VERSION "HNNBNNNYNNNNNNNNNNNNNNNNNNNNNNNNNNNNNNNNNN/4/%%%/4/'%**4NNN///"

NS_ :

BS_:

BU_: Airbag_D4 EPB_D4 ESP_D4 Gateway_D4C7 Getriebe_AL551_951_D4_C7 Getriebe_DL501_C7 Getriebe_VL381_C7 LWS_D4 Motor_EDC17_D4 Motor_ME17_BY Motor_MED17_SIMOS8_D4 Motor_Slave_D4 QSP_D4 SAK_C7 SCR_C7 SCU_D4

BO_ 267 LS_01: 4 Gateway_D4C7
 SG_ LS_01_CHK : 0|8@1+ (1,0) [0|255] ""  Getriebe_AL551_951_D4_C7,Getriebe_DL501_C7,Getriebe_VL381_C7,Motor_EDC17_D4,Motor_ME17_BY,Motor_MED17_SIMOS8_D4
 SG_ COUNTER : 8|4@1+ (1,0) [0|15] ""  Getriebe_AL551_951_D4_C7,Getriebe_DL501_C7,Getriebe_VL381_C7,Motor_EDC17_D4,Motor_ME17_BY,Motor_MED17_SIMOS8_D4
 SG_ LS_Hauptschalter : 12|1@1+ (1.0,0.0) [0.0|1] ""  Motor_EDC17_D4,Motor_ME17_BY,Motor_MED17_SIMOS8_D4
 SG_ LS_Abbrechen : 13|1@1+ (1.0,0.0) [0.0|1] ""  Motor_EDC17_D4,Motor_ME17_BY,Motor_MED17_SIMOS8_D4
 SG_ LS_Typ_Hauptschalter : 14|1@1+ (1.0,0.0) [0.0|1] ""  Motor_EDC17_D4,Motor_ME17_BY,Motor_MED17_SIMOS8_D4
 SG_ LS_Limiter : 15|1@1+ (1.0,0.0) [0.0|1] ""  Motor_EDC17_D4,Motor_ME17_BY,Motor_MED17_SIMOS8_D4
 SG_ LS_Tip_Setzen : 16|1@1+ (1.0,0.0) [0.0|1] ""  Getriebe_DL501_C7,Motor_EDC17_D4,Motor_ME17_BY,Motor_MED17_SIMOS8_D4
 SG_ LS_Tip_Hoch : 17|1@1+ (1.0,0.0) [0.0|1] ""  Getriebe_DL501_C7,Motor_EDC17_D4,Motor_ME17_BY,Motor_MED17_SIMOS8_D4
 SG_ LS_Tip_Runter : 18|1@1+ (1.0,0.0) [0.0|1] ""  Getriebe_DL501_C7,Motor_EDC17_D4,Motor_ME17_BY,Motor_MED17_SIMOS8_D4
 SG_ LS_Tip_Wiederaufnahme : 19|1@1+ (1.0,0.0) [0.0|1] ""  Getriebe_DL501_C7,Motor_EDC17_D4,Motor_ME17_BY,Motor_MED17_SIMOS8_D4
 SG_ LS_Verstellung_Zeitluecke : 20|2@1+ (1.0,0.0) [0.0|3] ""  Vector__XXX
 SG_ MFL_Tip_Down : 22|1@1+ (1.0,0.0) [0.0|1] ""  Getriebe_AL551_951_D4_C7,Getriebe_DL501_C7,Getriebe_VL381_C7
 SG_ MFL_Tip_Up : 23|1@1+ (1.0,0.0) [0.0|1] ""  Getriebe_AL551_951_D4_C7,Getriebe_DL501_C7,Getriebe_VL381_C7
 SG_ LS_Tiptronic_Fehler : 24|1@1+ (1.0,0.0) [0.0|1] ""  Getriebe_AL551_951_D4_C7,Getriebe_DL501_C7
 SG_ LS_Fehler : 25|1@1+ (1,0) [0|1] ""  Motor_EDC17_D4,Motor_ME17_BY,Motor_MED17_SIMOS8_D4
 SG_ LS_Codierung : 26|3@1+ (1.0,0.0) [0.0|7] ""  Motor_EDC17_D4,Motor_ME17_BY,Motor_MED17_SIMOS8_D4
 SG_ LS_Tip_Stufe_2 : 29|1@1+ (1.0,0.0) [0.0|1] ""  Motor_EDC17_D4,Motor_ME17_BY,Motor_MED17_SIMOS8_D4
 SG_ LS_GRA_ACC_2stufig : 30|1@1+ (1.0,0.0) [0.0|1] ""  Motor_EDC17_D4,Motor_ME17_BY,Motor_MED17_SIMOS8_D4
 SG_ MFL_M_Taste : 31|1@1+ (1.0,0.0) [0.0|1] ""  Getriebe_AL551_951_D4_C7

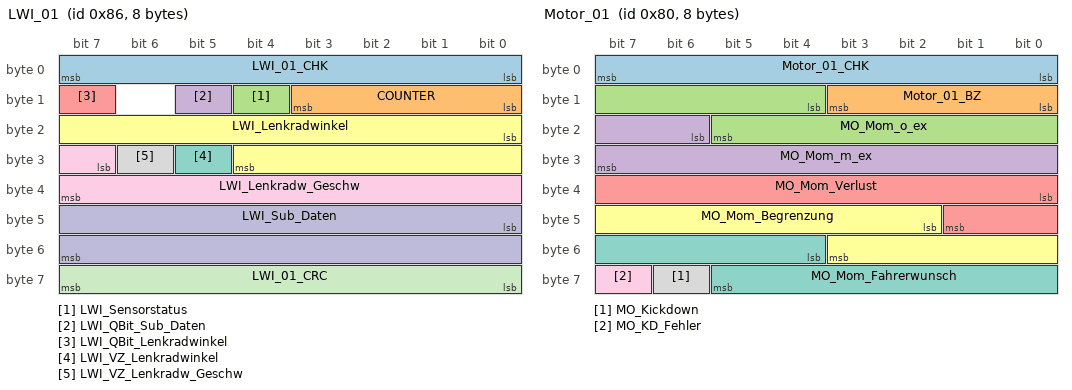
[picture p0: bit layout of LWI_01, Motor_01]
BO_ 134 LWI_01: 8 LWS_D4
 SG_ LWI_01_CHK : 0|8@1+ (1,0) [0|255] ""  ESP_D4,Gateway_D4C7,Getriebe_AL551_951_D4_C7,Getriebe_DL501_C7,Getriebe_VL381_C7,Motor_EDC17_D4,Motor_ME17_BY,Motor_MED17_SIMOS8_D4,QSP_D4,SCU_D4
 SG_ COUNTER : 8|4@1+ (1,0) [0|15] ""  Airbag_D4,ESP_D4,Gateway_D4C7,Getriebe_AL551_951_D4_C7,Getriebe_DL501_C7,Getriebe_VL381_C7,Motor_EDC17_D4,Motor_ME17_BY,Motor_MED17_SIMOS8_D4,QSP_D4,SCU_D4
 SG_ LWI_Sensorstatus : 12|1@1+ (1.0,0.0) [0.0|1] ""  ESP_D4,Gateway_D4C7,Getriebe_AL551_951_D4_C7,Motor_EDC17_D4,Motor_ME17_BY,Motor_MED17_SIMOS8_D4,QSP_D4,SCU_D4
 SG_ LWI_QBit_Sub_Daten : 13|1@1+ (1.0,0.0) [0.0|1] ""  ESP_D4,Gateway_D4C7,QSP_D4,SCU_D4
 SG_ LWI_QBit_Lenkradwinkel : 15|1@1+ (1.0,0.0) [0.0|1] ""  Airbag_D4,ESP_D4,Gateway_D4C7,Getriebe_AL551_951_D4_C7,Motor_EDC17_D4,Motor_ME17_BY,Motor_MED17_SIMOS8_D4,QSP_D4,SCU_D4
 SG_ LWI_Lenkradwinkel : 16|13@1+ (0.1,0) [0.0|800.0] "Unit_DegreOfArc"  Airbag_D4,ESP_D4,Gateway_D4C7,Getriebe_AL551_951_D4_C7,Getriebe_DL501_C7,Getriebe_VL381_C7,Motor_EDC17_D4,Motor_ME17_BY,Motor_MED17_SIMOS8_D4,QSP_D4,SCU_D4
 SG_ LWI_VZ_Lenkradwinkel : 29|1@1+ (1.0,0.0) [0.0|1] ""  Airbag_D4,ESP_D4,Gateway_D4C7,Getriebe_AL551_951_D4_C7,Motor_EDC17_D4,Motor_ME17_BY,Motor_MED17_SIMOS8_D4,QSP_D4,SCU_D4
 SG_ LWI_VZ_Lenkradw_Geschw : 30|1@1+ (1.0,0.0) [0.0|1] ""  Gateway_D4C7,QSP_D4
 SG_ LWI_Lenkradw_Geschw : 31|9@1+ (5,0) [0|2500] "Unit_DegreOfArcPerSecon"  Gateway_D4C7,QSP_D4
 SG_ LWI_Sub_Daten : 40|16@1+ (1,0) [0|65535] ""  ESP_D4,Gateway_D4C7,QSP_D4,SCU_D4
 SG_ LWI_01_CRC : 56|8@1+ (1,0) [0|255] ""  Airbag_D4,ESP_D4,Gateway_D4C7,QSP_D4,SCU_D4

BO_ 128 Motor_01: 8 Motor_EDC17_D4
 SG_ Motor_01_CHK : 0|8@1+ (1,0) [0|255] ""  EPB_D4,Gateway_D4C7,Getriebe_AL551_951_D4_C7,Getriebe_DL501_C7,Getriebe_VL381_C7
 SG_ Motor_01_BZ : 8|4@1+ (1,0) [0|15] ""  EPB_D4,Gateway_D4C7,Getriebe_AL551_951_D4_C7,Getriebe_DL501_C7,Getriebe_VL381_C7
 SG_ MO_Mom_o_ex : 12|10@1+ (1,0) [0|1021] ""  Gateway_D4C7,Getriebe_AL551_951_D4_C7,Getriebe_DL501_C7,Getriebe_VL381_C7
 SG_ MO_Mom_m_ex : 22|10@1+ (1,0) [0|1021] ""  EPB_D4,Gateway_D4C7,Getriebe_AL551_951_D4_C7,Getriebe_DL501_C7,Getriebe_VL381_C7,SAK_C7
 SG_ MO_Mom_Verlust : 32|10@1+ (1,0) [0|1021] ""  EPB_D4,Gateway_D4C7,Getriebe_AL551_951_D4_C7,Getriebe_DL501_C7,Getriebe_VL381_C7,SAK_C7
 SG_ MO_Mom_Begrenzung : 42|10@1+ (1,0) [0|1021] ""  Gateway_D4C7,Getriebe_AL551_951_D4_C7,Getriebe_DL501_C7,Getriebe_VL381_C7
 SG_ MO_Mom_Fahrerwunsch : 52|10@1+ (1,0) [0|1021] ""  Gateway_D4C7,Getriebe_AL551_951_D4_C7,Getriebe_DL501_C7,Getriebe_VL381_C7
 SG_ MO_Kickdown : 62|1@1+ (1.0,0.0) [0.0|1] ""  Gateway_D4C7,Getriebe_AL551_951_D4_C7,Getriebe_DL501_C7,Getriebe_VL381_C7
 SG_ MO_KD_Fehler : 63|1@1+ (1.0,0.0) [0.0|1] ""  Gateway_D4C7

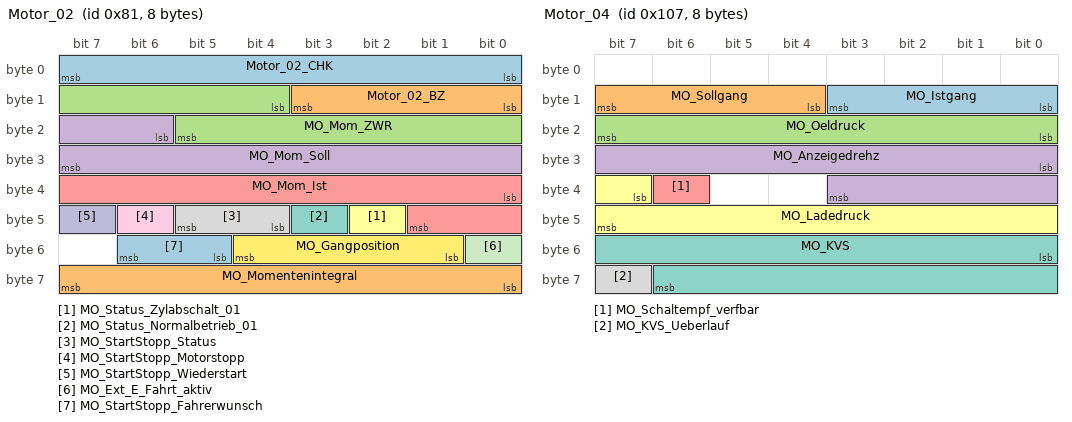
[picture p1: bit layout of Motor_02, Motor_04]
BO_ 129 Motor_02: 8 Motor_EDC17_D4
 SG_ Motor_02_CHK : 0|8@1+ (1,0) [0|255] ""  EPB_D4,Gateway_D4C7,Getriebe_AL551_951_D4_C7,Getriebe_DL501_C7,Getriebe_VL381_C7,SCU_D4
 SG_ Motor_02_BZ : 8|4@1+ (1,0) [0|15] ""  EPB_D4,Gateway_D4C7,Getriebe_AL551_951_D4_C7,Getriebe_DL501_C7,Getriebe_VL381_C7,SCU_D4
 SG_ MO_Mom_ZWR : 12|10@1+ (1,0) [0|1021] ""  Gateway_D4C7
 SG_ MO_Mom_Soll : 22|10@1+ (1,0) [0|1021] ""  Gateway_D4C7,Getriebe_AL551_951_D4_C7,Getriebe_DL501_C7,Getriebe_VL381_C7
 SG_ MO_Mom_Ist : 32|10@1+ (1,0) [0|1021] ""  Gateway_D4C7,Getriebe_AL551_951_D4_C7,Getriebe_DL501_C7,Getriebe_VL381_C7
 SG_ MO_Status_Zylabschalt_01 : 42|1@1+ (1.0,0.0) [0.0|1] ""  Gateway_D4C7,Getriebe_AL551_951_D4_C7
 SG_ MO_Status_Normalbetrieb_01 : 43|1@1+ (1.0,0.0) [0.0|1] ""  Gateway_D4C7,Getriebe_DL501_C7,Getriebe_VL381_C7
 SG_ MO_StartStopp_Status : 44|2@1+ (1.0,0.0) [0.0|3] ""  Gateway_D4C7,Getriebe_AL551_951_D4_C7,Getriebe_DL501_C7,Getriebe_VL381_C7,SCR_C7,SCU_D4
 SG_ MO_StartStopp_Motorstopp : 46|1@1+ (1.0,0.0) [0.0|1] ""  EPB_D4,Gateway_D4C7,Getriebe_AL551_951_D4_C7,Getriebe_DL501_C7,Getriebe_VL381_C7,SCR_C7,SCU_D4
 SG_ MO_StartStopp_Wiederstart : 47|1@1+ (1.0,0.0) [0.0|1] ""  EPB_D4,Gateway_D4C7,Getriebe_AL551_951_D4_C7,Getriebe_DL501_C7,Getriebe_VL381_C7,SCR_C7,SCU_D4
 SG_ MO_Ext_E_Fahrt_aktiv : 48|1@1+ (1.0,0.0) [0.0|1] ""  Gateway_D4C7
 SG_ MO_Gangposition : 49|4@1+ (1.0,0.0) [0.0|15] ""  Gateway_D4C7
 SG_ MO_StartStopp_Fahrerwunsch : 53|2@1+ (1.0,0.0) [0.0|3] ""  Gateway_D4C7
 SG_ MO_Momentenintegral : 56|8@1+ (0.3921,0) [0.0000|99.9855] ""  Gateway_D4C7,Getriebe_AL551_951_D4_C7,Getriebe_DL501_C7,Getriebe_VL381_C7

BO_ 261 Motor_03: 8 Motor_EDC17_D4
 SG_ MOTOR_03_CHK : 0|8@1+ (1,0) [0|255] ""  EPB_D4,Gateway_D4C7,Getriebe_AL551_951_D4_C7,Getriebe_DL501_C7,Getriebe_VL381_C7,SCU_D4
 SG_ COUNTER : 8|4@1+ (1,0) [0|15] ""  EPB_D4,Gateway_D4C7,Getriebe_AL551_951_D4_C7,Getriebe_DL501_C7,Getriebe_VL381_C7,SCU_D4
 SG_ MO_QBit_Fahrpedalwerte_01 : 12|1@1+ (1.0,0.0) [0.0|1] ""  EPB_D4,Gateway_D4C7,Getriebe_AL551_951_D4_C7,Getriebe_DL501_C7,Getriebe_VL381_C7
 SG_ MO_QBit_Motormomente : 13|1@1+ (1.0,0.0) [0.0|1] ""  EPB_D4,Gateway_D4C7,Getriebe_AL551_951_D4_C7,Getriebe_DL501_C7,Getriebe_VL381_C7
 SG_ MO_QBit_Fahrer_bremst : 14|1@1+ (1.0,0.0) [0.0|1] ""  Gateway_D4C7,Getriebe_AL551_951_D4_C7,Getriebe_DL501_C7,Getriebe_VL381_C7
 SG_ MO_QBit_Drehzahl_01 : 15|1@1+ (1.0,0.0) [0.0|1] ""  EPB_D4,Gateway_D4C7,Getriebe_AL551_951_D4_C7,Getriebe_DL501_C7,Getriebe_VL381_C7,SCR_C7
 SG_ MO_Drehzahl_01 : 16|16@1+ (0.25,0) [0.00|16383.00] "Unit_MinutInver"  EPB_D4,Gateway_D4C7,Getriebe_AL551_951_D4_C7,Getriebe_DL501_C7,Getriebe_VL381_C7,SAK_C7,SCR_C7,SCU_D4
 SG_ MO_Moment_im_Leerlauf : 32|1@1+ (1.0,0.0) [0.0|1] ""  Gateway_D4C7
 SG_ MO_Interlock : 33|1@1+ (1.0,0.0) [0.0|1] ""  EPB_D4,Gateway_D4C7
 SG_ MO_BLS : 34|1@1+ (1.0,0.0) [0.0|1] ""  EPB_D4,Gateway_D4C7,Getriebe_AL551_951_D4_C7,Getriebe_DL501_C7,Getriebe_VL381_C7
 SG_ MO_Fahrer_bremst : 35|1@1+ (1.0,0.0) [0.0|1] ""  Gateway_D4C7,Getriebe_AL551_951_D4_C7,Getriebe_DL501_C7,Getriebe_VL381_C7
 SG_ MO_Konsistenz_Bremsped : 36|1@1+ (1.0,0.0) [0.0|1] ""  Gateway_D4C7,Getriebe_AL551_951_D4_C7,Getriebe_DL501_C7,Getriebe_VL381_C7
 SG_ MO_Kuppl_schalter : 37|1@1+ (1.0,0.0) [0.0|1] ""  EPB_D4,Gateway_D4C7
 SG_ MO_Timeout_ESP : 38|1@1+ (1.0,0.0) [0.0|1] ""  Gateway_D4C7
 SG_ MO_Motor_laeuft : 39|1@1+ (1.0,0.0) [0.0|1] ""  Gateway_D4C7
 SG_ MO_Solldrehz_Leerlauf : 40|8@1+ (10,0) [0|2540] "Unit_MinutInver"  Gateway_D4C7,Getriebe_AL551_951_D4_C7,Getriebe_DL501_C7,Getriebe_VL381_C7
 SG_ MO_Fahrpedalrohwert_01 : 48|8@1+ (0.4,0) [0.0|101.6] "Unit_PerCent"  EPB_D4,Gateway_D4C7,Getriebe_AL551_951_D4_C7,Getriebe_DL501_C7,Getriebe_VL381_C7
 SG_ MO_erste_Ungenauschwelle : 56|1@1+ (1.0,0.0) [0.0|1] ""  Gateway_D4C7,Getriebe_AL551_951_D4_C7,Getriebe_DL501_C7,Getriebe_VL381_C7
 SG_ MO_QBit_Stressfaktor : 57|1@1+ (1.0,0.0) [0.0|1] ""  Gateway_D4C7,Getriebe_AL551_951_D4_C7,Getriebe_DL501_C7,Getriebe_VL381_C7
 SG_ MO_Stressfaktor : 58|6@1+ (1.6,0) [0.0|100.8] "Unit_PerCent"  Gateway_D4C7,Getriebe_AL551_951_D4_C7,Getriebe_DL501_C7,Getriebe_VL381_C7

BO_ 263 Motor_04: 8 Motor_EDC17_D4
 SG_ MO_Istgang : 8|4@1+ (1.0,0.0) [0.0|15] ""  Gateway_D4C7
 SG_ MO_Sollgang : 12|4@1+ (1.0,0.0) [0.0|15] ""  Gateway_D4C7
 SG_ MO_Oeldruck : 16|8@1+ (0.04,0) [0.00|10.00] "Unit_Bar"  Gateway_D4C7
 SG_ MO_Anzeigedrehz : 24|12@1+ (3,0) [0|12282] "Unit_MinutInver"  Gateway_D4C7
 SG_ MO_Schaltempf_verfbar : 38|1@1+ (1.0,0.0) [0.0|1] ""  Gateway_D4C7
 SG_ MO_Ladedruck : 39|9@1+ (0.01,0) [0.00|5.10] "Unit_Bar"  Gateway_D4C7
 SG_ MO_KVS : 48|15@1+ (1,0) [0|32767] "Unit_MicroLiter"  Gateway_D4C7
 SG_ MO_KVS_Ueberlauf : 63|1@1+ (1.0,0.0) [0.0|1] ""  Gateway_D4C7

BO_ 782 Motor_05: 8 Motor_EDC17_D4
 SG_ Motor_05_CHK : 0|8@1+ (1,0) [0|255] ""  Gateway_D4C7,Getriebe_AL551_951_D4_C7,Getriebe_DL501_C7,Getriebe_VL381_C7
 SG_ Motor_05_BZ : 8|4@1+ (1,0) [0|15] ""  Gateway_D4C7,Getriebe_AL551_951_D4_C7,Getriebe_DL501_C7,Getriebe_VL381_C7
 SG_ MO_EKlKomLeiRed : 12|2@1+ (1.0,0.0) [0.0|3] ""  Gateway_D4C7
 SG_ MO_Freig_Reku : 14|2@1+ (1.0,0.0) [0.0|3] ""  Gateway_D4C7
 SG_ MO_Klima_Eingr : 16|2@1+ (1.0,0.0) [0.0|3] ""  Gateway_D4C7
 SG_ MO_Status_Normalbetrieb_02 : 18|1@1+ (1.0,0.0) [0.0|1] ""  Gateway_D4C7
 SG_ MO_Schaltbeeinfl_Leistungsbegr : 19|1@1+ (1,0) [0|1] ""  Gateway_D4C7,Getriebe_AL551_951_D4_C7,Getriebe_DL501_C7
 SG_ MO_Schaltbeeinfl_Partikelfilter : 20|1@1+ (1,0) [0|1] ""  Gateway_D4C7,Getriebe_AL551_951_D4_C7,Getriebe_DL501_C7
 SG_ MO_Prio_MIN_Wunschdrehzahl : 21|1@1+ (1.0,0.0) [0.0|1] ""  Gateway_D4C7,Getriebe_AL551_951_D4_C7,Getriebe_DL501_C7,Getriebe_VL381_C7
 SG_ MO_Freig_Anlass : 22|1@1+ (1.0,0.0) [0.0|1] ""  Gateway_D4C7
 SG_ MO_Aussp_Anlass : 23|1@1+ (1.0,0.0) [0.0|1] ""  Gateway_D4C7
 SG_ MO_MAX_Wunschdrehzahl : 24|9@1+ (25,0) [0|12750] "Unit_MinutInver"  Gateway_D4C7,Getriebe_AL551_951_D4_C7,Getriebe_DL501_C7,Getriebe_VL381_C7
 SG_ MO_Prio_MAX_Wunschdrehzahl : 33|1@1+ (1.0,0.0) [0.0|1] ""  Gateway_D4C7,Getriebe_AL551_951_D4_C7,Getriebe_DL501_C7,Getriebe_VL381_C7
 SG_ MO_Luftpfad_aktiv : 34|1@1+ (1.0,0.0) [0.0|1] ""  Gateway_D4C7,Getriebe_AL551_951_D4_C7,Getriebe_DL501_C7
 SG_ MO_v_Begrenz_Aktiv : 35|1@1+ (1.0,0.0) [0.0|1] ""  Gateway_D4C7
 SG_ MO_v_Begrenz_Aktivierbar : 36|1@1+ (1.0,0.0) [0.0|1] ""  Gateway_D4C7
 SG_ MO_Verbot_EKP : 37|1@1+ (1.0,0.0) [0.0|1] ""  Gateway_D4C7
 SG_ MO_Anf_Pruefimpuls : 38|1@1+ (1.0,0.0) [0.0|1] ""  Gateway_D4C7
 SG_ MO_Anf_KL75 : 39|1@1+ (1.0,0.0) [0.0|1] ""  Gateway_D4C7
 SG_ MO_Charisma_FahrPr : 40|3@1+ (1.0,0.0) [0.0|7] ""  Gateway_D4C7
 SG_ MO_Charisma_Status : 43|2@1+ (1.0,0.0) [0.0|3] ""  Gateway_D4C7
 SG_ MO_Charisma_Umschaltung : 45|2@1+ (1.0,0.0) [0.0|3] ""  Gateway_D4C7
 SG_ MO_Handshake_STH : 47|1@1+ (1.0,0.0) [0.0|1] ""  Gateway_D4C7
 SG_ MO_MIN_Wunschdrehzahl : 48|8@1+ (25,0) [0|6350] "Unit_MinutInver"  Gateway_D4C7,Getriebe_AL551_951_D4_C7,Getriebe_DL501_C7,Getriebe_VL381_C7
 SG_ MO_Drehzahlbeeinflussung : 56|8@1+ (0.39,0) [0.00|99.45] "Unit_PerCent"  Gateway_D4C7,Getriebe_AL551_951_D4_C7,Getriebe_DL501_C7,Getriebe_VL381_C7

BO_ 1088 Motor_06: 8 Motor_EDC17_D4
 SG_ MO_Kuehlerluefter_MUX M  : 0|1@1+ (1.0,0.0) [0.0|1] ""  Gateway_D4C7
 SG_ MO_Kuehlerluefter_1 m0  : 1|7@1+ (1,0) [0|100] "Unit_PerCent"  Gateway_D4C7
 SG_ MO_Kuehlerluefter_2 m1  : 1|7@1+ (1,0) [0|100] "Unit_PerCent"  Gateway_D4C7
 SG_ MO_HYB_Status_HV_Ladung : 8|3@1+ (1.0,0.0) [0.0|7] ""  Gateway_D4C7
 SG_ WIV_Anzeige_aktiv : 12|1@1+ (1.0,0.0) [0.0|1] ""  Gateway_D4C7
 SG_ WIV_Oelmin_Warn : 13|1@1+ (1.0,0.0) [0.0|1] ""  Gateway_D4C7
 SG_ WIV_Sensorfehler : 14|1@1+ (1.0,0.0) [0.0|1] ""  Gateway_D4C7
 SG_ WIV_Schieflage : 15|1@1+ (1.0,0.0) [0.0|1] ""  Gateway_D4C7
 SG_ WIV_Oelstand : 16|4@1+ (12.5,0) [0.0|100.0] "Unit_PerCent"  Gateway_D4C7
 SG_ MO_Zustand_HWP : 20|2@1+ (1.0,0.0) [0.0|3] ""  Gateway_D4C7
 SG_ WIV_Oelsystem_aktiv : 24|1@1+ (1.0,0.0) [0.0|1] ""  Gateway_D4C7
 SG_ WIV_nicht_betriebswarm : 25|1@1+ (1.0,0.0) [0.0|1] ""  Gateway_D4C7
 SG_ WIV_Ueberfuell_Warn : 26|1@1+ (1.0,0.0) [0.0|1] ""  Gateway_D4C7
 SG_ WIV_laufender_Motor : 27|1@1+ (1.0,0.0) [0.0|1] ""  Gateway_D4C7
 SG_ MO_HYB_Text_1 : 28|1@1+ (1.0,0.0) [0.0|1] ""  Gateway_D4C7
 SG_ MO_HYB_Text_2 : 29|1@1+ (1.0,0.0) [0.0|1] ""  Gateway_D4C7
 SG_ MO_HYB_Text_3 : 30|1@1+ (1.0,0.0) [0.0|1] ""  Gateway_D4C7
 SG_ MO_Text_Motorstart : 32|4@1+ (1.0,0.0) [0.0|15] ""  Gateway_D4C7
 SG_ MO_HYB_Text_5 : 36|1@1+ (1.0,0.0) [0.0|1] ""  Gateway_D4C7
 SG_ MO_HYB_Text_6 : 37|1@1+ (1.0,0.0) [0.0|1] ""  Gateway_D4C7
 SG_ MO_HYB_Text_7 : 38|1@1+ (1.0,0.0) [0.0|1] ""  Gateway_D4C7
 SG_ WIV_Oeldyn_avl : 39|1@1+ (1.0,0.0) [0.0|1] ""  Gateway_D4C7
 SG_ MO_Text_MSG_Werkstatt : 40|1@1+ (1,0) [0|1] ""  Gateway_D4C7
 SG_ MO_Text_Partikelfil_Reg : 41|1@1+ (1,0) [0|1] ""  Gateway_D4C7
 SG_ MO_Text_Fehler_Kraftstoffsys : 42|1@1+ (1,0) [0|1] ""  Gateway_D4C7
 SG_ WIV_Oelmenge : 43|5@1+ (125,0) [0|3875] "Unit_MilliLiter"  Gateway_D4C7
 SG_ MO_Systemlampe : 48|1@1+ (1.0,0.0) [0.0|1] ""  Gateway_D4C7
 SG_ MO_OBD2_Lampe : 49|1@1+ (1.0,0.0) [0.0|1] ""  Gateway_D4C7
 SG_ MO_Heissleuchte : 50|1@1+ (1.0,0.0) [0.0|1] ""  Gateway_D4C7
 SG_ MO_Partikel_Lampe : 51|1@1+ (1.0,0.0) [0.0|1] ""  Gateway_D4C7
 SG_ MO_Winterfahrprog : 52|1@1+ (1,0) [0|1] ""  Gateway_D4C7
 SG_ WIV_Oelstand_nicht_vorhanden : 53|1@1+ (1.0,0.0) [0.0|1] ""  Gateway_D4C7
 SG_ WIV_nachfuellanzeige_ein : 54|1@1+ (1.0,0.0) [0.0|1] ""  Gateway_D4C7
 SG_ WIV_Ueberfuell_deaktiv : 55|1@1+ (1.0,0.0) [0.0|1] ""  Gateway_D4C7
 SG_ WIV_Unterfuell_Warn : 56|1@1+ (1.0,0.0) [0.0|1] ""  Gateway_D4C7
 SG_ MO_Tankdeckel_Lampe : 57|1@1+ (1.0,0.0) [0.0|1] ""  Gateway_D4C7
 SG_ MO_Text_Tankdeckelwarn : 58|1@1+ (1.0,0.0) [0.0|1] ""  Gateway_D4C7
 SG_ WIV_Enable_Oeldr_Motor : 59|1@1+ (1.0,0.0) [0.0|1] ""  Gateway_D4C7
 SG_ WIV_Oeldr_Warn_Motor : 60|1@1+ (1.0,0.0) [0.0|1] ""  Gateway_D4C7
 SG_ MO_Avus_Motorschutz : 61|2@1+ (1.0,0.0) [0.0|3] ""  Gateway_D4C7
 SG_ MO_HYB_Fahrbereitschaft : 63|1@1+ (1.0,0.0) [0.0|1] ""  Gateway_D4C7

BO_ 1600 Motor_07: 8 Motor_EDC17_D4
 SG_ MO_QBit_Ansaugluft_Temp : 0|1@1+ (1.0,0.0) [0.0|1] ""  Gateway_D4C7,Getriebe_AL551_951_D4_C7,Getriebe_DL501_C7,Getriebe_VL381_C7
 SG_ MO_QBit_Oel_Temp : 1|1@1+ (1.0,0.0) [0.0|1] ""  Gateway_D4C7,Getriebe_AL551_951_D4_C7
 SG_ MO_QBit_Kuehlmittel_Temp : 2|1@1+ (1.0,0.0) [0.0|1] ""  Gateway_D4C7,Getriebe_AL551_951_D4_C7,Getriebe_DL501_C7,Getriebe_VL381_C7
 SG_ MO_Stellgliedtest_Soundaktuator : 3|1@1+ (1.0,0.0) [0.0|1] ""  Gateway_D4C7
 SG_ MO_HYB_Fehler_HV_Netz : 4|1@1+ (1.0,0.0) [0.0|1] ""  Gateway_D4C7
 SG_ MO_aktives_Getriebeheizen : 5|1@1+ (1.0,0.0) [0.0|1] ""  Gateway_D4C7,Getriebe_AL551_951_D4_C7,Getriebe_DL501_C7,Getriebe_VL381_C7
 SG_ MO_Absperrventil_oeffnen : 6|2@1+ (1.0,0.0) [0.0|3] ""  Gateway_D4C7
 SG_ MO_Ansaugluft_Temp : 8|8@1+ (0.75,-48) [-48.00|141.75] "Unit_DegreCelsi"  Gateway_D4C7,Getriebe_AL551_951_D4_C7,Getriebe_DL501_C7,Getriebe_VL381_C7
 SG_ MO_Oel_Temp : 16|8@1+ (1,-60) [-60|192] "Unit_DegreCelsi"  Gateway_D4C7,Getriebe_AL551_951_D4_C7
 SG_ MO_Kuehlmittel_Temp : 24|8@1+ (0.75,-48) [-48.00|141.75] "Unit_DegreCelsi"  Gateway_D4C7,Getriebe_AL551_951_D4_C7,Getriebe_DL501_C7,Getriebe_VL381_C7
 SG_ MO_Hoeheninfo : 32|8@1+ (0.00781,0) [0.00000|1.98374] ""  Gateway_D4C7,Getriebe_AL551_951_D4_C7,Getriebe_DL501_C7,Getriebe_VL381_C7
 SG_ MO_Kennfeldk : 40|1@1+ (1.0,0.0) [0.0|1] ""  Gateway_D4C7
 SG_ MO_Versionsinfo : 41|6@1+ (1.0,0.0) [0.0|63] ""  Gateway_D4C7
 SG_ MO_Getriebe_kuehlen : 47|1@1+ (1.0,0.0) [0.0|1] ""  Gateway_D4C7,Getriebe_AL551_951_D4_C7,Getriebe_DL501_C7,Getriebe_VL381_C7
 SG_ MO_Mom_Traegheit_02 : 48|5@1+ (0.01,0) [0.00|0.31] "Unit_KiloGramMeterSquar"  Gateway_D4C7,Getriebe_AL551_951_D4_C7,Getriebe_DL501_C7,Getriebe_VL381_C7
 SG_ MO_Heizungspumpenansteuerung : 53|4@1+ (10,0) [0|100] "Unit_PerCent"  Gateway_D4C7
 SG_ MO_SpannungsAnf : 57|1@1+ (1.0,0.0) [0.0|1] ""  Gateway_D4C7
 SG_ MO_Nachlaufzeit_Heizungspumpe : 58|6@1+ (15,0) [0|945] "Unit_Secon"  Gateway_D4C7

BO_ 1607 Motor_09: 8 Motor_EDC17_D4
 SG_ MO_ITM_Kuehlmittel_Temp : 0|8@1+ (0.75,-48) [-45.75|143.25] "Unit_DegreCelsi"  Gateway_D4C7
 SG_ MO_E85_Sensor : 8|4@1+ (10,0) [0|100] "Unit_PerCent"  Gateway_D4C7
 SG_ SCR_Anz_Motorstarts : 12|4@1+ (1,0) [0|8] ""  Gateway_D4C7
 SG_ SCR_Reichweite : 16|15@1+ (1,0) [0|32766] ""  Gateway_D4C7
 SG_ SCR_Warnstufe_1 : 32|1@1+ (1.0,0.0) [0.0|1] ""  Gateway_D4C7
 SG_ SCR_Warnstufe_2 : 33|1@1+ (1.0,0.0) [0.0|1] ""  Gateway_D4C7
 SG_ SCR_Text : 34|3@1+ (1.0,0.0) [0.0|7] ""  Gateway_D4C7
 SG_ SCR_Akustik : 37|2@1+ (1.0,0.0) [0.0|3] ""  Gateway_D4C7
 SG_ MO_Kraftstofffilter_Wasser : 40|1@1+ (1.0,0.0) [0.0|1] ""  Gateway_D4C7
 SG_ SCR_Systemfehler : 41|1@1+ (1.0,0.0) [0.0|1] ""  Gateway_D4C7
 SG_ SCR_Inducement_Strategie : 42|2@1+ (1.0,0.0) [0.0|3] ""  Gateway_D4C7
 SG_ MO_CO2_Faktor : 44|12@1+ (1,0) [1|4094] "Unit_GramPerLiter"  Gateway_D4C7
 SG_ MO_MKB_MUX M  : 56|2@1+ (1.0,0.0) [0.0|3] ""  Gateway_D4C7
 SG_ MO_MKB_01 m0  : 59|5@1+ (1.0,0.0) [0.0|31] ""  Gateway_D4C7
 SG_ MO_MKB_02 m1  : 59|5@1+ (1.0,0.0) [0.0|31] ""  Gateway_D4C7
 SG_ MO_MKB_03 m2  : 59|5@1+ (1.0,0.0) [0.0|31] ""  Gateway_D4C7
 SG_ MO_MKB_04 m3  : 59|5@1+ (1.0,0.0) [0.0|31] ""  Gateway_D4C7

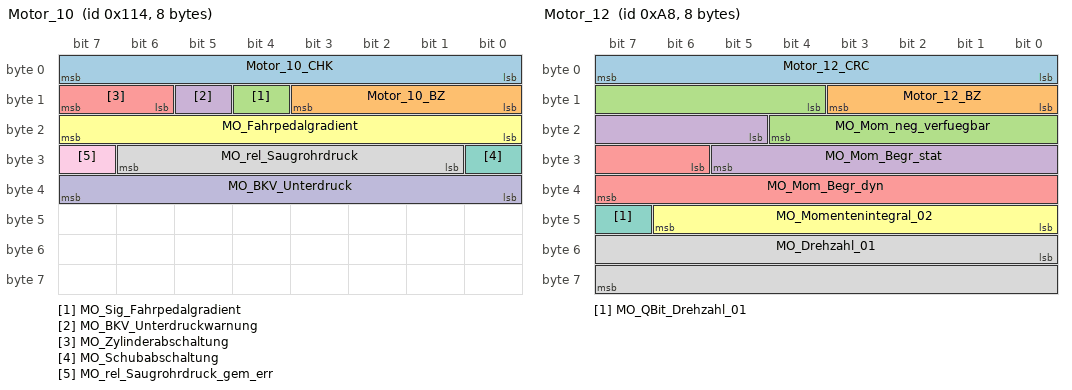
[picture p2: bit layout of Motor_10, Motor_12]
BO_ 276 Motor_10: 8 Motor_EDC17_D4
 SG_ Motor_10_CHK : 0|8@1+ (1,0) [0|255] ""  Gateway_D4C7
 SG_ Motor_10_BZ : 8|4@1+ (1,0) [0|15] ""  Gateway_D4C7
 SG_ MO_Sig_Fahrpedalgradient : 12|1@1+ (1.0,0.0) [0.0|1] ""  Gateway_D4C7
 SG_ MO_BKV_Unterdruckwarnung : 13|1@1+ (1.0,0.0) [0.0|1] ""  Gateway_D4C7
 SG_ MO_Zylinderabschaltung : 14|2@1+ (1.0,0.0) [0.0|3] ""  Gateway_D4C7,Getriebe_AL551_951_D4_C7,Getriebe_DL501_C7
 SG_ MO_Fahrpedalgradient : 16|8@1+ (25,0) [0|6350] "Unit_PerCentPerSecon"  Gateway_D4C7
 SG_ MO_Schubabschaltung : 24|1@1+ (1.0,0.0) [0.0|1] ""  Gateway_D4C7
 SG_ MO_rel_Saugrohrdruck : 25|6@1+ (18,0) [0|1116] "Unit_MilliBar"  Gateway_D4C7
 SG_ MO_rel_Saugrohrdruck_gem_err : 31|1@1+ (1.0,0.0) [0.0|1] ""  Gateway_D4C7
 SG_ MO_BKV_Unterdruck : 32|8@1+ (4,0) [0|1012] "Unit_MilliBar"  Gateway_D4C7

BO_ 168 Motor_12: 8 Motor_MLB_C7_PHEV
 SG_ Motor_12_CRC : 0|8@1+ (1,0) [0|255] ""  Gateway
 SG_ Motor_12_BZ : 8|4@1+ (1,0) [0|15] ""  Gateway
 SG_ MO_Mom_neg_verfuegbar : 12|9@1+ (1,-509) [-509|0] ""  Gateway
 SG_ MO_Mom_Begr_stat : 21|9@1+ (1,0) [0|509] ""  Gateway
 SG_ MO_Mom_Begr_dyn : 30|10@1+ (1,-509) [-509|509] ""  Gateway
 SG_ MO_Momentenintegral_02 : 40|7@1+ (1,0) [0|100] "Unit_PerCent"  Gateway
 SG_ MO_QBit_Drehzahl_01 : 47|1@1+ (1,0) [0|1] ""  Gateway
 SG_ MO_Drehzahl_01 : 48|16@1+ (0.25,0) [0|16383] "Unit_MinutInver"  Gateway

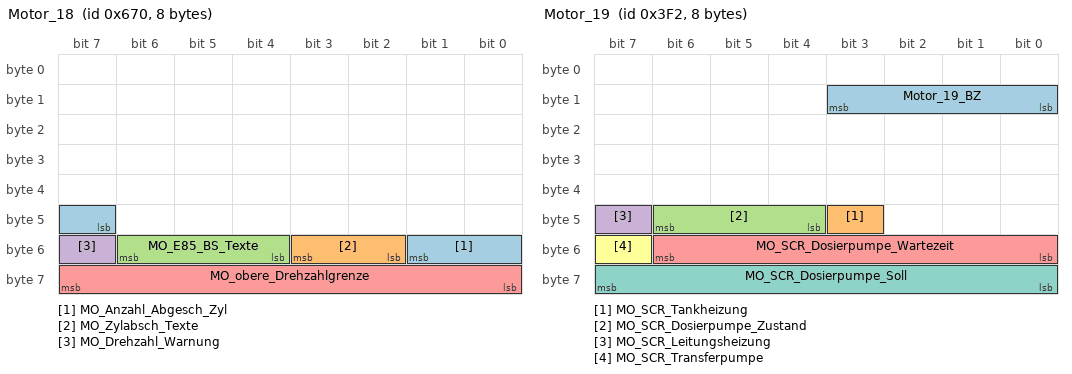
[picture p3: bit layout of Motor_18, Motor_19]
BO_ 1648 Motor_18: 8 Motor_EDC17_D4
 SG_ MO_Anzahl_Abgesch_Zyl : 47|3@1+ (1.0,0.0) [0.0|7] ""  Gateway_D4C7,Getriebe_AL551_951_D4_C7,Getriebe_DL501_C7
 SG_ MO_Zylabsch_Texte : 50|2@1+ (1.0,0.0) [0.0|3] ""  Gateway_D4C7
 SG_ MO_E85_BS_Texte : 52|3@1+ (1.0,0.0) [0.0|7] ""  Gateway_D4C7
 SG_ MO_Drehzahl_Warnung : 55|1@1+ (1.0,0.0) [0.0|1] ""  Gateway_D4C7
 SG_ MO_obere_Drehzahlgrenze : 56|8@1+ (50,0) [50|12750] "Unit_MinutInver"  Gateway_D4C7

BO_ 1010 Motor_19: 8 Motor_EDC17_D4
 SG_ Motor_19_BZ : 8|4@1+ (1,0) [0|15] ""  SCR_C7
 SG_ MO_SCR_Tankheizung : 43|1@1+ (1.0,0.0) [0.0|1] ""  SCR_C7
 SG_ MO_SCR_Dosierpumpe_Zustand : 44|3@1+ (1.0,0.0) [0.0|7] ""  SCR_C7
 SG_ MO_SCR_Leitungsheizung : 47|1@1+ (1.0,0.0) [0.0|1] ""  SCR_C7
 SG_ MO_SCR_Dosierpumpe_Wartezeit : 48|7@1+ (1,0) [0|120] "Unit_Secon"  SCR_C7
 SG_ MO_SCR_Transferpumpe : 55|1@1+ (1.0,0.0) [0.0|1] ""  SCR_C7
 SG_ MO_SCR_Dosierpumpe_Soll : 56|8@1+ (0.4,0) [0.0|100.0] "Unit_PerCent"  SCR_C7

BO_ 815 Motor_23: 8 Motor_MLB_AU64_AU57_Diesel
 SG_ MO_Antriebsstrang_Warnung_HS : 46|2@1+ (1,0) [0|3] ""  Gateway
 SG_ MO_Anzeige_Verbrauch : 48|16@1+ (0.005,0) [0|327.675] "Unit_LiterPerHour"  Gateway

BO_ 1391 Motor_25: 8 Motor_MLB_AU64_AU57_Diesel
 SG_ MO_IstLeistung_EKAT : 41|7@1+ (20,0) [0|2500] "Unit_Watt"  Gateway
 SG_ MO_HYB_Drehzahl_VM : 48|16@1+ (0.25,0) [0|16256] "Unit_MinutInver"  Gateway,Getriebe_AL551_Hybrid_D4_C7

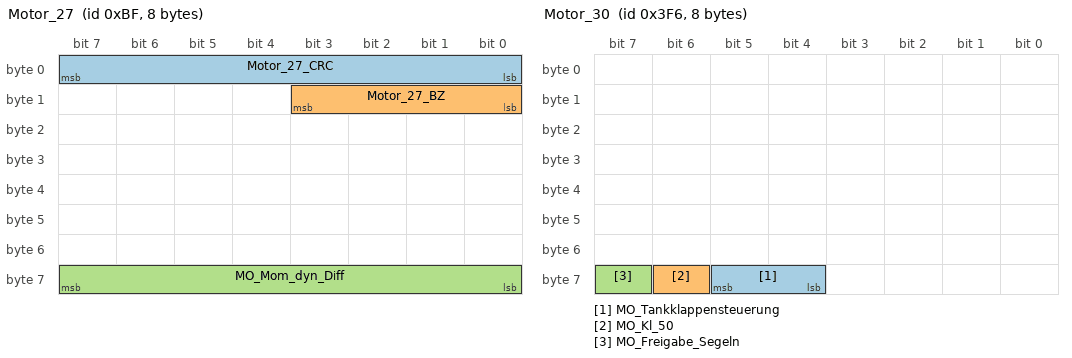
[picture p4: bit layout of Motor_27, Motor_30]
BO_ 191 Motor_27: 8 Motor_MLB_AU64_AU57_Diesel
 SG_ Motor_27_CRC : 0|8@1+ (1,0) [0|255] ""  Getriebe_AL551_951_D4_C7,Getriebe_AL551_Hybrid_D4_C7,Getriebe_DL382_MLB,Getriebe_DL501_MLB,Getriebe_VL381_MLB
 SG_ Motor_27_BZ : 8|4@1+ (1,0) [0|15] ""  Getriebe_AL551_951_D4_C7,Getriebe_AL551_Hybrid_D4_C7,Getriebe_DL382_MLB,Getriebe_DL501_MLB,Getriebe_VL381_MLB
 SG_ MO_Mom_dyn_Diff : 56|8@1+ (1,-25) [-25|229] "Unit_NewtoMeter"  Getriebe_AL551_951_D4_C7,Getriebe_AL551_Hybrid_D4_C7,Getriebe_DL382_MLB,Getriebe_DL501_MLB,Getriebe_VL381_MLB

BO_ 1014 Motor_30: 8 Motor_MLB_AU64_AU57_Diesel
 SG_ MO_Tankklappensteuerung : 60|2@1+ (1,0) [0|3] ""  Gateway
 SG_ MO_Kl_50 : 62|1@1+ (1,0) [0|1] ""  Getriebe_AL551_951_D4_C7
 SG_ MO_Freigabe_Segeln : 63|1@1+ (1,0) [0|1] ""  Getriebe_AL551_951_D4_C7,Getriebe_DL382_MLB,Getriebe_DL501_MLB

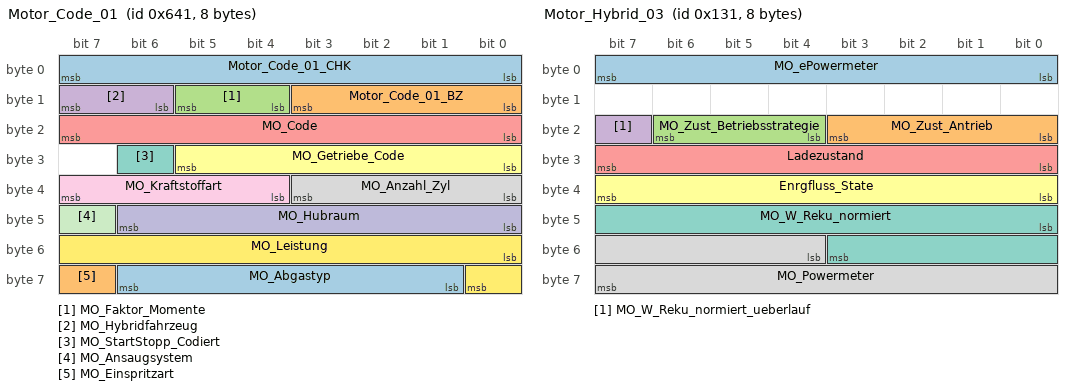
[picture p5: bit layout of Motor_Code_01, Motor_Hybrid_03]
BO_ 1601 Motor_Code_01: 8 Motor_EDC17_D4
 SG_ Motor_Code_01_CHK : 0|8@1+ (1,0) [0|255] ""  Gateway_D4C7,Getriebe_AL551_951_D4_C7,Getriebe_DL501_C7,Getriebe_VL381_C7
 SG_ Motor_Code_01_BZ : 8|4@1+ (1,0) [0|15] ""  Gateway_D4C7,Getriebe_AL551_951_D4_C7,Getriebe_DL501_C7,Getriebe_VL381_C7
 SG_ MO_Faktor_Momente : 12|2@1+ (1.0,0.0) [0.0|3] ""  EPB_D4,Gateway_D4C7,Getriebe_AL551_951_D4_C7,Getriebe_DL501_C7,Getriebe_VL381_C7
 SG_ MO_Hybridfahrzeug : 14|2@1+ (1.0,0.0) [0.0|3] ""  Gateway_D4C7
 SG_ MO_Code : 16|8@1+ (1,0) [0|255] ""  EPB_D4,Gateway_D4C7,Getriebe_AL551_951_D4_C7,Getriebe_DL501_C7,Getriebe_VL381_C7,SAK_C7
 SG_ MO_Getriebe_Code : 24|6@1+ (1.0,0.0) [0.0|63] ""  EPB_D4,Gateway_D4C7,Getriebe_AL551_951_D4_C7,Getriebe_DL501_C7,Getriebe_VL381_C7
 SG_ MO_StartStopp_Codiert : 30|1@1+ (1.0,0.0) [0.0|1] ""  Gateway_D4C7
 SG_ MO_Anzahl_Zyl : 32|4@1+ (1,0) [0|15] ""  Gateway_D4C7
 SG_ MO_Kraftstoffart : 36|4@1+ (1.0,0.0) [0.0|15] ""  EPB_D4,Gateway_D4C7
 SG_ MO_Hubraum : 40|7@1+ (0.1,0) [0.0|12.7] "Unit_Liter"  Gateway_D4C7
 SG_ MO_Ansaugsystem : 47|1@1+ (1.0,0.0) [0.0|1] ""  EPB_D4,Gateway_D4C7
 SG_ MO_Leistung : 48|9@1+ (1,0) [0|511] "Unit_KiloWatt"  Gateway_D4C7
 SG_ MO_Abgastyp : 57|6@1+ (1.0,0.0) [0.0|63] ""  Gateway_D4C7,Getriebe_AL551_951_D4_C7
 SG_ MO_Einspritzart : 63|1@1+ (1.0,0.0) [0.0|1] ""  Gateway_D4C7

BO_ 305 Motor_Hybrid_03: 8 Motor_MLB_C7_PHEV
 SG_ MO_ePowermeter : 0|8@1+ (0.4,-0.4) [0|100.8] "Unit_PerCent"  Gateway
 SG_ MO_Zust_Antrieb : 16|4@1+ (1,0) [0|15] ""  Gateway
 SG_ MO_Zust_Betriebsstrategie : 20|3@1+ (1,0) [0|7] ""  Gateway
 SG_ MO_W_Reku_normiert_ueberlauf : 23|1@1+ (1,0) [0|1] ""  Gateway
 SG_ Ladezustand : 24|8@1+ (1,0) [0|100] "Unit_PerCent"  Gateway
 SG_ Enrgfluss_State : 32|8@1+ (1,0) [0|255] ""  Gateway
 SG_ MO_W_Reku_normiert : 40|12@1+ (10,0) [0|40950] "Unit_WattSecond"  Gateway
 SG_ MO_Powermeter : 52|12@1+ (1,0) [0|4092] ""  Gateway

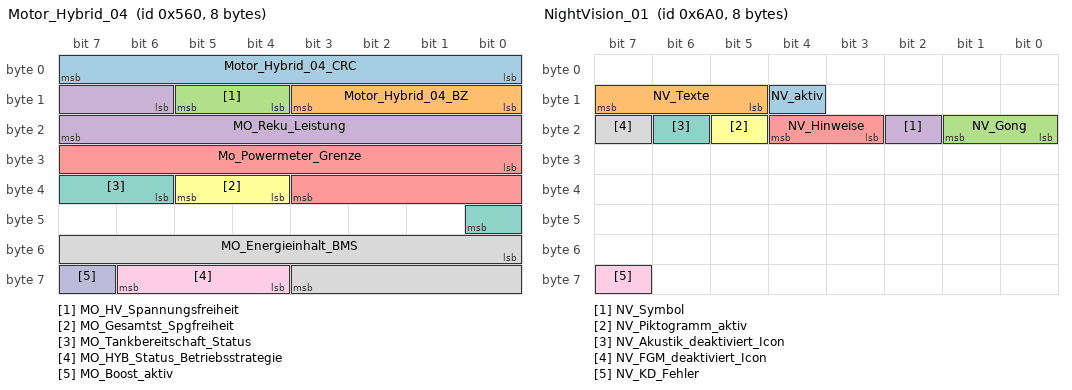
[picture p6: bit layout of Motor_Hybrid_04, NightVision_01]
BO_ 1376 Motor_Hybrid_04: 8 Motor_MLB_C7_PHEV
 SG_ Motor_Hybrid_04_CRC : 0|8@1+ (1,0) [0|255] ""  Gateway
 SG_ Motor_Hybrid_04_BZ : 8|4@1+ (1,0) [0|15] ""  Gateway
 SG_ MO_HV_Spannungsfreiheit : 12|2@1+ (1,0) [0|3] ""  Gateway
 SG_ MO_Reku_Leistung : 14|10@1+ (10,0) [0|10230] "Unit_Watt"  Gateway
 SG_ Mo_Powermeter_Grenze : 24|12@1+ (1,0) [0|4092] ""  Gateway
 SG_ MO_Gesamtst_Spgfreiheit : 36|2@1+ (1,0) [0|3] ""  Gateway
 SG_ MO_Tankbereitschaft_Status : 38|3@1+ (1,0) [0|7] ""  Gateway
 SG_ MO_Energieinhalt_BMS : 48|12@1+ (25,0) [0|102325] "Unit_WattHour"  Gateway
 SG_ MO_HYB_Status_Betriebsstrategie : 60|3@1+ (1,0) [0|7] ""  Gateway
 SG_ MO_Boost_aktiv : 63|1@1+ (1,0) [0|1] ""  Gateway

BO_ 969 MotorSlave_01: 1 Motor_Slave_D4
 SG_ MOS_KD_Fehler : 0|1@1+ (1.0,0.0) [0.0|1] ""  Gateway_D4C7

BO_ 1696 NightVision_01: 8 Gateway_D4C7
 SG_ NV_aktiv : 12|1@1+ (1.0,0.0) [0.0|1] ""  Airbag_D4
 SG_ NV_Texte : 13|3@1+ (1.0,0.0) [0.0|7] ""  Vector__XXX
 SG_ NV_Gong : 16|2@1+ (1.0,0.0) [0.0|3] ""  Airbag_D4
 SG_ NV_Symbol : 18|1@1+ (1.0,0.0) [0.0|1] ""  Airbag_D4
 SG_ NV_Hinweise : 19|2@1+ (1.0,0.0) [0.0|3] ""  Vector__XXX
 SG_ NV_Piktogramm_aktiv : 21|1@1+ (1.0,0.0) [0.0|1] ""  Vector__XXX
 SG_ NV_Akustik_deaktiviert_Icon : 22|1@1+ (1.0,0.0) [0.0|1] ""  Vector__XXX
 SG_ NV_FGM_deaktiviert_Icon : 23|1@1+ (1.0,0.0) [0.0|1] ""  Vector__XXX
 SG_ NV_KD_Fehler : 63|1@1+ (1.0,0.0) [0.0|1] ""  Vector__XXX

BO_ 1742 NMH_BMS: 7 BMS_Hybrid
 SG_ NMH_BMS_Start_1 : 0|1@1+ (1,0) [0|1] ""  BMS_Hybrid,EPB_MLB,Gateway,Getriebe_AL551_951_D4_C7,Getriebe_AL551_Hybrid_D4_C7,Getriebe_DL382_MLB,Getriebe_DL501_MLB,Getriebe_VL381_MLB,LEH_Hybrid,Motor2_MLB_D4_C7,Motor_MLB_AU64_AU57_Diesel,Motor_MLB_BY_Otto,Motor_MLB_C7_PHEV,Motor_MLB_D4_C7_Hybrid,Motor_MLB_D4_C7_Otto,SCR_MLB
 SG_ NMH_BMS_Start_2 : 1|1@1+ (1,0) [0|1] "" Vector__XXX
 SG_ NMH_BMS_Normal_Mode_1 : 2|1@1+ (1,0) [0|1] "" Vector__XXX
 SG_ NMH_BMS_Normal_Mode_2 : 3|1@1+ (1,0) [0|1] "" Vector__XXX
 SG_ NMH_BMS_Car_WakeUp : 6|1@1+ (1,0) [0|1] "" Vector__XXX
 SG_ NMH_BMS_Per_WakeUp : 8|5@1+ (1,0) [0|31] "" Vector__XXX
 SG_ NMH_BMS_Fkt_WakeUp : 13|3@1+ (1,0) [0|7] "" Vector__XXX
 SG_ NMH_BMS_Klemme_15 : 16|1@1+ (1,0) [0|1] "" Vector__XXX
 SG_ NMH_BMS_Diagnose : 17|1@1+ (1,0) [0|1] "" Vector__XXX
 SG_ NMH_BMS_MindestAktivZeit : 18|1@1+ (1,0) [0|1] "" Vector__XXX
 SG_ NMH_BMS_NL_Daten_EEPROM : 24|1@1+ (1,0) [0|1] "" Vector__XXX
 SG_ NMH_BMS_NL_Luefter : 25|1@1+ (1,0) [0|1] "" Vector__XXX
 SG_ NMH_BMS_Signalfehler : 32|1@1+ (1,0) [0|1] "" Vector__XXX
 SG_ NMH_BMS_TimeOut_Fehler : 33|1@1+ (1,0) [0|1] "" Vector__XXX
 SG_ NMH_BMS_CAN_Diag_deaktiv : 34|1@1+ (1,0) [0|1] "" Vector__XXX
 SG_ NMH_BMS_KompSchutz : 35|1@1+ (1,0) [0|1] "" Vector__XXX
 SG_ NMH_BMS_Mute_Mode : 36|1@1+ (1,0) [0|1] "" Vector__XXX
 SG_ NMH_BMS_Transport_Mode : 37|1@1+ (1,0) [0|1] "" Vector__XXX
 SG_ NMH_BMS_Abschaltstufe_aktiv : 38|1@1+ (1,0) [0|1] "" Vector__XXX
 SG_ NMH_BMS_Busfehler : 39|1@1+ (1,0) [0|1] "" Vector__XXX
 SG_ NMH_BMS_Lokalaktiv : 48|1@1+ (1,0) [0|1] "" Vector__XXX
 SG_ NMH_BMS_Subsystemaktiv : 49|1@1+ (1,0) [0|1] "" Vector__XXX

BO_ 1743 NMH_EM: 7 LEH_Hybrid
 SG_ NMH_EM_Start_1 : 0|1@1+ (1,0) [0|1] ""  BMS_Hybrid,EPB_MLB,Gateway,Getriebe_AL551_951_D4_C7,Getriebe_AL551_Hybrid_D4_C7,Getriebe_DL382_MLB,Getriebe_DL501_MLB,Getriebe_VL381_MLB,LEH_Hybrid,Motor2_MLB_D4_C7,Motor_MLB_AU64_AU57_Diesel,Motor_MLB_BY_Otto,Motor_MLB_C7_PHEV,Motor_MLB_D4_C7_Hybrid,Motor_MLB_D4_C7_Otto,SCR_MLB
 SG_ NMH_EM_Start_2 : 1|1@1+ (1,0) [0|1] "" Vector__XXX
 SG_ NMH_EM_Normal_Mode_1 : 2|1@1+ (1,0) [0|1] "" Vector__XXX
 SG_ NMH_EM_Normal_Mode_2 : 3|1@1+ (1,0) [0|1] "" Vector__XXX
 SG_ NMH_EM_Car_WakeUp : 6|1@1+ (1,0) [0|1] "" Vector__XXX
 SG_ NMH_EM_Per_WakeUp : 8|5@1+ (1,0) [0|31] "" Vector__XXX
 SG_ NMH_EM_Fkt_WakeUp : 13|3@1+ (1,0) [0|7] "" Vector__XXX
 SG_ NMH_EM_Klemme_15 : 16|1@1+ (1,0) [0|1] "" Vector__XXX
 SG_ NMH_EM_Diagnose : 17|1@1+ (1,0) [0|1] "" Vector__XXX
 SG_ NMH_EM_MindestAktivZeit : 18|1@1+ (1,0) [0|1] "" Vector__XXX
 SG_ NMH_EM_keine_HV_Entl : 19|1@1+ (1,0) [0|1] "" Vector__XXX
 SG_ NMH_EM_NL_Datem_EEPROM : 24|1@1+ (1,0) [0|1] "" Vector__XXX
 SG_ NMH_EM_Signalfehler : 32|1@1+ (1,0) [0|1] "" Vector__XXX
 SG_ NMH_EM_TimeOut_Fehler : 33|1@1+ (1,0) [0|1] "" Vector__XXX
 SG_ NMH_EM_CAN_Diag_deaktiv : 34|1@1+ (1,0) [0|1] "" Vector__XXX
 SG_ NMH_EM_KompSchutz : 35|1@1+ (1,0) [0|1] "" Vector__XXX
 SG_ NMH_EM_Mute_Mode : 36|1@1+ (1,0) [0|1] "" Vector__XXX
 SG_ NMH_EM_Transport_Mode : 37|1@1+ (1,0) [0|1] "" Vector__XXX
 SG_ NMH_EM_Abschaltstufe_aktiv : 38|1@1+ (1,0) [0|1] "" Vector__XXX
 SG_ NMH_EM_Busfehler : 39|1@1+ (1,0) [0|1] "" Vector__XXX
 SG_ NMH_EM_Lokalaktiv : 48|1@1+ (1,0) [0|1] "" Vector__XXX
 SG_ NMH_EM_Subsystemaktiv : 49|1@1+ (1,0) [0|1] "" Vector__XXX

BO_ 1753 NMH_EPB: 7 EPB_D4
 SG_ NMH_EPB_Start_1 : 0|1@1+ (1.0,0.0) [0.0|1] ""  EPB_D4,Gateway_D4C7,Getriebe_AL551_951_D4_C7,Getriebe_DL501_C7,Getriebe_VL381_C7,Motor_EDC17_D4,Motor_ME17_BY,Motor_MED17_SIMOS8_D4,Motor_Slave_D4,SCR_C7
 SG_ NMH_EPB_Start_2 : 1|1@1+ (1.0,0.0) [0.0|1] ""  Vector__XXX
 SG_ NMH_EPB_Normal_Mode_1 : 2|1@1+ (1.0,0.0) [0.0|1] ""  Vector__XXX
 SG_ NMH_EPB_Normal_Mode_2 : 3|1@1+ (1.0,0.0) [0.0|1] ""  Vector__XXX
 SG_ NMH_EPB_Car_WakeUp : 6|1@1+ (1.0,0.0) [0.0|1] ""  Vector__XXX
 SG_ NMH_EPB_Per_WakeUp : 8|5@1+ (1.0,0.0) [0.0|31] ""  Vector__XXX
 SG_ NMH_EPB_Fkt_WakeUp : 13|3@1+ (1.0,0.0) [0.0|7] ""  Vector__XXX
 SG_ NMH_EPB_NM_aktiv_Klemme_15 : 16|1@1+ (1.0,0.0) [0.0|1] ""  Vector__XXX
 SG_ NMH_EPB_NM_aktiv_Diagnose : 17|1@1+ (1.0,0.0) [0.0|1] ""  Vector__XXX
 SG_ NMH_EPB_NM_aktiv_Start : 18|1@1+ (1.0,0.0) [0.0|1] ""  Vector__XXX
 SG_ NMH_EPB_NM_aktiv_Schalter : 19|1@1+ (1.0,0.0) [0.0|1] ""  Vector__XXX
 SG_ NMH_EPB_NM_aktiv_Bedarf_Anzeige : 20|1@1+ (1.0,0.0) [0.0|1] ""  Vector__XXX
 SG_ NMH_EPB_NM_aktiv_v_groesser_Null : 21|1@1+ (1.0,0.0) [0.0|1] ""  Vector__XXX
 SG_ NMH_EPB_kein_NL : 24|1@1+ (1.0,0.0) [0.0|1] ""  Vector__XXX
 SG_ NMH_EPB_NL_Temp_Modell : 25|1@1+ (1.0,0.0) [0.0|1] ""  Vector__XXX
 SG_ NMH_EPB_NL_Min : 26|1@1+ (1.0,0.0) [0.0|1] ""  Vector__XXX
 SG_ NMH_EPB_NL_AutoAdjust : 27|1@1+ (1.0,0.0) [0.0|1] ""  Vector__XXX
 SG_ NM_EPB_Signalfehler : 32|1@1+ (1.0,0.0) [0.0|1] ""  Vector__XXX
 SG_ NMH_EPB_TimeOut_Fehler : 33|1@1+ (1.0,0.0) [0.0|1] ""  Vector__XXX
 SG_ NMH_EPB_CAN_Diag_deaktiv : 34|1@1+ (1.0,0.0) [0.0|1] ""  Vector__XXX
 SG_ NMH_EPB_KompSchutz : 35|1@1+ (1.0,0.0) [0.0|1] ""  Vector__XXX
 SG_ NMH_EPB_Mute_Mode : 36|1@1+ (1.0,0.0) [0.0|1] ""  Vector__XXX
 SG_ NMH_EPB_Transport_Mode : 37|1@1+ (1.0,0.0) [0.0|1] ""  Vector__XXX
 SG_ NMH_EPB_Abschaltstufe_aktiv : 38|1@1+ (1.0,0.0) [0.0|1] ""  Vector__XXX
 SG_ NMH_EPB_Eindraht_Fehler : 39|1@1+ (1.0,0.0) [0.0|1] ""  Vector__XXX
 SG_ NMH_EPB_Lokalaktiv : 48|1@1+ (1.0,0.0) [0.0|1] ""  Vector__XXX
 SG_ NMH_EPB_Subsystemaktiv : 49|1@1+ (1.0,0.0) [0.0|1] ""  Vector__XXX

BO_ 1728 NMH_Gateway: 7 Gateway_D4C7
 SG_ NMH_GW_Start_1 : 0|1@1+ (1.0,0.0) [0.0|1] ""  EPB_D4,Gateway_D4C7,Getriebe_AL551_951_D4_C7,Getriebe_DL501_C7,Getriebe_VL381_C7,Motor_EDC17_D4,Motor_ME17_BY,Motor_MED17_SIMOS8_D4,Motor_Slave_D4,SCR_C7
 SG_ NMH_GW_Start_2 : 1|1@1+ (1.0,0.0) [0.0|1] ""  EPB_D4,Gateway_D4C7,Getriebe_AL551_951_D4_C7,Getriebe_DL501_C7,Getriebe_VL381_C7,Motor_EDC17_D4,Motor_ME17_BY,Motor_MED17_SIMOS8_D4,Motor_Slave_D4,SCR_C7
 SG_ NMH_GW_Normal_Mode_1 : 2|1@1+ (1.0,0.0) [0.0|1] ""  EPB_D4,Gateway_D4C7,Getriebe_AL551_951_D4_C7,Getriebe_DL501_C7,Getriebe_VL381_C7,Motor_EDC17_D4,Motor_ME17_BY,Motor_MED17_SIMOS8_D4,Motor_Slave_D4,SCR_C7
 SG_ NMH_GW_Normal_Mode_2 : 3|1@1+ (1.0,0.0) [0.0|1] ""  EPB_D4,Gateway_D4C7,Getriebe_AL551_951_D4_C7,Getriebe_DL501_C7,Getriebe_VL381_C7,Motor_EDC17_D4,Motor_ME17_BY,Motor_MED17_SIMOS8_D4,Motor_Slave_D4,SCR_C7
 SG_ NMH_GW_Car_WakeUp : 6|1@1+ (1.0,0.0) [0.0|1] ""  Vector__XXX
 SG_ NMH_GW_Per_WakeUp : 8|5@1+ (1.0,0.0) [0.0|31] ""  Vector__XXX
 SG_ NMH_GW_Fkt_WakeUp : 13|3@1+ (1.0,0.0) [0.0|7] ""  Vector__XXX
 SG_ NMH_GW_NM_aktiv_Klemme_15 : 16|1@1+ (1.0,0.0) [0.0|1] ""  Vector__XXX
 SG_ NMH_GW_NM_aktiv_Diagnose : 17|1@1+ (1.0,0.0) [0.0|1] ""  Vector__XXX
 SG_ NMH_GW_NM_aktiv_Start : 18|1@1+ (1.0,0.0) [0.0|1] ""  Vector__XXX
 SG_ NMH_GW_NM_aktiv_BDM : 19|1@1+ (1.0,0.0) [0.0|1] ""  Vector__XXX
 SG_ NMH_GW_NM_aktiv_Warnblinken : 20|1@1+ (1.0,0.0) [0.0|1] ""  Vector__XXX
 SG_ NMH_GW_NM_aktiv_ESP : 21|1@1+ (1.0,0.0) [0.0|1] ""  Vector__XXX
 SG_ NMH_GW_Abschaltstufe_3 : 24|1@1+ (1.0,0.0) [0.0|1] ""  Vector__XXX
 SG_ NMH_GW_SG_Fehlerdauer : 25|1@1+ (1.0,0.0) [0.0|1] ""  Vector__XXX
 SG_ NMH_GW_STH_Wakeup : 26|1@1+ (1.0,0.0) [0.0|1] ""  Vector__XXX
 SG_ NMH_GW_NL_Diagnose : 27|1@1+ (1.0,0.0) [0.0|1] ""  Vector__XXX
 SG_ NM_GW_Signalfehler : 32|1@1+ (1.0,0.0) [0.0|1] ""  Vector__XXX
 SG_ NMH_GW_TimeOut_Fehler : 33|1@1+ (1.0,0.0) [0.0|1] ""  Vector__XXX
 SG_ NMH_GW_CAN_Diag_deaktiv : 34|1@1+ (1.0,0.0) [0.0|1] ""  Vector__XXX
 SG_ NMH_GW_KompSchutz : 35|1@1+ (1.0,0.0) [0.0|1] ""  Vector__XXX
 SG_ NMH_GW_Mute_Mode : 36|1@1+ (1.0,0.0) [0.0|1] ""  Vector__XXX
 SG_ NMH_GW_Transport_Mode : 37|1@1+ (1.0,0.0) [0.0|1] ""  Vector__XXX
 SG_ NMH_GW_Abschaltstufe_aktiv : 38|1@1+ (1.0,0.0) [0.0|1] ""  Vector__XXX
 SG_ NMH_GW_Eindraht_Fehler : 39|1@1+ (1.0,0.0) [0.0|1] ""  Vector__XXX
 SG_ NMH_GW_ACAN : 40|1@1+ (1.0,0.0) [0.0|1] ""  Vector__XXX
 SG_ NMH_GW_KombiCAN : 41|1@1+ (1.0,0.0) [0.0|1] ""  Vector__XXX
 SG_ NMH_GW_KomfortCAN : 42|1@1+ (1.0,0.0) [0.0|1] ""  Vector__XXX
 SG_ NMH_GW_Infotainment : 43|1@1+ (1.0,0.0) [0.0|1] ""  Vector__XXX
 SG_ NMH_GW_Fahrwerk : 44|1@1+ (1.0,0.0) [0.0|1] ""  Vector__XXX
 SG_ NMH_GW_WakeUp_CAN_Bus : 45|3@1+ (1.0,0.0) [0.0|7] ""  Vector__XXX

BO_ 1730 NMH_Getriebe: 7 Getriebe_AL551_951_D4_C7
 SG_ NMH_GE_Start_1 : 0|1@1+ (1.0,0.0) [0.0|1] ""  EPB_D4,Gateway_D4C7,Getriebe_AL551_951_D4_C7,Getriebe_DL501_C7,Getriebe_VL381_C7,Motor_EDC17_D4,Motor_ME17_BY,Motor_MED17_SIMOS8_D4,Motor_Slave_D4,SCR_C7
 SG_ NMH_GE_Start_2 : 1|1@1+ (1.0,0.0) [0.0|1] ""  Vector__XXX
 SG_ NMH_GE_Normal_Mode_1 : 2|1@1+ (1.0,0.0) [0.0|1] ""  Vector__XXX
 SG_ NMH_GE_Normal_Mode_2 : 3|1@1+ (1.0,0.0) [0.0|1] ""  Vector__XXX
 SG_ NMH_GE_Car_WakeUp : 6|1@1+ (1.0,0.0) [0.0|1] ""  Vector__XXX
 SG_ NMH_GE_Per_WakeUp : 8|5@1+ (1.0,0.0) [0.0|31] ""  Vector__XXX
 SG_ NMH_GE_Fkt_WakeUp : 13|3@1+ (1.0,0.0) [0.0|7] ""  Vector__XXX
 SG_ NMH_GE_NM_aktiv_Klemme_15 : 16|1@1+ (1.0,0.0) [0.0|1] ""  Vector__XXX
 SG_ NMH_GE_NM_aktiv_Diagnose : 17|1@1+ (1.0,0.0) [0.0|1] ""  Vector__XXX
 SG_ NMH_GE_NM_aktiv_Start : 18|1@1+ (1.0,0.0) [0.0|1] ""  Vector__XXX
 SG_ NMH_GE_N_Haltephase : 19|1@1+ (1.0,0.0) [0.0|1] ""  Vector__XXX
 SG_ NMH_GE_kein_NL : 24|1@1+ (1.0,0.0) [0.0|1] ""  Vector__XXX
 SG_ NMH_GE_NL_Daten_EEPROM : 25|1@1+ (1.0,0.0) [0.0|1] ""  Vector__XXX
 SG_ NMH_GE_NL_Drucksens : 26|1@1+ (1.0,0.0) [0.0|1] ""  Vector__XXX
 SG_ NMH_GE_NL_Abtrieb : 27|1@1+ (1.0,0.0) [0.0|1] ""  Vector__XXX
 SG_ NMH_GE_NL_Waehlhebel : 28|1@1+ (1.0,0.0) [0.0|1] ""  Vector__XXX
 SG_ NMH_GE_NL_Wegfahrsperre : 29|1@1+ (1.0,0.0) [0.0|1] ""  Vector__XXX
 SG_ NM_GE_Signalfehler : 32|1@1+ (1.0,0.0) [0.0|1] ""  Vector__XXX
 SG_ NMH_GE_TimeOut_Fehler : 33|1@1+ (1.0,0.0) [0.0|1] ""  Vector__XXX
 SG_ NMH_GE_CAN_Diag_deaktiv : 34|1@1+ (1.0,0.0) [0.0|1] ""  Vector__XXX
 SG_ NMH_GE_KompSchutz : 35|1@1+ (1.0,0.0) [0.0|1] ""  Vector__XXX
 SG_ NMH_GE_Mute_Mode : 36|1@1+ (1.0,0.0) [0.0|1] ""  Vector__XXX
 SG_ NMH_GE_Transport_Mode : 37|1@1+ (1.0,0.0) [0.0|1] ""  Vector__XXX
 SG_ NMH_GE_Abschaltstufe_aktiv : 38|1@1+ (1.0,0.0) [0.0|1] ""  Vector__XXX
 SG_ NMH_GE_Eindraht_Fehler : 39|1@1+ (1.0,0.0) [0.0|1] ""  Vector__XXX
 SG_ NMH_GE_Lokalaktiv : 48|1@1+ (1.0,0.0) [0.0|1] ""  Vector__XXX
 SG_ NMH_GE_Subsystemaktiv : 49|1@1+ (1.0,0.0) [0.0|1] ""  Vector__XXX
 SG_ NMH_GSG_Subbusaktiv : 50|1@1+ (1.0,0.0) [0.0|1] ""  Vector__XXX

BO_ 1729 NMH_Motor: 7 Motor_EDC17_D4
 SG_ NMH_MO_Start_1 : 0|1@1+ (1.0,0.0) [0.0|1] ""  EPB_D4,Gateway_D4C7,Getriebe_AL551_951_D4_C7,Getriebe_DL501_C7,Getriebe_VL381_C7,Motor_EDC17_D4,Motor_ME17_BY,Motor_MED17_SIMOS8_D4,Motor_Slave_D4,SCR_C7
 SG_ NMH_MO_Start_2 : 1|1@1+ (1.0,0.0) [0.0|1] ""  Vector__XXX
 SG_ NMH_MO_Normal_Mode_1 : 2|1@1+ (1.0,0.0) [0.0|1] ""  Vector__XXX
 SG_ NMH_MO_Normal_Mode_2 : 3|1@1+ (1.0,0.0) [0.0|1] ""  Vector__XXX
 SG_ NMH_MO_Car_WakeUp : 6|1@1+ (1.0,0.0) [0.0|1] ""  Vector__XXX
 SG_ NMH_MO_Per_WakeUp : 8|5@1+ (1.0,0.0) [0.0|31] ""  Vector__XXX
 SG_ NMH_MO_Fkt_WakeUp : 13|3@1+ (1.0,0.0) [0.0|7] ""  Vector__XXX
 SG_ NMH_MO_NM_aktiv_Klemme_15 : 16|1@1+ (1.0,0.0) [0.0|1] ""  Vector__XXX
 SG_ NMH_MO_NM_aktiv_Diagnose : 17|1@1+ (1.0,0.0) [0.0|1] ""  Vector__XXX
 SG_ NMH_MO_NM_aktiv_Start : 18|1@1+ (1.0,0.0) [0.0|1] ""  Vector__XXX
 SG_ NMH_MO_NM_aktiv_EKP_Vorlauf : 19|1@1+ (1.0,0.0) [0.0|1] ""  Vector__XXX
 SG_ NMH_MO_NM_aktiv_STH_Betrieb : 20|1@1+ (1.0,0.0) [0.0|1] ""  Vector__XXX
 SG_ NMH_MO_NM_aktiv_HV_Abschaltung : 21|1@1+ (1.0,0.0) [0.0|1] ""  Vector__XXX
 SG_ NMH_MO_kein_NL : 24|1@1+ (1.0,0.0) [0.0|1] ""  Vector__XXX
 SG_ NMH_MO_NL_Kuehlerluefter : 25|1@1+ (1.0,0.0) [0.0|1] ""  Vector__XXX
 SG_ NMH_MO_NL_Diagnose : 26|1@1+ (1.0,0.0) [0.0|1] ""  Vector__XXX
 SG_ NMH_MO_NL_WFS : 27|1@1+ (1.0,0.0) [0.0|1] ""  Vector__XXX
 SG_ NMH_MO_NL_EEPROM : 28|1@1+ (1.0,0.0) [0.0|1] ""  Vector__XXX
 SG_ NMH_MO_NL_Sonstige : 29|1@1+ (1.0,0.0) [0.0|1] ""  Vector__XXX
 SG_ NM_MO_Signalfehler : 32|1@1+ (1.0,0.0) [0.0|1] ""  Vector__XXX
 SG_ NMH_MO_TimeOut_Fehler : 33|1@1+ (1.0,0.0) [0.0|1] ""  Vector__XXX
 SG_ NMH_MO_CAN_Diag_deaktiv : 34|1@1+ (1.0,0.0) [0.0|1] ""  Vector__XXX
 SG_ NMH_MO_KompSchutz : 35|1@1+ (1.0,0.0) [0.0|1] ""  Vector__XXX
 SG_ NMH_MO_Mute_Mode : 36|1@1+ (1.0,0.0) [0.0|1] ""  Vector__XXX
 SG_ NMH_MO_Transport_Mode : 37|1@1+ (1.0,0.0) [0.0|1] ""  Vector__XXX
 SG_ NMH_MO_Abschaltstufe_aktiv : 38|1@1+ (1.0,0.0) [0.0|1] ""  Vector__XXX
 SG_ NMH_MO_Eindraht_Fehler : 39|1@1+ (1.0,0.0) [0.0|1] ""  Vector__XXX
 SG_ NMH_MO_Lokalaktiv : 48|1@1+ (1.0,0.0) [0.0|1] ""  Vector__XXX
 SG_ NMH_MO_Subsystemaktiv : 49|1@1+ (1.0,0.0) [0.0|1] ""  Vector__XXX

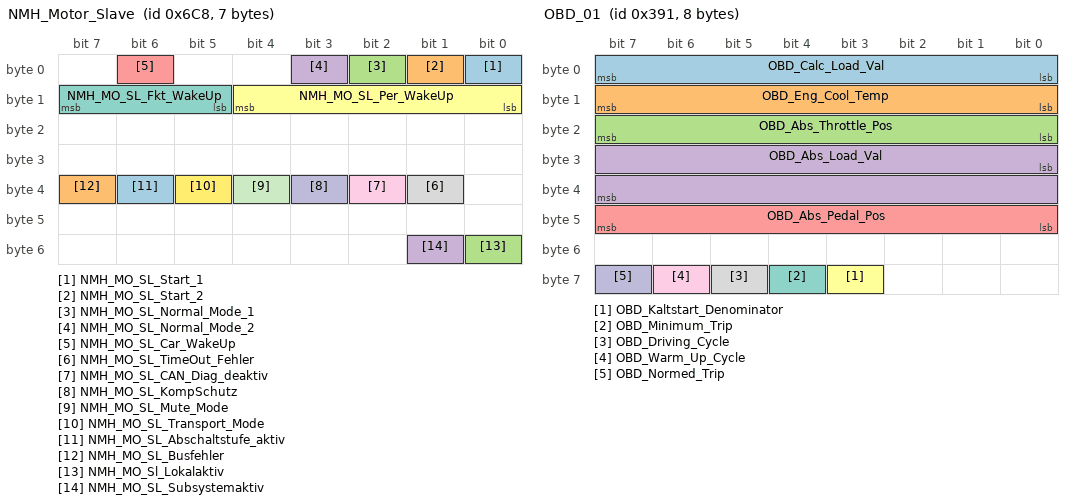
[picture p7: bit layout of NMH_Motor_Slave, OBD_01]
BO_ 1736 NMH_Motor_Slave: 7 Motor_Slave_D4
 SG_ NMH_MO_SL_Start_1 : 0|1@1+ (1.0,0.0) [0.0|1] ""  EPB_D4,Gateway_D4C7,Getriebe_AL551_951_D4_C7,Getriebe_DL501_C7,Getriebe_VL381_C7,Motor_EDC17_D4,Motor_ME17_BY,Motor_MED17_SIMOS8_D4,Motor_Slave_D4,SCR_C7
 SG_ NMH_MO_SL_Start_2 : 1|1@1+ (1.0,0.0) [0.0|1] ""  Vector__XXX
 SG_ NMH_MO_SL_Normal_Mode_1 : 2|1@1+ (1.0,0.0) [0.0|1] ""  Vector__XXX
 SG_ NMH_MO_SL_Normal_Mode_2 : 3|1@1+ (1.0,0.0) [0.0|1] ""  Vector__XXX
 SG_ NMH_MO_SL_Car_WakeUp : 6|1@1+ (1.0,0.0) [0.0|1] ""  Vector__XXX
 SG_ NMH_MO_SL_Per_WakeUp : 8|5@1+ (1.0,0.0) [0.0|31] ""  Vector__XXX
 SG_ NMH_MO_SL_Fkt_WakeUp : 13|3@1+ (1.0,0.0) [0.0|7] ""  Vector__XXX
 SG_ NMH_MO_SL_TimeOut_Fehler : 33|1@1+ (1.0,0.0) [0.0|1] ""  Vector__XXX
 SG_ NMH_MO_SL_CAN_Diag_deaktiv : 34|1@1+ (1.0,0.0) [0.0|1] ""  Vector__XXX
 SG_ NMH_MO_SL_KompSchutz : 35|1@1+ (1.0,0.0) [0.0|1] ""  Vector__XXX
 SG_ NMH_MO_SL_Mute_Mode : 36|1@1+ (1.0,0.0) [0.0|1] ""  Vector__XXX
 SG_ NMH_MO_SL_Transport_Mode : 37|1@1+ (1.0,0.0) [0.0|1] ""  Vector__XXX
 SG_ NMH_MO_SL_Abschaltstufe_aktiv : 38|1@1+ (1.0,0.0) [0.0|1] ""  Vector__XXX
 SG_ NMH_MO_SL_Busfehler : 39|1@1+ (1.0,0.0) [0.0|1] ""  Vector__XXX
 SG_ NMH_MO_Sl_Lokalaktiv : 48|1@1+ (1.0,0.0) [0.0|1] ""  Vector__XXX
 SG_ NMH_MO_SL_Subsystemaktiv : 49|1@1+ (1.0,0.0) [0.0|1] ""  Vector__XXX

BO_ 1782 NMH_SCR: 7 SCR_C7
 SG_ NMH_SCR_Start_1 : 0|1@1+ (1.0,0.0) [0.0|1] ""  EPB_D4,Gateway_D4C7,Getriebe_AL551_951_D4_C7,Getriebe_DL501_C7,Getriebe_VL381_C7,Motor_EDC17_D4,Motor_ME17_BY,Motor_MED17_SIMOS8_D4,Motor_Slave_D4,SCR_C7
 SG_ NMH_SCR_Start_2 : 1|1@1+ (1.0,0.0) [0.0|1] ""  Vector__XXX
 SG_ NMH_SCR_Normal_Mode_1 : 2|1@1+ (1.0,0.0) [0.0|1] ""  Vector__XXX
 SG_ NMH_SCR_Normal_Mode_2 : 3|1@1+ (1.0,0.0) [0.0|1] ""  Vector__XXX
 SG_ NMH_SCR_Car_WakeUp : 6|1@1+ (1.0,0.0) [0.0|1] ""  Vector__XXX
 SG_ NMH_SCR_Per_WakeUp : 8|5@1+ (1.0,0.0) [0.0|31] ""  Vector__XXX
 SG_ NMH_SCR_Fkt_WakeUp : 13|3@1+ (1.0,0.0) [0.0|7] ""  Vector__XXX
 SG_ NMH_SCR_Klemme_15 : 16|1@1+ (1.0,0.0) [0.0|1] ""  Vector__XXX
 SG_ NMH_SCR_Diagnose : 17|1@1+ (1.0,0.0) [0.0|1] ""  Vector__XXX
 SG_ NMH_SCR_MindestAktivZeit : 18|1@1+ (1.0,0.0) [0.0|1] ""  Vector__XXX
 SG_ NMH_SCR_NL_Datem_EEPROM : 24|1@1+ (1.0,0.0) [0.0|1] ""  Vector__XXX
 SG_ NMH_SCR_Signalfehler : 32|1@1+ (1.0,0.0) [0.0|1] ""  Vector__XXX
 SG_ NMH_SCR_TimeOut_Fehler : 33|1@1+ (1.0,0.0) [0.0|1] ""  Vector__XXX
 SG_ NMH_SCR_CAN_Diag_deaktiv : 34|1@1+ (1.0,0.0) [0.0|1] ""  Vector__XXX
 SG_ NMH_SCR_KompSchutz : 35|1@1+ (1.0,0.0) [0.0|1] ""  Vector__XXX
 SG_ NMH_SCR_Mute_Mode : 36|1@1+ (1.0,0.0) [0.0|1] ""  Vector__XXX
 SG_ NMH_SCR_Transport_Mode : 37|1@1+ (1.0,0.0) [0.0|1] ""  Vector__XXX
 SG_ NMH_SCR_Abschaltstufe_aktiv : 38|1@1+ (1.0,0.0) [0.0|1] ""  Vector__XXX
 SG_ NMH_SCR_Busfehler : 39|1@1+ (1.0,0.0) [0.0|1] ""  Vector__XXX
 SG_ NMH_SCR_Lokalaktiv : 48|1@1+ (1.0,0.0) [0.0|1] ""  Vector__XXX
 SG_ NMH_SCR_Subsystemaktiv : 49|1@1+ (1.0,0.0) [0.0|1] ""  Vector__XXX

BO_ 913 OBD_01: 8 Motor_EDC17_D4
 SG_ OBD_Calc_Load_Val : 0|8@1+ (0.39215686274509803,0) [0E-17|99.99999999999999765] "Unit_PerCent"  Getriebe_AL551_951_D4_C7,Getriebe_DL501_C7,Getriebe_VL381_C7
 SG_ OBD_Eng_Cool_Temp : 8|8@1+ (1,-40) [-40|215] "Unit_DegreCelsi"  Getriebe_AL551_951_D4_C7,Getriebe_DL501_C7,Getriebe_VL381_C7
 SG_ OBD_Abs_Throttle_Pos : 16|8@1+ (0.39215686274509803,0) [0E-17|99.99999999999999765] "Unit_PerCent"  Getriebe_AL551_951_D4_C7,Getriebe_DL501_C7,Getriebe_VL381_C7
 SG_ OBD_Abs_Load_Val : 24|16@1+ (0.39215686274509803,0) [0E-17|25699.99999999999939605] "Unit_PerCent"  Getriebe_AL551_951_D4_C7,Getriebe_DL501_C7,Getriebe_VL381_C7
 SG_ OBD_Abs_Pedal_Pos : 40|8@1+ (0.39215686274509803,0) [0E-17|99.99999999999999765] "Unit_PerCent"  Getriebe_AL551_951_D4_C7,Getriebe_DL501_C7,Getriebe_VL381_C7
 SG_ OBD_Kaltstart_Denominator : 59|1@1+ (1.0,0.0) [0.0|1] ""  Vector__XXX
 SG_ OBD_Minimum_Trip : 60|1@1+ (1.0,0.0) [0.0|1] ""  Getriebe_AL551_951_D4_C7,Getriebe_DL501_C7,Getriebe_VL381_C7
 SG_ OBD_Driving_Cycle : 61|1@1+ (1.0,0.0) [0.0|1] ""  Getriebe_AL551_951_D4_C7,Getriebe_DL501_C7,Getriebe_VL381_C7,SCR_C7
 SG_ OBD_Warm_Up_Cycle : 62|1@1+ (1.0,0.0) [0.0|1] ""  Gateway_D4C7,Getriebe_AL551_951_D4_C7,Getriebe_DL501_C7,Getriebe_VL381_C7,SCR_C7
 SG_ OBD_Normed_Trip : 63|1@1+ (1.0,0.0) [0.0|1] ""  Getriebe_AL551_951_D4_C7,Getriebe_DL501_C7,Getriebe_VL381_C7,SCR_C7

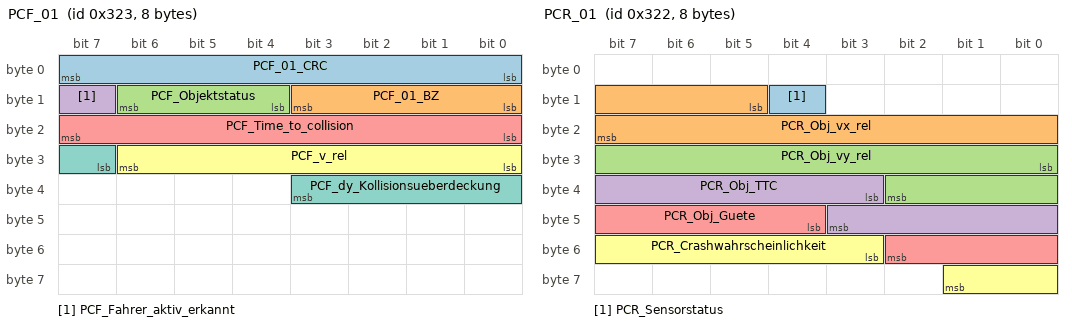
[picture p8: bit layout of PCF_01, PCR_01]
BO_ 803 PCF_01: 8 Gateway_D4C7
 SG_ PCF_01_CRC : 0|8@1+ (1,0) [0|255] ""  Airbag_D4
 SG_ PCF_01_BZ : 8|4@1+ (1,0) [0|15] ""  Airbag_D4
 SG_ PCF_Objektstatus : 12|3@1+ (1.0,0.0) [0.0|7] ""  Airbag_D4
 SG_ PCF_Fahrer_aktiv_erkannt : 15|1@1+ (1.0,0.0) [0.0|1] ""  Vector__XXX
 SG_ PCF_Time_to_collision : 16|8@1+ (0.01,0) [0.00|2.50] "Unit_Secon"  Airbag_D4
 SG_ PCF_v_rel : 24|7@1+ (0.5,0) [0.5|63.5] "Unit_MeterPerSecon"  Airbag_D4
 SG_ PCF_dy_Kollisionsueberdeckung : 31|5@1+ (0.1,0) [0.1|2.9] "Unit_Meter"  Vector__XXX

BO_ 802 PCR_01: 8 Gateway_D4C7
 SG_ PCR_Sensorstatus : 12|1@1+ (1.0,0.0) [0.0|1] ""  Airbag_D4
 SG_ PCR_Obj_vx_rel : 13|11@1+ (0.1,-102.3) [-102.3|102.3] "Unit_MeterPerSecon"  Airbag_D4
 SG_ PCR_Obj_vy_rel : 24|11@1+ (0.1,-102.3) [-102.3|102.3] "Unit_MeterPerSecon"  Airbag_D4
 SG_ PCR_Obj_TTC : 35|9@1+ (0.01,0) [0.00|5.10] "Unit_Secon"  Airbag_D4
 SG_ PCR_Obj_Guete : 44|7@1+ (1,0) [0|100] "Unit_PerCent"  Airbag_D4
 SG_ PCR_Crashwahrscheinlichkeit : 51|7@1+ (1,0) [0|100] "Unit_PerCent"  Airbag_D4

BO_ 929 PSD_01: 8 Gateway_D4C7
 SG_ PSD_Pos_Segment_ID : 0|6@1+ (1,0) [2|63] ""  Getriebe_AL551_951_D4_C7,Getriebe_DL501_C7,Getriebe_VL381_C7
 SG_ PSD_Pos_Segmentlaenge : 6|7@1+ (2,0) [0|254] "Unit_Meter"  Getriebe_AL551_951_D4_C7,Getriebe_DL501_C7,Getriebe_VL381_C7
 SG_ PSD_Pos_Inhibitzeit : 13|5@1+ (10,0) [0|310] "Unit_MilliSecon"  Getriebe_AL551_951_D4_C7,Getriebe_DL501_C7,Getriebe_VL381_C7
 SG_ PSD_Pos_Standort : 18|1@1+ (1.0,0.0) [0.0|1] ""  Getriebe_AL551_951_D4_C7,Getriebe_DL501_C7,Getriebe_VL381_C7
 SG_ PSD_Pos_Laengsfehler : 19|3@1+ (1.0,0.0) [0.0|7] ""  Getriebe_AL551_951_D4_C7,Getriebe_DL501_C7,Getriebe_VL381_C7
 SG_ PSD_Segment_ID : 22|6@1+ (1,0) [2|63] ""  Getriebe_AL551_951_D4_C7,Getriebe_DL501_C7,Getriebe_VL381_C7
 SG_ PSD_Vorgaenger_Segment_ID : 28|6@1+ (1,0) [2|63] ""  Getriebe_AL551_951_D4_C7,Getriebe_DL501_C7,Getriebe_VL381_C7
 SG_ PSD_Strassenklasse : 34|2@1+ (1.0,0.0) [0.0|3] ""  Getriebe_AL551_951_D4_C7,Getriebe_DL501_C7,Getriebe_VL381_C7
 SG_ PSD_Segmentlaenge : 36|7@1+ (2,0) [0|254] "Unit_Meter"  Getriebe_AL551_951_D4_C7,Getriebe_DL501_C7,Getriebe_VL381_C7
 SG_ PSD_Rampe : 43|2@1+ (1.0,0.0) [0.0|3] ""  Getriebe_AL551_951_D4_C7,Getriebe_DL501_C7,Getriebe_VL381_C7
 SG_ PSD_Endkruemmung : 45|8@1+ (1,0) [0|254] "Unit_None"  Getriebe_AL551_951_D4_C7,Getriebe_DL501_C7,Getriebe_VL381_C7
 SG_ PSD_Endkruemmung_Vorz : 53|1@1+ (1.0,0.0) [0.0|1] ""  Getriebe_AL551_951_D4_C7,Getriebe_DL501_C7,Getriebe_VL381_C7
 SG_ PSD_Endsteigung : 54|5@1+ (0.5,0) [0.0|14.5] "Unit_PerCent"  Getriebe_AL551_951_D4_C7,Getriebe_DL501_C7,Getriebe_VL381_C7
 SG_ PSD_Endsteigung_Vorz : 59|1@1+ (1.0,0.0) [0.0|1] ""  Getriebe_AL551_951_D4_C7,Getriebe_DL501_C7,Getriebe_VL381_C7
 SG_ PSD_ADAS_Qualitaet : 60|1@1+ (1.0,0.0) [0.0|1] ""  Getriebe_AL551_951_D4_C7,Getriebe_DL501_C7,Getriebe_VL381_C7
 SG_ PSD_Fahrspuren : 61|2@1+ (1.0,0.0) [0.0|3] ""  Getriebe_AL551_951_D4_C7,Getriebe_DL501_C7,Getriebe_VL381_C7
 SG_ PSD_wahrscheinlichster_Pfad : 63|1@1+ (1.0,0.0) [0.0|1] ""  Getriebe_AL551_951_D4_C7,Getriebe_DL501_C7,Getriebe_VL381_C7

BO_ 930 PSD_02: 8 Gateway_D4C7
 SG_ PSD_Multiplex M  : 0|2@1+ (1.0,0.0) [0.0|3] ""  Getriebe_AL551_951_D4_C7,Getriebe_DL501_C7,Getriebe_VL381_C7
 SG_ PSD_Sys_Segment_ID m0  : 2|6@1+ (1,0) [2|63] ""  Getriebe_AL551_951_D4_C7,Getriebe_DL501_C7,Getriebe_VL381_C7
 SG_ PSD_Abz_Segment_ID m1  : 2|6@1+ (1,0) [2|63] ""  Getriebe_AL551_951_D4_C7,Getriebe_DL501_C7,Getriebe_VL381_C7
 SG_ PSD_Ges_Segment_ID m2  : 2|6@1+ (1,0) [2|63] ""  Getriebe_AL551_951_D4_C7,Getriebe_DL501_C7,Getriebe_VL381_C7
 SG_ PSD_Ort_Laenge_VZ m3  : 2|1@1+ (1.0,0.0) [0.0|1] ""  Getriebe_AL551_951_D4_C7,Getriebe_DL501_C7,Getriebe_VL381_C7
 SG_ PSD_Ort_Laenge m3  : 3|25@1+ (0.00001,0) [0.00000|180.00000] "Unit_DegreOfArc"  Getriebe_AL551_951_D4_C7,Getriebe_DL501_C7,Getriebe_VL381_C7
 SG_ PSD_Sys_Laendercode m0  : 8|8@1+ (1.0,0.0) [0.0|255] ""  Getriebe_AL551_951_D4_C7,Getriebe_DL501_C7,Getriebe_VL381_C7
 SG_ PSD_Abz_Segmentlaenge m1  : 8|7@1+ (2,0) [0|254] "Unit_Meter"  Getriebe_AL551_951_D4_C7,Getriebe_DL501_C7,Getriebe_VL381_C7
 SG_ PSD_Ges_Geschwindigkeit m2  : 8|5@1+ (1.0,0.0) [0.0|31] ""  Getriebe_AL551_951_D4_C7,Getriebe_DL501_C7,Getriebe_VL381_C7
 SG_ PSD_Ges_Geschwindigkeit_Typ m2  : 13|1@1+ (1.0,0.0) [0.0|1] ""  Getriebe_AL551_951_D4_C7,Getriebe_DL501_C7,Getriebe_VL381_C7
 SG_ PSD_Ges_Geschwindigkeit_Gespann m2  : 14|2@1+ (1.0,0.0) [0.0|3] ""  Getriebe_AL551_951_D4_C7,Getriebe_DL501_C7,Getriebe_VL381_C7
 SG_ PSD_Abz_Vorgaenger_Segment_ID m1  : 15|6@1+ (1,0) [2|63] ""  Getriebe_AL551_951_D4_C7,Getriebe_DL501_C7,Getriebe_VL381_C7
 SG_ PSD_Sys_Geschwindigkeit_Einheit m0  : 16|1@1+ (1.0,0.0) [0.0|1] ""  Getriebe_AL551_951_D4_C7,Getriebe_DL501_C7,Getriebe_VL381_C7
 SG_ PSD_Ges_Geschwindigkeit_Witter m2  : 16|2@1+ (1.0,0.0) [0.0|3] ""  Getriebe_AL551_951_D4_C7,Getriebe_DL501_C7,Getriebe_VL381_C7
 SG_ PSD_Sys_Verkehrsrichtung m0  : 17|1@1+ (1.0,0.0) [0.0|1] ""  Getriebe_AL551_951_D4_C7,Getriebe_DL501_C7,Getriebe_VL381_C7
 SG_ PSD_Sys_Release_Monat m0  : 18|4@1+ (1,0) [1|12] "Unit_Month"  Getriebe_AL551_951_D4_C7,Getriebe_DL501_C7,Getriebe_VL381_C7
 SG_ PSD_Ges_Geschwindigkeit_Tag_Anf m2  : 18|3@1+ (1.0,0.0) [0.0|7] ""  Getriebe_AL551_951_D4_C7,Getriebe_DL501_C7,Getriebe_VL381_C7
 SG_ PSD_Abz_Geschwindigkeit m1  : 21|5@1+ (1.0,0.0) [0.0|31] ""  Getriebe_AL551_951_D4_C7,Getriebe_DL501_C7,Getriebe_VL381_C7
 SG_ PSD_Ges_Geschwindigkeit_Tag_Ende m2  : 21|3@1+ (1.0,0.0) [0.0|7] ""  Getriebe_AL551_951_D4_C7,Getriebe_DL501_C7,Getriebe_VL381_C7
 SG_ PSD_Sys_Release_Jahr m0  : 22|5@1+ (1,2000) [2000|2031] "Unit_Year"  Getriebe_AL551_951_D4_C7,Getriebe_DL501_C7,Getriebe_VL381_C7
 SG_ PSD_Ges_Geschwindigkeit_Std_Anf m2  : 24|5@1+ (1,0) [0|24] "Unit_Hours"  Getriebe_AL551_951_D4_C7,Getriebe_DL501_C7,Getriebe_VL381_C7
 SG_ PSD_Abz_Geschwindigkeit_Typ m1  : 26|1@1+ (1.0,0.0) [0.0|1] ""  Getriebe_AL551_951_D4_C7,Getriebe_DL501_C7,Getriebe_VL381_C7
 SG_ PSD_Sys_Tunnel m0  : 27|1@1+ (1.0,0.0) [0.0|1] ""  Getriebe_AL551_951_D4_C7,Getriebe_DL501_C7,Getriebe_VL381_C7
 SG_ PSD_Abz_Strassenklasse m1  : 27|2@1+ (1.0,0.0) [0.0|3] ""  Getriebe_AL551_951_D4_C7,Getriebe_DL501_C7,Getriebe_VL381_C7
 SG_ PSD_Sys_Bruecke m0  : 28|1@1+ (1.0,0.0) [0.0|1] ""  Getriebe_AL551_951_D4_C7,Getriebe_DL501_C7,Getriebe_VL381_C7
 SG_ PSD_Ort_Breite_VZ m3  : 28|1@1+ (1.0,0.0) [0.0|1] ""  Getriebe_AL551_951_D4_C7,Getriebe_DL501_C7,Getriebe_VL381_C7
 SG_ PSD_Sys_Fahrsp_Gegenr m0  : 29|2@1+ (1.0,0.0) [0.0|3] ""  Getriebe_AL551_951_D4_C7,Getriebe_DL501_C7,Getriebe_VL381_C7
 SG_ PSD_Abz_ADAS_Qualitaet m1  : 29|1@1+ (1.0,0.0) [0.0|1] ""  Getriebe_AL551_951_D4_C7,Getriebe_DL501_C7,Getriebe_VL381_C7
 SG_ PSD_Ges_Geschwindigkeit_Std_Ende m2  : 29|5@1+ (1,0) [0|24] "Unit_Hours"  Getriebe_AL551_951_D4_C7,Getriebe_DL501_C7,Getriebe_VL381_C7
 SG_ PSD_Ort_Breite m3  : 29|24@1+ (0.00001,0) [0.00000|90.00000] "Unit_DegreOfArc"  Getriebe_AL551_951_D4_C7,Getriebe_DL501_C7,Getriebe_VL381_C7
 SG_ PSD_Abz_Abzweigerichtung m1  : 30|1@1+ (1.0,0.0) [0.0|1] ""  Getriebe_AL551_951_D4_C7,Getriebe_DL501_C7,Getriebe_VL381_C7
 SG_ PSD_Sys_TMC_Baustelle m0  : 31|1@1+ (1.0,0.0) [0.0|1] ""  Getriebe_AL551_951_D4_C7,Getriebe_DL501_C7,Getriebe_VL381_C7
 SG_ PSD_Abz_Abzweigewinkel m1  : 31|4@1+ (1.0,0.0) [0.0|15] ""  Getriebe_AL551_951_D4_C7,Getriebe_DL501_C7,Getriebe_VL381_C7
 SG_ PSD_Sys_TMC_Stau m0  : 32|1@1+ (1.0,0.0) [0.0|1] ""  Getriebe_AL551_951_D4_C7,Getriebe_DL501_C7,Getriebe_VL381_C7
 SG_ PSD_Ges_alter_Geschw m2  : 34|5@1+ (1.0,0.0) [0.0|31] ""  Getriebe_AL551_951_D4_C7,Getriebe_DL501_C7,Getriebe_VL381_C7
 SG_ PSD_Abz_Rampe m1  : 35|2@1+ (1.0,0.0) [0.0|3] ""  Getriebe_AL551_951_D4_C7,Getriebe_DL501_C7,Getriebe_VL381_C7
 SG_ PSD_Abz_Anfangskruemmung m1  : 37|8@1+ (1,0) [0|254] "Unit_None"  Getriebe_AL551_951_D4_C7,Getriebe_DL501_C7,Getriebe_VL381_C7
 SG_ PSD_Ges_alter_Geschw_Gespann m2  : 39|2@1+ (1.0,0.0) [0.0|3] ""  Getriebe_AL551_951_D4_C7,Getriebe_DL501_C7,Getriebe_VL381_C7
 SG_ PSD_Ges_alter_Geschw_Witter m2  : 41|2@1+ (1.0,0.0) [0.0|3] ""  Getriebe_AL551_951_D4_C7,Getriebe_DL501_C7,Getriebe_VL381_C7
 SG_ PSD_Ges_alter_Geschw_Tag_Anf m2  : 43|3@1+ (1.0,0.0) [0.0|7] ""  Getriebe_AL551_951_D4_C7,Getriebe_DL501_C7,Getriebe_VL381_C7
 SG_ PSD_Abz_Anfangskruemmung_Vorz m1  : 45|1@1+ (1.0,0.0) [0.0|1] ""  Getriebe_AL551_951_D4_C7,Getriebe_DL501_C7,Getriebe_VL381_C7
 SG_ PSD_Sys_Anfangskruemmung m0  : 46|8@1+ (1,0) [0|254] "Unit_None"  Getriebe_AL551_951_D4_C7,Getriebe_DL501_C7,Getriebe_VL381_C7
 SG_ PSD_Abz_Endkruemmung m1  : 46|8@1+ (1,0) [0|254] "Unit_None"  Getriebe_AL551_951_D4_C7,Getriebe_DL501_C7,Getriebe_VL381_C7
 SG_ PSD_Ges_alter_Geschw_Tag_Ende m2  : 46|3@1+ (1.0,0.0) [0.0|7] ""  Getriebe_AL551_951_D4_C7,Getriebe_DL501_C7,Getriebe_VL381_C7
 SG_ PSD_Ges_alter_Geschw_Std_Anf m2  : 49|5@1+ (1,0) [0|24] "Unit_Hours"  Getriebe_AL551_951_D4_C7,Getriebe_DL501_C7,Getriebe_VL381_C7
 SG_ PSD_Ort_Hoehe m3  : 53|11@1+ (5,-1000) [-1000|8000] "Unit_Meter"  Getriebe_AL551_951_D4_C7,Getriebe_DL501_C7,Getriebe_VL381_C7
 SG_ PSD_Sys_Anfangskruemmung_Vorz m0  : 54|1@1+ (1.0,0.0) [0.0|1] ""  Getriebe_AL551_951_D4_C7,Getriebe_DL501_C7,Getriebe_VL381_C7
 SG_ PSD_Abz_Endkruemmung_Vorz m1  : 54|1@1+ (1.0,0.0) [0.0|1] ""  Getriebe_AL551_951_D4_C7,Getriebe_DL501_C7,Getriebe_VL381_C7
 SG_ PSD_Ges_alter_Geschw_Std_Ende m2  : 54|5@1+ (1,0) [0|24] "Unit_Hours"  Getriebe_AL551_951_D4_C7,Getriebe_DL501_C7,Getriebe_VL381_C7
 SG_ PSD_Sys_Anfangssteigung m0  : 55|5@1+ (0.5,0) [0.0|14.5] "Unit_PerCent"  Getriebe_AL551_951_D4_C7,Getriebe_DL501_C7,Getriebe_VL381_C7
 SG_ PSD_Abz_Endsteigung m1  : 55|5@1+ (0.5,0) [0.0|14.5] "Unit_PerCent"  Getriebe_AL551_951_D4_C7,Getriebe_DL501_C7,Getriebe_VL381_C7
 SG_ PSD_Ges_Ueberholverbot m2  : 59|2@1+ (1.0,0.0) [0.0|3] ""  Getriebe_AL551_951_D4_C7,Getriebe_DL501_C7,Getriebe_VL381_C7
 SG_ PSD_Sys_Anfangssteigung_Vorz m0  : 60|1@1+ (1.0,0.0) [0.0|1] ""  Getriebe_AL551_951_D4_C7,Getriebe_DL501_C7,Getriebe_VL381_C7
 SG_ PSD_Abz_Endsteigung_Vorz m1  : 60|1@1+ (1.0,0.0) [0.0|1] ""  Getriebe_AL551_951_D4_C7,Getriebe_DL501_C7,Getriebe_VL381_C7
 SG_ PSD_Sys_Ortschaft m0  : 61|1@1+ (1.0,0.0) [0.0|1] ""  Getriebe_AL551_951_D4_C7,Getriebe_DL501_C7,Getriebe_VL381_C7
 SG_ PSD_Abz_Fahrspuren m1  : 61|2@1+ (1.0,0.0) [0.0|3] ""  Getriebe_AL551_951_D4_C7,Getriebe_DL501_C7,Getriebe_VL381_C7
 SG_ PSD_Ges_Wechselverkehrszeichen m2  : 61|3@1+ (1.0,0.0) [0.0|7] ""  Getriebe_AL551_951_D4_C7,Getriebe_DL501_C7,Getriebe_VL381_C7
 SG_ PSD_Sys_Digitalisierung m0  : 62|1@1+ (1.0,0.0) [0.0|1] ""  Getriebe_AL551_951_D4_C7,Getriebe_DL501_C7,Getriebe_VL381_C7
 SG_ PSD_Sys_Zielfuehrung m0  : 63|1@1+ (1.0,0.0) [0.0|1] ""  Getriebe_AL551_951_D4_C7,Getriebe_DL501_C7,Getriebe_VL381_C7
 SG_ PSD_Abz_wahrscheinlichster_Pfad m1  : 63|1@1+ (1.0,0.0) [0.0|1] ""  Getriebe_AL551_951_D4_C7,Getriebe_DL501_C7,Getriebe_VL381_C7

BO_ 2033 Request_Airbag_Deployment: 8 Gateway_D4C7
 SG_ Request_Airbag_Deployment : 0|64@1+ (1.0,0.0) [0.0|18446744073709551615] ""  Airbag_D4

BO_ 2041 Response_Airbag_Deployment: 8 Airbag_D4
 SG_ Response_Airbag_Deployment : 0|64@1+ (1.0,0.0) [0.0|18446744073709551615] ""  Gateway_D4C7

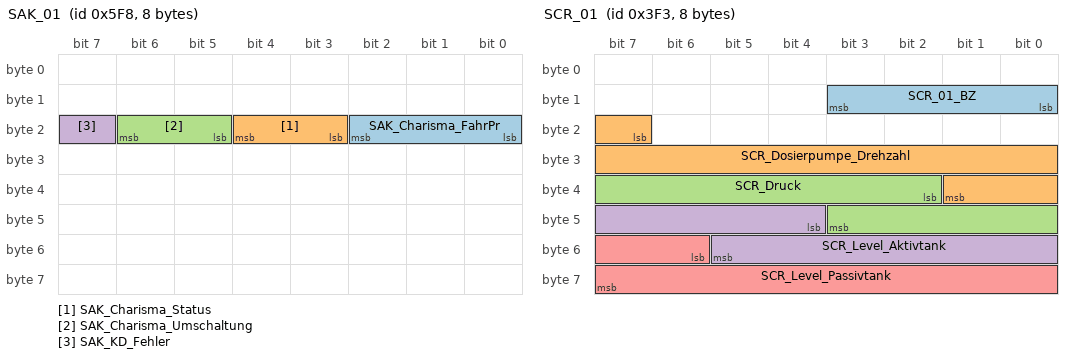
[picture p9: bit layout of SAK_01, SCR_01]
BO_ 1528 SAK_01: 8 SAK_C7
 SG_ SAK_Charisma_FahrPr : 16|3@1+ (1.0,0.0) [0.0|7] ""  Vector__XXX
 SG_ SAK_Charisma_Status : 19|2@1+ (1.0,0.0) [0.0|3] ""  Vector__XXX
 SG_ SAK_Charisma_Umschaltung : 21|2@1+ (1.0,0.0) [0.0|3] ""  Vector__XXX
 SG_ SAK_KD_Fehler : 23|1@1+ (1.0,0.0) [0.0|1] ""  Gateway_D4C7

BO_ 1011 SCR_01: 8 SCR_C7
 SG_ SCR_01_BZ : 8|4@1+ (1,0) [0|15] ""  Motor_EDC17_D4
 SG_ SCR_Dosierpumpe_Drehzahl : 23|11@1+ (4,-4080) [-4080|4100] "Unit_MinutInver"  Motor_EDC17_D4
 SG_ SCR_Druck : 34|10@1+ (5,0) [0|5000] "Unit_MilliVolt"  Motor_EDC17_D4
 SG_ SCR_Level_Aktivtank : 44|10@1+ (5,0) [0|5000] "Unit_MilliVolt"  Motor_EDC17_D4
 SG_ SCR_Level_Passivtank : 54|10@1+ (5,0) [0|5000] "Unit_MilliVolt"  Motor_EDC17_D4

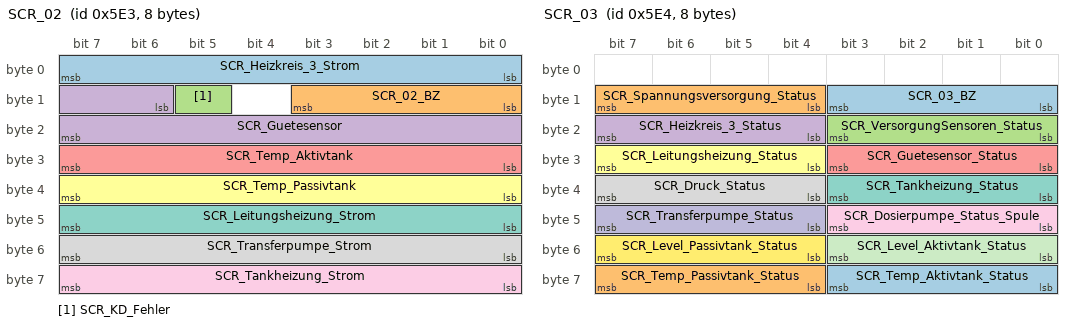
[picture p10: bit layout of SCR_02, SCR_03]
BO_ 1507 SCR_02: 8 SCR_C7
 SG_ SCR_Heizkreis_3_Strom : 0|8@1+ (0.1,0) [0.0|14.0] "Unit_Amper"  Motor_EDC17_D4
 SG_ SCR_02_BZ : 8|4@1+ (1,0) [0|15] ""  Motor_EDC17_D4
 SG_ SCR_KD_Fehler : 13|1@1+ (1.0,0.0) [0.0|1] ""  Gateway_D4C7
 SG_ SCR_Guetesensor : 14|10@1+ (5,0) [0|5000] "Unit_MilliVolt"  Motor_EDC17_D4
 SG_ SCR_Temp_Aktivtank : 24|8@1+ (20,0) [0|5000] "Unit_MilliVolt"  Motor_EDC17_D4
 SG_ SCR_Temp_Passivtank : 32|8@1+ (20,0) [0|5000] "Unit_MilliVolt"  Motor_EDC17_D4
 SG_ SCR_Leitungsheizung_Strom : 40|8@1+ (0.1,0) [0.0|14.0] "Unit_Amper"  Motor_EDC17_D4
 SG_ SCR_Transferpumpe_Strom : 48|8@1+ (0.1,0) [0.0|14.0] "Unit_Amper"  Motor_EDC17_D4
 SG_ SCR_Tankheizung_Strom : 56|8@1+ (0.1,0) [0.0|14.0] "Unit_Amper"  Motor_EDC17_D4

BO_ 1508 SCR_03: 8 SCR_C7
 SG_ SCR_03_BZ : 8|4@1+ (1,0) [0|15] ""  Motor_EDC17_D4
 SG_ SCR_Spannungsversorgung_Status : 12|4@1+ (1.0,0.0) [0.0|15] ""  Motor_EDC17_D4
 SG_ SCR_VersorgungSensoren_Status : 16|4@1+ (1.0,0.0) [0.0|15] ""  Motor_EDC17_D4
 SG_ SCR_Heizkreis_3_Status : 20|4@1+ (1.0,0.0) [0.0|15] ""  Motor_EDC17_D4
 SG_ SCR_Guetesensor_Status : 24|4@1+ (1.0,0.0) [0.0|15] ""  Motor_EDC17_D4
 SG_ SCR_Leitungsheizung_Status : 28|4@1+ (1.0,0.0) [0.0|15] ""  Motor_EDC17_D4
 SG_ SCR_Tankheizung_Status : 32|4@1+ (1.0,0.0) [0.0|15] ""  Motor_EDC17_D4
 SG_ SCR_Druck_Status : 36|4@1+ (1.0,0.0) [0.0|15] ""  Motor_EDC17_D4
 SG_ SCR_Dosierpumpe_Status_Spule : 40|4@1+ (1.0,0.0) [0.0|15] ""  Motor_EDC17_D4
 SG_ SCR_Transferpumpe_Status : 44|4@1+ (1.0,0.0) [0.0|15] ""  Motor_EDC17_D4
 SG_ SCR_Level_Aktivtank_Status : 48|4@1+ (1.0,0.0) [0.0|15] ""  Motor_EDC17_D4
 SG_ SCR_Level_Passivtank_Status : 52|4@1+ (1.0,0.0) [0.0|15] ""  Motor_EDC17_D4
 SG_ SCR_Temp_Aktivtank_Status : 56|4@1+ (1.0,0.0) [0.0|15] ""  Motor_EDC17_D4
 SG_ SCR_Temp_Passivtank_Status : 60|4@1+ (1.0,0.0) [0.0|15] ""  Motor_EDC17_D4

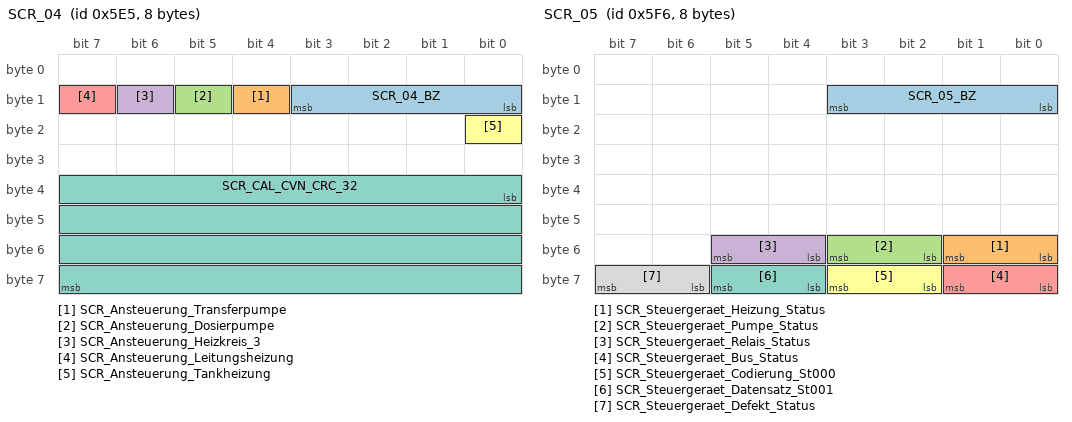
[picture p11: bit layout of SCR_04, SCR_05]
BO_ 1509 SCR_04: 8 SCR_C7
 SG_ SCR_04_BZ : 8|4@1+ (1,0) [0|15] ""  Motor_EDC17_D4
 SG_ SCR_Ansteuerung_Transferpumpe : 12|1@1+ (1.0,0.0) [0.0|1] ""  Motor_EDC17_D4
 SG_ SCR_Ansteuerung_Dosierpumpe : 13|1@1+ (1.0,0.0) [0.0|1] ""  Motor_EDC17_D4
 SG_ SCR_Ansteuerung_Heizkreis_3 : 14|1@1+ (1.0,0.0) [0.0|1] ""  Motor_EDC17_D4
 SG_ SCR_Ansteuerung_Leitungsheizung : 15|1@1+ (1.0,0.0) [0.0|1] ""  Motor_EDC17_D4
 SG_ SCR_Ansteuerung_Tankheizung : 16|1@1+ (1.0,0.0) [0.0|1] ""  Motor_EDC17_D4
 SG_ SCR_CAL_CVN_CRC_32 : 32|32@1+ (1.0,0.0) [0.0|4294967295] ""  Motor_EDC17_D4

BO_ 1526 SCR_05: 8 SCR_C7
 SG_ SCR_05_BZ : 8|4@1+ (1,0) [0|15] ""  Motor_EDC17_D4
 SG_ SCR_Steuergeraet_Heizung_Status : 48|2@1+ (1.0,0.0) [0.0|3] ""  Motor_EDC17_D4
 SG_ SCR_Steuergeraet_Pumpe_Status : 50|2@1+ (1.0,0.0) [0.0|3] ""  Motor_EDC17_D4
 SG_ SCR_Steuergeraet_Relais_Status : 52|2@1+ (1.0,0.0) [0.0|3] ""  Motor_EDC17_D4
 SG_ SCR_Steuergeraet_Bus_Status : 56|2@1+ (1.0,0.0) [0.0|3] ""  Motor_EDC17_D4
 SG_ SCR_Steuergeraet_Codierung_St000 : 58|2@1+ (1.0,0.0) [0.0|3] ""  Motor_EDC17_D4
 SG_ SCR_Steuergeraet_Datensatz_St001 : 60|2@1+ (1.0,0.0) [0.0|3] ""  Motor_EDC17_D4
 SG_ SCR_Steuergeraet_Defekt_Status : 62|2@1+ (1.0,0.0) [0.0|3] ""  Motor_EDC17_D4

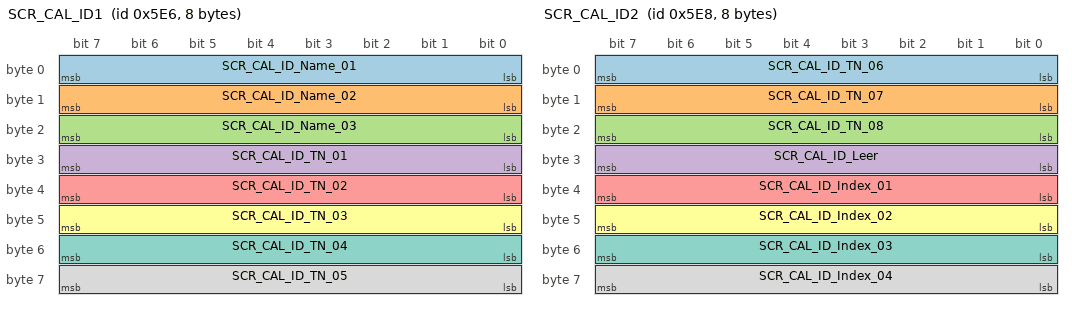
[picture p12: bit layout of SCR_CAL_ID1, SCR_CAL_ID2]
BO_ 1510 SCR_CAL_ID1: 8 SCR_C7
 SG_ SCR_CAL_ID_Name_01 : 0|8@1+ (1.0,0.0) [0.0|255] ""  Motor_EDC17_D4
 SG_ SCR_CAL_ID_Name_02 : 8|8@1+ (1.0,0.0) [0.0|255] ""  Motor_EDC17_D4
 SG_ SCR_CAL_ID_Name_03 : 16|8@1+ (1.0,0.0) [0.0|255] ""  Motor_EDC17_D4
 SG_ SCR_CAL_ID_TN_01 : 24|8@1+ (1.0,0.0) [0.0|255] ""  Motor_EDC17_D4
 SG_ SCR_CAL_ID_TN_02 : 32|8@1+ (1.0,0.0) [0.0|255] ""  Motor_EDC17_D4
 SG_ SCR_CAL_ID_TN_03 : 40|8@1+ (1.0,0.0) [0.0|255] ""  Motor_EDC17_D4
 SG_ SCR_CAL_ID_TN_04 : 48|8@1+ (1.0,0.0) [0.0|255] ""  Motor_EDC17_D4
 SG_ SCR_CAL_ID_TN_05 : 56|8@1+ (1.0,0.0) [0.0|255] ""  Motor_EDC17_D4

BO_ 1512 SCR_CAL_ID2: 8 SCR_C7
 SG_ SCR_CAL_ID_TN_06 : 0|8@1+ (1.0,0.0) [0.0|255] ""  Motor_EDC17_D4
 SG_ SCR_CAL_ID_TN_07 : 8|8@1+ (1.0,0.0) [0.0|255] ""  Motor_EDC17_D4
 SG_ SCR_CAL_ID_TN_08 : 16|8@1+ (1.0,0.0) [0.0|255] ""  Motor_EDC17_D4
 SG_ SCR_CAL_ID_Leer : 24|8@1+ (1.0,0.0) [0.0|255] ""  Motor_EDC17_D4
 SG_ SCR_CAL_ID_Index_01 : 32|8@1+ (1.0,0.0) [0.0|255] ""  Motor_EDC17_D4
 SG_ SCR_CAL_ID_Index_02 : 40|8@1+ (1.0,0.0) [0.0|255] ""  Motor_EDC17_D4
 SG_ SCR_CAL_ID_Index_03 : 48|8@1+ (1.0,0.0) [0.0|255] ""  Motor_EDC17_D4
 SG_ SCR_CAL_ID_Index_04 : 56|8@1+ (1.0,0.0) [0.0|255] ""  Motor_EDC17_D4

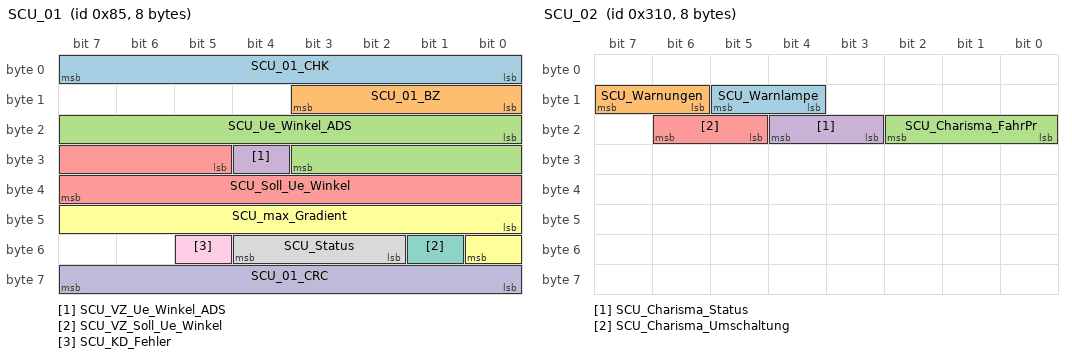
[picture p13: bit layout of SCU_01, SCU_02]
BO_ 133 SCU_01: 8 SCU_D4
 SG_ SCU_01_CHK : 0|8@1+ (1,0) [0|255] ""  Airbag_D4,ESP_D4,Gateway_D4C7,Motor_EDC17_D4,Motor_ME17_BY,Motor_MED17_SIMOS8_D4,QSP_D4
 SG_ SCU_01_BZ : 8|4@1+ (1,0) [0|15] ""  Airbag_D4,ESP_D4,Gateway_D4C7,Motor_EDC17_D4,Motor_ME17_BY,Motor_MED17_SIMOS8_D4,QSP_D4
 SG_ SCU_Ue_Winkel_ADS : 16|12@1+ (0.1,0) [0.0|409.3] "Unit_DegreOfArc"  Airbag_D4,ESP_D4,Gateway_D4C7,Motor_EDC17_D4,Motor_ME17_BY,Motor_MED17_SIMOS8_D4,QSP_D4
 SG_ SCU_VZ_Ue_Winkel_ADS : 28|1@1+ (1.0,0.0) [0.0|1] ""  Airbag_D4,ESP_D4,Gateway_D4C7,Motor_EDC17_D4,Motor_ME17_BY,Motor_MED17_SIMOS8_D4,QSP_D4
 SG_ SCU_Soll_Ue_Winkel : 29|11@1+ (0.1,0) [0.0|204.5] "Unit_DegreOfArc"  ESP_D4,Gateway_D4C7,QSP_D4
 SG_ SCU_max_Gradient : 40|9@1+ (1,0) [0|510] ""  ESP_D4,Gateway_D4C7,QSP_D4
 SG_ SCU_VZ_Soll_Ue_Winkel : 49|1@1+ (1.0,0.0) [0.0|1] ""  ESP_D4,Gateway_D4C7,QSP_D4
 SG_ SCU_Status : 50|3@1+ (1.0,0.0) [0.0|7] ""  ESP_D4,Gateway_D4C7,QSP_D4
 SG_ SCU_KD_Fehler : 53|1@1+ (1.0,0.0) [0.0|1] ""  ESP_D4,Gateway_D4C7,QSP_D4
 SG_ SCU_01_CRC : 56|8@1+ (1,0) [0|255] ""  ESP_D4,Gateway_D4C7,QSP_D4

BO_ 784 SCU_02: 8 SCU_D4
 SG_ SCU_Warnlampe : 12|2@1+ (1.0,0.0) [0.0|3] ""  Gateway_D4C7
 SG_ SCU_Warnungen : 14|2@1+ (1.0,0.0) [0.0|3] ""  Gateway_D4C7
 SG_ SCU_Charisma_FahrPr : 16|3@1+ (1.0,0.0) [0.0|7] ""  Gateway_D4C7
 SG_ SCU_Charisma_Status : 19|2@1+ (1.0,0.0) [0.0|3] ""  Gateway_D4C7
 SG_ SCU_Charisma_Umschaltung : 21|2@1+ (1.0,0.0) [0.0|3] ""  Gateway_D4C7

BO_ 1313 STH_01: 8 Gateway_D4C7
 SG_ STH_Funk_ein : 0|1@1+ (1.0,0.0) [0.0|1] ""  Vector__XXX
 SG_ STH_Funk_aus : 1|1@1+ (1.0,0.0) [0.0|1] ""  Vector__XXX
 SG_ STH_Zusatzheizung : 2|1@1+ (1.0,0.0) [0.0|1] ""  Vector__XXX
 SG_ STH_LED : 3|1@1+ (1.0,0.0) [0.0|1] ""  Motor_EDC17_D4,Motor_ME17_BY,Motor_MED17_SIMOS8_D4
 SG_ STH_Pumpe_ein : 4|1@1+ (1,0) [0|1] ""  Vector__XXX
 SG_ STH_Geblaese : 5|1@1+ (1.0,0.0) [0.0|1] ""  Vector__XXX
 SG_ STH_EKP_Anst : 6|1@1+ (1.0,0.0) [0.0|1] ""  Motor_EDC17_D4,Motor_ME17_BY,Motor_MED17_SIMOS8_D4
 SG_ STH_Start_folgt : 7|1@1+ (1.0,0.0) [0.0|1] ""  Vector__XXX
 SG_ STH_Ventiloeffnungszeit : 8|6@1+ (1,0) [0|63] "Unit_Minut"  Vector__XXX
 SG_ STH_Ventil_Status : 14|1@1+ (1.0,0.0) [0.0|1] ""  Vector__XXX
 SG_ STH_Waermeeintrag : 16|6@1+ (1,0) [0|63] ""  Vector__XXX
 SG_ STH_KVS : 24|13@1+ (1,0) [0|8191] "Unit_MilliLiter"  Vector__XXX
 SG_ STH_Fehlerstatus : 37|3@1+ (1.0,0.0) [0.0|7] ""  Vector__XXX
 SG_ STH_Heizleistung : 40|8@1+ (1,0) [0|255] ""  Vector__XXX
 SG_ STH_Wassertemp : 48|8@1+ (0.75,-40) [-40.00|142.25] "Unit_DegreCelsi"  Vector__XXX
 SG_ STH_Motorvorwaermung : 59|1@1+ (1.0,0.0) [0.0|1] ""  Motor_EDC17_D4,Motor_ME17_BY,Motor_MED17_SIMOS8_D4
 SG_ STH_Servicemode : 60|1@1+ (1,0) [0|1] ""  Vector__XXX
 SG_ STH_war_aktiv : 61|1@1+ (1.0,0.0) [0.0|1] ""  Motor_EDC17_D4,Motor_ME17_BY,Motor_MED17_SIMOS8_D4
 SG_ STH_KVS_Ueberlauf : 62|1@1+ (1.0,0.0) [0.0|1] ""  Vector__XXX
 SG_ STH_KD_Fehler : 63|1@1+ (1.0,0.0) [0.0|1] ""  Vector__XXX

BO_ 1172 STS_01: 8 Gateway_D4C7
 SG_ STS_01_CHK : 0|8@1+ (1,0) [0|255] ""  Motor_EDC17_D4,Motor_ME17_BY,Motor_MED17_SIMOS8_D4
 SG_ STS_01_BZ : 8|4@1+ (1,0) [0|15] ""  Motor_EDC17_D4,Motor_ME17_BY,Motor_MED17_SIMOS8_D4
 SG_ STS_Car_not_under_theft : 12|1@1+ (1.0,0.0) [0.0|1] ""  Vector__XXX
 SG_ STS_Car_under_theft : 13|1@1+ (1.0,0.0) [0.0|1] ""  Vector__XXX
 SG_ STS_Anlassersperre : 15|1@1+ (1.0,0.0) [0.0|1] ""  Vector__XXX
 SG_ STS_Typencodierung : 16|5@1+ (1.0,0.0) [0.0|31] ""  Vector__XXX
 SG_ STS_KD_Fehler : 22|1@1+ (1.0,0.0) [0.0|1] ""  Vector__XXX
 SG_ STS_LIN_aktiv : 23|1@1+ (1.0,0.0) [0.0|1] ""  Vector__XXX
 SG_ STS_Standlicht : 24|1@1+ (1.0,0.0) [0.0|1] ""  Vector__XXX
 SG_ STS_Fahrlicht : 25|1@1+ (1.0,0.0) [0.0|1] ""  Vector__XXX
 SG_ STS_Alarm_still : 26|1@1+ (1.0,0.0) [0.0|1] ""  Vector__XXX
 SG_ STS_Texte : 27|4@1+ (1.0,0.0) [0.0|15] ""  Vector__XXX
 SG_ STS_Laderelais : 38|1@1+ (1.0,0.0) [0.0|1] ""  Vector__XXX
 SG_ STS_Summer : 48|1@1+ (1.0,0.0) [0.0|1] ""  Vector__XXX
 SG_ STS_Alarm_Blinker : 50|1@1+ (1.0,0.0) [0.0|1] ""  Vector__XXX
 SG_ STS_Notstart : 51|1@1+ (1.0,0.0) [0.0|1] ""  Vector__XXX
 SG_ STS_Signalhorn : 55|1@1+ (1.0,0.0) [0.0|1] ""  Vector__XXX
 SG_ STS_Leerlaufschaltung : 56|1@1+ (1.0,0.0) [0.0|1] ""  Motor_EDC17_D4,Motor_ME17_BY,Motor_MED17_SIMOS8_D4

BO_ 783 SWA_01: 8 Gateway_D4C7
 SG_ SWA_Status_CHK : 0|8@1+ (1,0) [0|255] ""  Vector__XXX
 SG_ SWA_Status_BZ : 8|4@1+ (1,0) [0|15] ""  Vector__XXX
 SG_ SWA_Anzeigen : 12|4@1+ (1.0,0.0) [0.0|15] ""  Kombi_D4
 SG_ SWA_Blindheit_erkannt : 16|1@1+ (1.0,0.0) [0.0|1] ""  Vector__XXX
 SG_ SWA_rel_Nichtverf : 17|1@1+ (1.0,0.0) [0.0|1] ""  Vector__XXX
 SG_ SWA_rel_Fehler : 18|1@1+ (1.0,0.0) [0.0|1] ""  Vector__XXX
 SG_ SWA_Sta_aktiv : 19|1@1+ (1.0,0.0) [0.0|1] ""  Vector__XXX
 SG_ SWA_Sta_passiv : 20|1@1+ (1.0,0.0) [0.0|1] ""  Vector__XXX
 SG_ SWA_Standziele_li : 24|1@1+ (1.0,0.0) [0.0|1] ""  Vector__XXX
 SG_ SWA_Kolonne_li : 25|1@1+ (1.0,0.0) [0.0|1] ""  Vector__XXX
 SG_ SWA_Infostufe_SWA_li : 26|1@1+ (1.0,0.0) [0.0|1] ""  Vector__XXX
 SG_ SWA_Warnung_SWA_li : 27|1@1+ (1.0,0.0) [0.0|1] ""  Vector__XXX
 SG_ SWA_Kolonne_mi : 33|1@1+ (1.0,0.0) [0.0|1] ""  Vector__XXX
 SG_ SWA_Standziele_re : 40|1@1+ (1.0,0.0) [0.0|1] ""  Vector__XXX
 SG_ SWA_Kolonne_re : 41|1@1+ (1.0,0.0) [0.0|1] ""  Vector__XXX
 SG_ SWA_Infostufe_SWA_re : 42|1@1+ (1.0,0.0) [0.0|1] ""  Vector__XXX
 SG_ SWA_Warnung_SWA_re : 43|1@1+ (1.0,0.0) [0.0|1] ""  Vector__XXX
 SG_ SWA_Gischtzaehler : 48|7@1+ (1,0) [0|100] "Unit_PerCent"  Vector__XXX
 SG_ SWA_KD_Fehler : 59|1@1+ (1.0,0.0) [0.0|1] ""  Vector__XXX

BO_ 1413 Systeminfo_01: 8 Gateway_D4C7
 SG_ SI_Int_CAN_gespiegelt : 0|1@1+ (1.0,0.0) [0.0|1] ""  Vector__XXX
 SG_ SI_CAN_Komfort_Sleep : 1|1@1+ (1.0,0.0) [0.0|1] ""  Vector__XXX
 SG_ SI_CAN_Dashboard_Sleep : 2|1@1+ (1.0,0.0) [0.0|1] ""  Vector__XXX
 SG_ SI_CAN_Antrieb_Sleep : 3|1@1+ (1.0,0.0) [0.0|1] ""  Vector__XXX
 SG_ SI_Infotainment_Sleep : 4|1@1+ (1.0,0.0) [0.0|1] ""  Vector__XXX
 SG_ SI_CAN_Extended_Sleep : 5|1@1+ (1.0,0.0) [0.0|1] ""  Vector__XXX
 SG_ SI_Fahrwerk_Sleep : 6|1@1+ (1.0,0.0) [0.0|1] ""  Vector__XXX
 SG_ SI_Diagnose_Aktiv : 7|1@1+ (1.0,0.0) [0.0|1] ""  Vector__XXX
 SG_ SI_QRS_Mode : 8|1@1+ (1.0,0.0) [0.0|1] ""  Getriebe_AL551_951_D4_C7
 SG_ SI_T_Mode : 9|1@1+ (1.0,0.0) [0.0|1] ""  Getriebe_AL551_951_D4_C7,Motor_EDC17_D4,Motor_ME17_BY,Motor_MED17_SIMOS8_D4
 SG_ SI_NWDF : 10|1@1+ (1.0,0.0) [0.0|1] ""  Vector__XXX
 SG_ SI_NWDF_gueltig : 11|1@1+ (1.0,0.0) [0.0|1] ""  Vector__XXX
 SG_ SI_Sammelfehler : 12|1@1+ (1.0,0.0) [0.0|1] ""  Vector__XXX
 SG_ GW_KD_Fehler : 13|1@1+ (1.0,0.0) [0.0|1] ""  Vector__XXX
 SG_ SI_MOST_Status : 15|1@1+ (1.0,0.0) [0.0|1] ""  Vector__XXX
 SG_ SI_Sammel_SG_Fehler : 56|6@1+ (1,0) [0|60] ""  Vector__XXX
 SG_ SI_MO_WU : 63|1@1+ (1.0,0.0) [0.0|1] ""  Vector__XXX

BO_ 1214 TPD_SCU_01: 8 Gateway_D4C7
 SG_ TPD_SCU_Data_1 : 0|64@1+ (1.0,0.0) [0.0|18446744073709551615] ""  SCU_D4

BO_ 768 TPD_Tester_01: 8 SCU_D4
 SG_ TPD_Tester_Data_1 : 0|64@1+ (1.0,0.0) [0.0|18446744073709551615] ""  Gateway_D4C7

BO_ 769 TPD_Tester_02: 8 SCU_D4
 SG_ TPD_Tester_Data_2 : 0|64@1+ (1.0,0.0) [0.0|18446744073709551615] ""  Gateway_D4C7

BO_ 770 TPD_Tester_03: 8 SCU_D4
 SG_ TPD_Tester_Data_3 : 0|64@1+ (1.0,0.0) [0.0|18446744073709551615] ""  Gateway_D4C7

BO_ 771 TPD_Tester_04: 8 SCU_D4
 SG_ TPD_Tester_Data_4 : 0|64@1+ (1.0,0.0) [0.0|18446744073709551615] ""  Gateway_D4C7

BO_ 772 TPD_Tester_05: 8 SCU_D4
 SG_ TPD_Tester_Data_5 : 0|64@1+ (1.0,0.0) [0.0|18446744073709551615] ""  Gateway_D4C7

BO_ 773 TPD_Tester_06: 8 SCU_D4
 SG_ TPD_Tester_Data_6 : 0|64@1+ (1.0,0.0) [0.0|18446744073709551615] ""  Gateway_D4C7

BO_ 774 TPD_Tester_07: 8 SCU_D4
 SG_ TPD_Tester_Data_7 : 0|64@1+ (1.0,0.0) [0.0|18446744073709551615] ""  Gateway_D4C7

BO_ 775 TPD_Tester_08: 8 SCU_D4
 SG_ TPD_Tester_Data_8 : 0|64@1+ (1.0,0.0) [0.0|18446744073709551615] ""  Gateway_D4C7

BO_ 542 TPS_SCU: 7 SCU_D4
 SG_ TPS_SCU_Data : 0|56@1+ (1.0,0.0) [0.0|72057594037927935] ""  Gateway_D4C7

BO_ 512 TPS_Tester: 7 Gateway_D4C7
 SG_ TPS_Tester_Data : 0|56@1+ (1.0,0.0) [0.0|72057594037927935] ""  SCU_D4

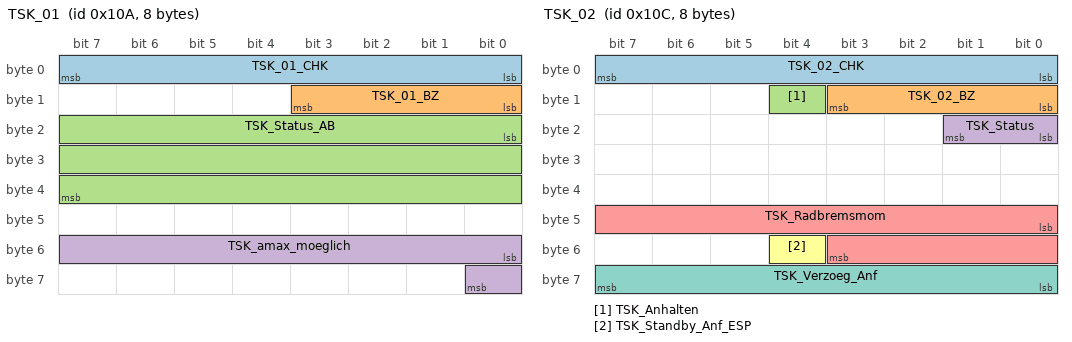
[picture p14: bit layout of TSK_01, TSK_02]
BO_ 266 TSK_01: 8 Motor_MLB_AU48_AU416_Diesel
 SG_ TSK_01_CHK : 0|8@1+ (1,0) [0|255] ""  Gateway_B8
 SG_ TSK_01_BZ : 8|4@1+ (1,0) [0|15] ""  Gateway_B8
 SG_ TSK_Status_AB : 16|24@1+ (1,0) [0|16777215] ""  Gateway_B8
 SG_ TSK_amax_moeglich : 48|9@1+ (0.024,-2.016) [-2.016|10.224] "Unit_MeterPerSeconSquar"  Gateway_B8

BO_ 268 TSK_02: 8 Motor_MLB_AU48_AU416_Diesel
 SG_ TSK_02_CHK : 0|8@1+ (1,0) [0|255] ""  Gateway_B8,Getriebe_AL551_651_B8,Getriebe_AL551_Q5_Hybrid,Getriebe_SL_LB
 SG_ TSK_02_BZ : 8|4@1+ (1,0) [0|15] ""  Gateway_B8,Getriebe_AL551_651_B8,Getriebe_AL551_Q5_Hybrid,Getriebe_SL_LB
 SG_ TSK_Anhalten : 12|1@1+ (1,0) [0|1] ""  Gateway_B8
 SG_ TSK_Status : 16|2@1+ (1,0) [0|3] "" XXX
 SG_ TSK_Radbremsmom : 40|12@1+ (8,0) [0|32760] "Unit_NewtoMeter"  Gateway_B8
 SG_ TSK_Standby_Anf_ESP : 52|1@1+ (1,0) [0|1] ""  Gateway_B8
 SG_ TSK_Verzoeg_Anf : 56|8@1+ (0.024,-3.984) [-3.984|2.112] "Unit_MeterPerSeconSquar"  Gateway_B8

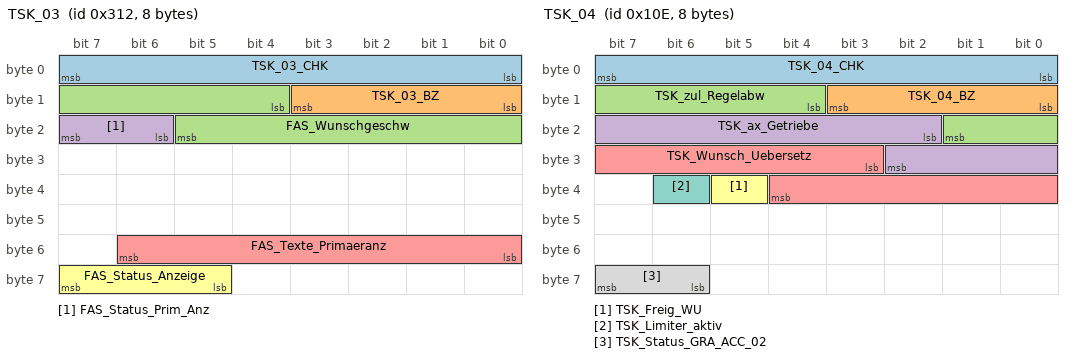
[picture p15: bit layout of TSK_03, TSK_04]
BO_ 786 TSK_03: 8 Motor_EDC17_D4
 SG_ TSK_03_CHK : 0|8@1+ (1,0) [0|255] ""  Gateway_D4C7
 SG_ TSK_03_BZ : 8|4@1+ (1,0) [0|15] ""  Gateway_D4C7
 SG_ FAS_Wunschgeschw : 12|10@1+ (0.32,0) [0.00|326.72] "Unit_KiloMeterPerHour"  Gateway_D4C7
 SG_ FAS_Status_Prim_Anz : 22|2@1+ (1.0,0.0) [0.0|3] ""  Gateway_D4C7
 SG_ FAS_Texte_Primaeranz : 48|7@1+ (1.0,0.0) [0.0|127] ""  Gateway_D4C7
 SG_ FAS_Status_Anzeige : 61|3@1+ (1.0,0.0) [0.0|7] ""  Gateway_D4C7

BO_ 270 TSK_04: 8 Motor_EDC17_D4
 SG_ TSK_04_CHK : 0|8@1+ (1,0) [0|255] ""  Getriebe_AL551_951_D4_C7,Getriebe_DL501_C7,Getriebe_VL381_C7
 SG_ TSK_04_BZ : 8|4@1+ (1,0) [0|15] ""  Getriebe_AL551_951_D4_C7,Getriebe_DL501_C7,Getriebe_VL381_C7
 SG_ TSK_zul_Regelabw : 12|6@1+ (0.024,0) [0.000|1.512] "Unit_MeterPerSeconSquar"  Getriebe_AL551_951_D4_C7,Getriebe_DL501_C7,Getriebe_VL381_C7
 SG_ TSK_ax_Getriebe : 18|9@1+ (0.024,-2.016) [-2.016|10.224] "Unit_MeterPerSeconSquar"  Getriebe_AL551_951_D4_C7,Getriebe_DL501_C7,Getriebe_VL381_C7
 SG_ TSK_Wunsch_Uebersetz : 27|10@1+ (0.0245,0) [0.0245|25.0635] ""  Getriebe_AL551_951_D4_C7,Getriebe_DL501_C7,Getriebe_VL381_C7
 SG_ TSK_Freig_WU : 37|1@1+ (1.0,0.0) [0.0|1] ""  Getriebe_AL551_951_D4_C7,Getriebe_DL501_C7,Getriebe_VL381_C7
 SG_ TSK_Limiter_aktiv : 38|1@1+ (1.0,0.0) [0.0|1] ""  Getriebe_AL551_951_D4_C7,Getriebe_DL501_C7,Getriebe_VL381_C7
 SG_ TSK_Status_GRA_ACC_02 : 62|2@1+ (1.0,0.0) [0.0|3] ""  Getriebe_AL551_951_D4_C7,Getriebe_DL501_C7,Getriebe_VL381_C7

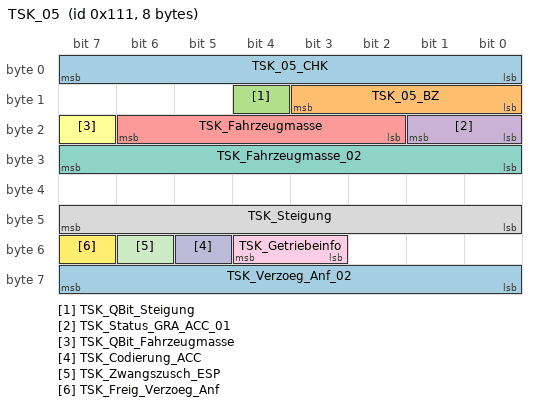
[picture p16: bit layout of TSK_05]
BO_ 273 TSK_05: 8 Motor_EDC17_D4
 SG_ TSK_05_CHK : 0|8@1+ (1,0) [0|255] ""  EPB_D4,Gateway_D4C7,Getriebe_AL551_951_D4_C7,Getriebe_DL501_C7,Getriebe_VL381_C7
 SG_ TSK_05_BZ : 8|4@1+ (1,0) [0|15] ""  EPB_D4,Gateway_D4C7,Getriebe_AL551_951_D4_C7,Getriebe_DL501_C7,Getriebe_VL381_C7
 SG_ TSK_QBit_Steigung : 12|1@1+ (1.0,0.0) [0.0|1] ""  Gateway_D4C7,Getriebe_AL551_951_D4_C7,Getriebe_DL501_C7,Getriebe_VL381_C7
 SG_ TSK_Status_GRA_ACC_01 : 16|2@1+ (1.0,0.0) [0.0|3] ""  Gateway_D4C7
 SG_ TSK_Fahrzeugmasse : 18|5@1+ (200,500) [500|6500] "Unit_KiloGram"  Gateway_D4C7
 SG_ TSK_QBit_Fahrzeugmasse : 23|1@1+ (1.0,0.0) [0.0|1] ""  Gateway_D4C7,Getriebe_AL551_951_D4_C7,Getriebe_DL501_C7,Getriebe_VL381_C7
 SG_ TSK_Fahrzeugmasse_02 : 24|8@1+ (32,0) [0|8128] "Unit_KiloGram"  Gateway_D4C7,Getriebe_AL551_951_D4_C7,Getriebe_DL501_C7,Getriebe_VL381_C7
 SG_ TSK_Steigung : 40|8@1+ (0.8,-101.6) [-101.6|101.6] "Unit_PerCent"  Gateway_D4C7,Getriebe_AL551_951_D4_C7,Getriebe_DL501_C7,Getriebe_VL381_C7
 SG_ TSK_Getriebeinfo : 51|2@1+ (1.0,0.0) [0.0|3] ""  Gateway_D4C7
 SG_ TSK_Codierung_ACC : 53|1@1+ (1.0,0.0) [0.0|1] ""  EPB_D4,Gateway_D4C7,Getriebe_AL551_951_D4_C7,Getriebe_DL501_C7,Getriebe_VL381_C7
 SG_ TSK_Zwangszusch_ESP : 54|1@1+ (1.0,0.0) [0.0|1] ""  Gateway_D4C7
 SG_ TSK_Freig_Verzoeg_Anf : 55|1@1+ (1.0,0.0) [0.0|1] ""  Gateway_D4C7,Getriebe_AL551_951_D4_C7,Getriebe_DL501_C7,Getriebe_VL381_C7
 SG_ TSK_Verzoeg_Anf_02 : 56|8@1+ (0.024,-3.984) [-3.984|2.136] "Unit_MeterPerSeconSquar"  Gateway_D4C7

BO_ 1716 VIN_01: 8 Gateway_D4C7
 SG_ VIN_01_MUX M  : 0|2@1+ (1,0) [0|3] ""  Airbag_D4,EPB_D4,LWS_D4,SCR_C7,SCU_D4
 SG_ KS_Geheimnis_1 m0  : 8|8@1+ (1,0) [0|255] ""  Airbag_D4,EPB_D4
 SG_ VIN_4 m1  : 8|8@1+ (1,0) [0|255] ""  Airbag_D4,EPB_D4,SCR_C7
 SG_ VIN_11 m2  : 8|8@1+ (1,0) [0|255] ""  Airbag_D4,EPB_D4,SCR_C7
 SG_ KS_Geheimnis_2 m0  : 16|8@1+ (1,0) [0|255] ""  Airbag_D4,EPB_D4
 SG_ VIN_5 m1  : 16|8@1+ (1,0) [0|255] ""  Airbag_D4,EPB_D4,SCR_C7
 SG_ VIN_12 m2  : 16|8@1+ (1,0) [0|255] ""  Airbag_D4,EPB_D4,SCR_C7
 SG_ KS_Geheimnis_3 m0  : 24|8@1+ (1,0) [0|255] ""  Airbag_D4,EPB_D4
 SG_ VIN_6 m1  : 24|8@1+ (1,0) [0|255] ""  Airbag_D4,EPB_D4,SCR_C7
 SG_ VIN_13 m2  : 24|8@1+ (1,0) [0|255] ""  Airbag_D4,EPB_D4,SCR_C7
 SG_ KS_Geheimnis_4 m0  : 32|8@1+ (1,0) [0|255] ""  Airbag_D4,EPB_D4
 SG_ VIN_7 m1  : 32|8@1+ (1,0) [0|255] ""  Airbag_D4,EPB_D4,SCR_C7
 SG_ VIN_14 m2  : 32|8@1+ (1,0) [0|255] ""  Airbag_D4,EPB_D4,LWS_D4,SCR_C7,SCU_D4
 SG_ VIN_1 m0  : 40|8@1+ (1,0) [0|255] ""  Airbag_D4,EPB_D4,SCR_C7
 SG_ VIN_8 m1  : 40|8@1+ (1,0) [0|255] ""  Airbag_D4,EPB_D4,SCR_C7
 SG_ VIN_15 m2  : 40|8@1+ (1,0) [0|255] ""  Airbag_D4,EPB_D4,LWS_D4,SCR_C7,SCU_D4
 SG_ VIN_2 m0  : 48|8@1+ (1,0) [0|255] ""  Airbag_D4,EPB_D4,SCR_C7
 SG_ VIN_9 m1  : 48|8@1+ (1,0) [0|255] ""  Airbag_D4,EPB_D4,SCR_C7
 SG_ VIN_16 m2  : 48|8@1+ (1,0) [0|255] ""  Airbag_D4,EPB_D4,LWS_D4,SCR_C7,SCU_D4
 SG_ VIN_3 m0  : 56|8@1+ (1,0) [0|255] ""  Airbag_D4,EPB_D4,SCR_C7
 SG_ VIN_10 m1  : 56|8@1+ (1,0) [0|255] ""  Airbag_D4,EPB_D4,SCR_C7
 SG_ VIN_17 m2  : 56|8@1+ (1,0) [0|255] ""  Airbag_D4,EPB_D4,LWS_D4,SCR_C7,SCU_D4

BO_ 1414 Waehlhebel_02: 8 Getriebe_AL551_951_D4_C7
 SG_ WH_KD_Fehler : 63|1@1+ (1.0,0.0) [0.0|1] ""  Gateway_D4C7

VAL_ 267 LS_Hauptschalter 0 "Gerastet Aus" 1 "Ein" ;
VAL_ 267 LS_Abbrechen 0 "Tippschalter nicht betaetigt" 1 "Tippschalter betaetigt" ;
VAL_ 267 LS_Typ_Hauptschalter 0 "gerasteter_Lenkstockschalter" 1 "getasteter_Lenkstockschalter" ;
VAL_ 267 LS_Limiter 0 "Limiter aus" 1 "Limiter ein" ;
VAL_ 267 LS_Tip_Setzen 0 "Tippschalter nicht betaetigt" 1 "Tippschalter betaetigt" ;
VAL_ 267 LS_Tip_Hoch 0 "Tippschalter nicht betaetigt" 1 "Tippschalter betaetigt" ;
VAL_ 267 LS_Tip_Runter 0 "Tippschalter nicht betaetigt" 1 "Tippschalter betaetigt" ;
VAL_ 267 LS_Tip_Wiederaufnahme 0 "Tippschalter nicht betaetigt" 1 "Tippschalter betaetigt" ;
VAL_ 267 LS_Verstellung_Zeitluecke 0 "Taste nicht betaetigt" 1 "Dist -1" 2 "Dist +1" 3 "nicht belegt" ;
VAL_ 267 MFL_Tip_Down 0 "nicht_betaetigt" 1 "betaetigt" ;
VAL_ 267 MFL_Tip_Up 0 "nicht_betaetigt" 1 "betaetigt" ;
VAL_ 267 LS_Tiptronic_Fehler 0 " i. O." 1 "Fehler erkannt" ;
VAL_ 267 LS_Codierung 0 "kein Hebel, keine Tiptronic am Lenkrad" 1 "kein Hebel, Tiptronic am Lenkrad" 2 "GRA Hebel, keine Tiptronic am Lenkrad" 3 "GRA Hebel, Tiptronic am Lenkrad" 4 "ACC Hebel, keine Tiptronic am Lenkrad" 5 "ACC Hebel, Tiptronic am Lenkrad" 6 "nicht verwendet" 7 "nicht verwendet" ;
VAL_ 267 LS_Tip_Stufe_2 0 "Hebelbetaetigung_in_erster_Tipstufe__Keine_Hebelbetaetigung" 1 "Hebelbetaetigung_in_der_zweiten_Tipstufe" ;
VAL_ 267 LS_GRA_ACC_2stufig 0 "kein_zweistufiger_Hebel_verbaut" 1 "zweistufiger_Hebel_verbaut" ;
VAL_ 267 MFL_M_Taste 0 "nicht_betaetigt" 1 "betaetigt" ;
VAL_ 134 LWI_Sensorstatus 0 "iO" 1 "nicht kalibriert" ;
VAL_ 134 LWI_QBit_Sub_Daten 0 "LWS-Subinfo 'real' (Lenkradwinkelinformation ADS-tauglich) " 1 "LWS-Subinfo 'simuliert' (Lenkradwinkelinformation nicht ADS-tauglich )" ;
VAL_ 134 LWI_QBit_Lenkradwinkel 0 "g�ltiger Wert" 1 "ausserhalb der Spezifikation" ;
VAL_ 134 LWI_Lenkradwinkel 8190 "Init" 8191 "Fehler" ;
VAL_ 134 LWI_VZ_Lenkradwinkel 0 "positiv_links_von_der_Nullstellung" 1 "negativ" ;
VAL_ 134 LWI_VZ_Lenkradw_Geschw 0 "positiv_links_von_der_Nullstellung" 1 "negativ" ;
VAL_ 134 LWI_Lenkradw_Geschw 510 "Init" 511 "Fehler" ;
VAL_ 128 MO_Mom_o_ex 1022 "Init" 1023 "Fehler" ;
VAL_ 128 MO_Mom_m_ex 1022 "Init" 1023 "Fehler" ;
VAL_ 128 MO_Mom_Verlust 1022 "Init" 1023 "Fehler" ;
VAL_ 128 MO_Mom_Begrenzung 1022 "Init" 1023 "Fehler" ;
VAL_ 128 MO_Mom_Fahrerwunsch 1022 "Init" 1023 "Fehler" ;
VAL_ 128 MO_Kickdown 0 "kein Kickdown" 1 "Kickdown" ;
VAL_ 128 MO_KD_Fehler 0 "kein_KD_Fehler" 1 "KD_Fehler" ;
VAL_ 129 MO_Mom_ZWR 1022 "Init" 1023 "Fehler" ;
VAL_ 129 MO_Mom_Soll 1022 "Init" 1023 "Fehler" ;
VAL_ 129 MO_Mom_Ist 1022 "Init" 1023 "Fehler" ;
VAL_ 129 MO_Status_Zylabschalt_01 0 "alle Zylinder brennen" 1 "mindestens ein Zylinder wurde abgeschaltet" ;
VAL_ 129 MO_Status_Normalbetrieb_01 0 "kein Normalbetrieb" 1 "Normalbetrieb erreicht" ;
VAL_ 129 MO_StartStopp_Status 0 "System_in_diesem_KL15_Zyklus_nicht_verfuegbar" 1 "System_aktiv_keine_Freigabe_durch_StartStop_Koordinator" 2 "System_aktiv_alle Freigaben_liegen_vor" 3 "System_aktiv_mindestens_eine_Freigabe_fehlt" ;
VAL_ 129 MO_StartStopp_Motorstopp 0 "Motor_Stop_inaktiv" 1 "Motor_Stop_aktiv" ;
VAL_ 129 MO_StartStopp_Wiederstart 0 "Wiederstart_inaktiv" 1 "Wiederstart_aktiv" ;
VAL_ 129 MO_Ext_E_Fahrt_aktiv 0 "Rueckmeldung_E_Taster_aus " 1 "Rueckmeldung_E_Taster_ein" ;
VAL_ 129 MO_Gangposition 0 "Gang_N" 1 "Gang_1" 2 "Gang_2" 3 "Gang_3" 4 "Gang_4" 5 "Gang_5" 6 "Gang_6" 7 "Gang_7" 8 "Gang_8" 12 "Zwischengangstellung" 13 "Gang_R" 14 "Istgang_nicht_definiert" 15 "Fehler" ;
VAL_ 129 MO_StartStopp_Fahrerwunsch 0 "Init" 1 "Stoppverbot_durch_Fahrer" 2 "Stoppfreigabe_durch_Fahrer" 3 "Stoppanforderung_durch_Fahrer" ;
VAL_ 261 MO_QBit_Fahrpedalwerte_01 0 "gueltiger_Wert" 1 "Ersatz_Init_oder_Fehlerwert" ;
VAL_ 261 MO_QBit_Motormomente 0 "gueltiger_Wert" 1 "Ersatz_Init_oder_Fehlerwert" ;
VAL_ 261 MO_QBit_Fahrer_bremst 0 "gueltiger_Wert" 1 "Ersatz_Init_oder_Fehlerwert" ;
VAL_ 261 MO_QBit_Drehzahl_01 0 "gueltiger_Wert" 1 "Ersatz_Init_oder_Fehlerwert" ;
VAL_ 261 MO_Drehzahl_01 65535 "Fehler" ;
VAL_ 261 MO_Moment_im_Leerlauf 0 "kein_Leergas" 1 "Leergas" ;
VAL_ 261 MO_Interlock 0 "Interlockschalter nicht bet�tigt" 1 "Interlockschalter bet�tigt" ;
VAL_ 261 MO_BLS 0 "kein Bremsen" 1 "Bremse bet�tigt" ;
VAL_ 261 MO_Fahrer_bremst 0 "kein Bremsen" 1 "Bremse bet�tigt" ;
VAL_ 261 MO_Konsistenz_Bremsped 0 "Bremspedalinformation_plausibel" 1 "Bremspedalinformation_unplausibel" ;
VAL_ 261 MO_Kuppl_schalter 0 "Schalter sagt nicht bet�tigt (Eingekuppelt)" 1 "Schalter sagt bet�tigt (Ausgekuppelt)" ;
VAL_ 261 MO_Timeout_ESP 0 "Empfang i.O." 1 "Timeout" ;
VAL_ 261 MO_Motor_laeuft 0 "Motor l�uft nicht" 1 "Motor l�uft autark und stabil und darf mechanisch belastet werden" ;
VAL_ 261 MO_Solldrehz_Leerlauf 255 "Fehler" ;
VAL_ 261 MO_Fahrpedalrohwert_01 255 "Fehler" ;
VAL_ 261 MO_erste_Ungenauschwelle 0 "genau" 1 "Momente ungenauer >8%" ;
VAL_ 261 MO_QBit_Stressfaktor 0 "gueltiger_Wert" 1 "Ersatz_Init_oder_Fehlerwert" ;
VAL_ 263 MO_Istgang 0 "kein_Gang_eingelegt" 1 "Gang_1" 2 "Gang_2" 3 "Gang_3" 4 "Gang_4" 5 "Gang_5" 6 "Gang_6" ;
VAL_ 263 MO_Sollgang 0 "keine_Empfehlung" 1 "Gang_1" 2 "Gang_2" 3 "Gang_3" 4 "Gang_4" 5 "Gang_5" 6 "Gang_6" ;
VAL_ 263 MO_Oeldruck 255 "Fehler" ;
VAL_ 263 MO_Anzeigedrehz 4095 "Fehler" ;
VAL_ 263 MO_Schaltempf_verfbar 0 "nicht_verfuegbar" 1 "verfuegbar" ;
VAL_ 263 MO_Ladedruck 511 "Fehler" ;
VAL_ 263 MO_KVS_Ueberlauf 0 "kein Ueberlauf" 1 "Kraftstoffverbrauchsignale mindestens 1x �bergelaufen" ;
VAL_ 782 MO_EKlKomLeiRed 0 "keine_Leistungsbegr" 1 "Leistungsbegr_75" 2 "Leistungsbegr_50" 3 "Leistungsbegr_25" ;
VAL_ 782 MO_Freig_Reku 0 "Rekuperations-Modus aus" 1 "Empfehlung Spannungsanhebung" 2 "Empfehlung Spannungsabsenkung" 3 "Rekuperationsmodus aktiv, Spannungsvariation nicht notwendig" ;
VAL_ 782 MO_Klima_Eingr 0 "kein Eingriff" 1 "Klimakompressor ausschalten" 2 "Klimakompressor Leistungsreduzierung" 3 "Klimakompressor aufgrund der Heissleuchtenvorwarnung ausschalten" ;
VAL_ 782 MO_Status_Normalbetrieb_02 0 "kein Normalbetrieb" 1 "Normalbetrieb erreicht" ;
VAL_ 782 MO_Prio_MIN_Wunschdrehzahl 0 "Wunsch" 1 "Zwang" ;
VAL_ 782 MO_Freig_Anlass 0 "Start nicht zul�ssig" 1 "Startfreigabe" ;
VAL_ 782 MO_Aussp_Anlass 0 "Motor l�uft nicht stabil" 1 "Anlasser ausspuren (Motor l�uft stabil)" ;
VAL_ 782 MO_MAX_Wunschdrehzahl 511 "Fehler" ;
VAL_ 782 MO_Prio_MAX_Wunschdrehzahl 0 "Wunsch" 1 "Zwang" ;
VAL_ 782 MO_Luftpfad_aktiv 0 "kein Eingriff oder nur Eingriff �ber Z�ndpfad" 1 "Eingriff �ber Luftpfad" ;
VAL_ 782 MO_v_Begrenz_Aktiv 0 "inaktiv" 1 "aktiv" ;
VAL_ 782 MO_v_Begrenz_Aktivierbar 0 "V-Begrenzung nicht m�glich" 1 "V-Begrenzung m�glich" ;
VAL_ 782 MO_Verbot_EKP 0 "Ansteuerung zugelassen" 1 "Ansteuerung verboten" ;
VAL_ 782 MO_Anf_Pruefimpuls 0 "keine Anforderung" 1 "Anforderung" ;
VAL_ 782 MO_Anf_KL75 0 "Anforderung KL75 ausschalten" 1 "Anforderung KL75 einschalten" ;
VAL_ 782 MO_Charisma_FahrPr 0 "nicht_belegt" 1 "Programm_1" 2 "Programm_2" 3 "Programm_3" 4 "Programm_4" 5 "Programm_5" 6 "Programm_6" 7 "Programm_7" ;
VAL_ 782 MO_Charisma_Status 0 "Init" 1 "verfuegbar" 2 "nicht_verfuegbar" 3 "asynchron_durch_Fahrerwunsch" ;
VAL_ 782 MO_Charisma_Umschaltung 0 "Idle" 1 "Erkennung_Umschaltaufforderung" 2 "Steuerbotschaft_nicht_definiert" 3 "Umschaltung_verzoegert" ;
VAL_ 782 MO_Handshake_STH 0 "keine EKP-Ansteuerung durch STH-Anforderung" 1 "EKP-Ansteuerung durch STH-Anforderung" ;
VAL_ 782 MO_MIN_Wunschdrehzahl 255 "Fehler" ;
VAL_ 1088 MO_Kuehlerluefter_MUX 0 "Kuehlerluefter_1" 1 "Kuehlerluefter_2" ;
VAL_ 1088 MO_Kuehlerluefter_1 126 "Init" 127 "Fehler" ;
VAL_ 1088 MO_Kuehlerluefter_2 126 "Init" 127 "Fehler" ;
VAL_ 1088 MO_HYB_Status_HV_Ladung 0 "HV-Ladung_nicht_notwendig" 1 "HV-Ladung_notwendig_Freigaben_erforderlich" 2 "HV-Ladung laeuf" 3 "HV-Ladung_erfolgreich_Motorstart_moeglich" 4 "HV_Ladung_abgebrochen" ;
VAL_ 1088 WIV_Anzeige_aktiv 0 "Anzeige aus" 1 "WIV Anzeige aktiv" ;
VAL_ 1088 WIV_Oelmin_Warn 0 "in_Ordnung" 1 "Warnung" ;
VAL_ 1088 WIV_Sensorfehler 0 "in_Ordnung" 1 "Sensor_defekt" ;
VAL_ 1088 WIV_Schieflage 0 "Fahrzeug_gerade" 1 "Fahrzeug_in_Schieflage" ;
VAL_ 1088 MO_Zustand_HWP 0 "HWP_nicht_schaltbar" 1 "HWP_foerdert_nicht" 2 "HWP_foerdert" 3 "reserviert" ;
VAL_ 1088 WIV_Oelsystem_aktiv 0 "Anzeige_aus" 1 "Anzeige_aktiv" ;
VAL_ 1088 WIV_nicht_betriebswarm 0 "Motor_warm" 1 "Motor_nicht_betriebswarm" ;
VAL_ 1088 WIV_Ueberfuell_Warn 0 "in_Ordnung" 1 "Ueberfuellwarnung" ;
VAL_ 1088 WIV_laufender_Motor 0 "Messung_moeglich" 1 "Messung_nicht_moeglich" ;
VAL_ 1088 MO_HYB_Text_1 0 "kein_Text" 1 "Text_anzeigen" ;
VAL_ 1088 MO_HYB_Text_2 0 "kein_Text" 1 "Text_anzeigen" ;
VAL_ 1088 MO_HYB_Text_3 0 "kein_Text" 1 "Text_anzeigen" ;
VAL_ 1088 MO_Text_Motorstart 0 "keine_Anzeige" 1 "Motor_im_Stoppbetrieb" 2 "StartStopp_sicherheitsbedingt_deaktiviert" 3 "System_fordert_Wiederstart" 5 "Motorlauf_noetig" 9 "Unerwuenschter_Motorstillstand" 12 "Motor_startet" 13 "Kupplung_betaetigen" 14 "Waehlhebel_in_PN_Position" 15 "Bremse_treten" ;
VAL_ 1088 MO_HYB_Text_5 0 "kein_Text" 1 "Text_anzeigen" ;
VAL_ 1088 MO_HYB_Text_6 0 "kein_Text" 1 "Text_anzeigen" ;
VAL_ 1088 MO_HYB_Text_7 0 "kein_Text" 1 "Text_anzeigen" ;
VAL_ 1088 WIV_Oeldyn_avl 0 "Oeldyn_nicht_vorhanden" 1 "Oeldyn_vorhanden" ;
VAL_ 1088 MO_Systemlampe 0 "Lampe aus" 1 "Lampe ein" ;
VAL_ 1088 MO_OBD2_Lampe 0 "Lampe aus" 1 "Lampe ein" ;
VAL_ 1088 MO_Heissleuchte 0 "Lampe aus" 1 "Lampe ein" ;
VAL_ 1088 MO_Partikel_Lampe 0 "Lampe aus" 1 "Lampe ein" ;
VAL_ 1088 WIV_Oelstand_nicht_vorhanden 0 "�lstand vorhanden" 1 "�lstand nicht vorhanden" ;
VAL_ 1088 WIV_nachfuellanzeige_ein 0 "keine_Nachfuellanzeige" 1 "Nachfuellanzeige" ;
VAL_ 1088 WIV_Ueberfuell_deaktiv 0 "Ueberfuellwarnung_am_Kombi_aktiv" 1 "Ueberfuellwarnung_am_Kombi_deaktiv" ;
VAL_ 1088 WIV_Unterfuell_Warn 0 "in_Ordnung" 1 "Unterfuellwarnung" ;
VAL_ 1088 MO_Tankdeckel_Lampe 0 "Lampe aus" 1 "Lampe ein" ;
VAL_ 1088 MO_Text_Tankdeckelwarn 0 "kein Text" 1 "Anzeige Text Tankdeckelwarnung im Kombi" ;
VAL_ 1088 WIV_Enable_Oeldr_Motor 0 "Oeldruckauswertung_im_Kombi" 1 "Oeldruckauswertung_im_MSG" ;
VAL_ 1088 WIV_Oeldr_Warn_Motor 0 "keine_Warnung" 1 "niedrige_Oeldruckstufe_nicht_erreicht " ;
VAL_ 1088 MO_Avus_Motorschutz 0 "keine Warnung" 1 "Drehzahlwarnung Stufe 1" 2 "Drehzahlwarnung Stufe 2" 3 "Drehzahlwarnung Stufe 3" ;
VAL_ 1088 MO_HYB_Fahrbereitschaft 0 "keine_Fahrbereitschaft" 1 "Fahrbereitschaft" ;
VAL_ 1600 MO_QBit_Ansaugluft_Temp 0 "gueltiger_Wert" 1 "Ersatz_Init_oder_Fehlerwert" ;
VAL_ 1600 MO_QBit_Oel_Temp 0 "gueltiger_Wert" 1 "Ersatz_Init_oder_Fehlerwert" ;
VAL_ 1600 MO_QBit_Kuehlmittel_Temp 0 "gueltiger_Wert" 1 "Ersatz_Init_oder_Fehlerwert" ;
VAL_ 1600 MO_Stellgliedtest_Soundaktuator 0 "kein_Stellgliedtest" 1 "Anforderung_des_Stellgliedtest" ;
VAL_ 1600 MO_HYB_Fehler_HV_Netz 0 "i_O" 1 "kein_generatorischer_Betrieb_moeglich" ;
VAL_ 1600 MO_aktives_Getriebeheizen 0 "kein_Ventil_ansteuern" 1 "Ventil_muss_angesteuert_werden" ;
VAL_ 1600 MO_Absperrventil_oeffnen 0 "nicht_verfuegbar" 1 "Ansteuerung_Ventil_zulaessig" 2 "Ventil_oeffnen_oder_geoeffnet" 3 "Ventil_schliessen_oder_geschlossen" ;
VAL_ 1600 MO_Ansaugluft_Temp 254 "Init" 255 "Fehler" ;
VAL_ 1600 MO_Oel_Temp 253 "nicht_verbaut" 254 "Init" 255 "Fehler" ;
VAL_ 1600 MO_Kuehlmittel_Temp 254 "Init" 255 "Fehler" ;
VAL_ 1600 MO_Hoeheninfo 255 "Fehler" ;
VAL_ 1600 MO_Kennfeldk 0 "keine Kennfeldk�hlung vorhanden" 1 "Kennfeldk�hlung vorhanden" ;
VAL_ 1600 MO_Versionsinfo 0 "zum Projektbeginn 'aufger�umter CAN' " 1 "Motor_03_mit_10ms" 16 "MQB_mit_neuer_Momentenschnittstelle" ;
VAL_ 1600 MO_Getriebe_kuehlen 0 "nicht_kuehlen" 1 "kuehlen" ;
VAL_ 1600 MO_Heizungspumpenansteuerung 15 "nicht_verbaut" ;
VAL_ 1600 MO_SpannungsAnf 0 "keine_Anforderung" 1 "Anforderung" ;
VAL_ 1607 MO_ITM_Kuehlmittel_Temp 0 "nicht_verbaut" 2 "Fehler" ;
VAL_ 1607 MO_E85_Sensor 13 "nicht_verbaut" 15 "Fehler" ;
VAL_ 1607 SCR_Anz_Motorstarts 15 "keine Einschr�nkung (Anzeige Reichweite)" ;
VAL_ 1607 SCR_Reichweite 32767 "Init" ;
VAL_ 1607 SCR_Warnstufe_1 0 "nicht aktiv" 1 "Warnstufe 1 aktiv" ;
VAL_ 1607 SCR_Warnstufe_2 0 "nicht aktiv" 1 "Warnstufe 2 aktiv" ;
VAL_ 1607 SCR_Text 0 "kein Text" 1 "Warntext 1" 2 "Warntext 2" 3 "Hinweistext (nur AUDI)" 4 "Reserve" 5 "Warntext 'SCR-Systemfehler Stufe 1'" 6 "Warntext 'SCR-Systemfehler Stufe 2'" ;
VAL_ 1607 SCR_Akustik 0 "keine Akustik" 1 "Akustik 1" 2 "Akustik 2" 3 "Akustik_bei_Hinweis_(VW)" ;
VAL_ 1607 MO_Kraftstofffilter_Wasser 0 "keine_Anzeige" 1 "Abscheidevolumen_erschoepft" ;
VAL_ 1607 SCR_Systemfehler 0 "Warnung_nicht_aktiv" 1 "Warnung_aktiv" ;
VAL_ 1607 SCR_Inducement_Strategie 0 "Restart_Strategie" 1 "Reduced_Drivability_Strategie" ;
VAL_ 1607 MO_CO2_Faktor 0 "nicht_verbaut" 4095 "Fehler" ;
VAL_ 1607 MO_MKB_MUX 0 "MKB_01" 1 "MKB_02" 2 "MKB_03" 3 "MKB_04" ;
VAL_ 1607 MO_MKB_01 0 "Minus" 1 "A" 2 "B" 3 "C" 4 "D" 5 "E" 6 "F" 7 "G" 8 "H" 9 "I" 10 "J" 11 "K" 12 "L" 13 "M" 14 "N" 15 "O" 16 "P" 17 "Q" 18 "R" 19 "S" 20 "T" 21 "U" 22 "V" 23 "W" 24 "X" 25 "Y" 26 "Z" 27 "Leerzeichen" 28 "Leerzeichen" 29 "Leerzeichen" 30 "Leerzeichen" 31 "Unterstrich" ;
VAL_ 1607 MO_MKB_02 0 "Minus" 1 "A" 2 "B" 3 "C" 4 "D" 5 "E" 6 "F" 7 "G" 8 "H" 9 "I" 10 "J" 11 "K" 12 "L" 13 "M" 14 "N" 15 "O" 16 "P" 17 "Q" 18 "R" 19 "S" 20 "T" 21 "U" 22 "V" 23 "W" 24 "X" 25 "Y" 26 "Z" 27 "Leerzeichen" 28 "Leerzeichen" 29 "Leerzeichen" 30 "Leerzeichen" 31 "Unterstrich" ;
VAL_ 1607 MO_MKB_03 0 "Minus" 1 "A" 2 "B" 3 "C" 4 "D" 5 "E" 6 "F" 7 "G" 8 "H" 9 "I" 10 "J" 11 "K" 12 "L" 13 "M" 14 "N" 15 "O" 16 "P" 17 "Q" 18 "R" 19 "S" 20 "T" 21 "U" 22 "V" 23 "W" 24 "X" 25 "Y" 26 "Z" 27 "Leerzeichen" 28 "Leerzeichen" 29 "Leerzeichen" 30 "Leerzeichen" 31 "Unterstrich" ;
VAL_ 1607 MO_MKB_04 0 "Minus" 1 "A" 2 "B" 3 "C" 4 "D" 5 "E" 6 "F" 7 "G" 8 "H" 9 "I" 10 "J" 11 "K" 12 "L" 13 "M" 14 "N" 15 "O" 16 "P" 17 "Q" 18 "R" 19 "S" 20 "T" 21 "U" 22 "V" 23 "W" 24 "X" 25 "Y" 26 "Z" 27 "Leerzeichen" 28 "Leerzeichen" 29 "Leerzeichen" 30 "Leerzeichen" 31 "Unterstrich" ;
VAL_ 276 MO_Sig_Fahrpedalgradient 0 "Fahrpedalgradient positiv" 1 "Fahrpedalgradient negativ" ;
VAL_ 276 MO_BKV_Unterdruckwarnung 0 "Unterdruckhaushalt_iO" 1 "Unterdruckhaushalt_niO" ;
VAL_ 276 MO_Zylinderabschaltung 0 "Vollmotorbetrieb_VMB" 1 "Uebergang_HMB_in_VMB" 2 "Uebergang_VMB_in_HMB" 3 "Halbmotorbetrieb_HMB" ;
VAL_ 276 MO_Fahrpedalgradient 255 "Fehler" ;
VAL_ 276 MO_Schubabschaltung 0 "keine_Schubabschaltung" 1 "Schubabschaltung_aktiv" ;
VAL_ 276 MO_rel_Saugrohrdruck 0 "Init_Ueberdruck" 63 "Fehler" ;
VAL_ 276 MO_rel_Saugrohrdruck_gem_err 0 "errechnet" 1 "gemessen" ;
VAL_ 276 MO_BKV_Unterdruck 255 "Fehler" ;
VAL_ 1648 MO_Anzahl_Abgesch_Zyl 0 "Vollmotorbetrieb" 1 "1_Zylinder_abgeschaltet" 2 "2_Zylinder_abgeschaltet" 3 "3_Zylinder_abgeschaltet" 4 "4_Zylinder_abgeschaltet" 5 "5_Zylinder_abgeschaltet" 6 "6_Zylinder_abgeschaltet" 7 "8_Zylinder_abgeschaltet" ;
VAL_ 1648 MO_Zylabsch_Texte 0 "keine_Texte" 1 "Zylinderabschaltung_deaktivieren" 2 "Zylinderabschaltung_aktivieren" 3 "Zylinderabschaltung_unruhig" ;
VAL_ 1648 MO_E85_BS_Texte 0 "kein Text" 1 "FlexFuel Warm_Up_ Lampe" 2 "FlexFuel Warnung 3.Stufe " 3 "FlexFuel Warnung 1.Stufe " 4 "FlexFuel Warnung 2.Stufe " 5 "FlexFuel Warnung 4.Stufe " ;
VAL_ 1648 MO_Drehzahl_Warnung 0 "keinen_Warnhinweis_anzeigen" 1 "Warnhinweis_anzeigen" ;
VAL_ 1010 MO_SCR_Tankheizung 0 "Heizung_aus" 1 "Heizung_ein" ;
VAL_ 1010 MO_SCR_Dosierpumpe_Zustand 0 "frei" 1 "Drehzahlregelung" 2 "Druckregelung_langsam" 3 "Druckregelung_schnell" 4 "Pumpe_Stop" 5 "Rueckwaertsbetrieb" 6 "verzoegerter_Rueckwaertsbetrieb" 7 "Pumpe_heizen" ;
VAL_ 1010 MO_SCR_Leitungsheizung 0 "Heizung_aus" 1 "Heizung_ein" ;
VAL_ 1010 MO_SCR_Dosierpumpe_Wartezeit 125 "nicht_verbaut" 127 "Fehler" ;
VAL_ 1010 MO_SCR_Transferpumpe 0 "Pumpe_aus" 1 "Pumpe_ein" ;
VAL_ 1601 MO_Faktor_Momente 0 "nicht belegt" 1 "Faktor: x 0,5Nm" 2 "Faktor: x 1,0Nm" 3 "Faktor: x 2,0Nm" ;
VAL_ 1601 MO_Hybridfahrzeug 0 "kein_Hybridfahrzeug" 1 "Mild_Hybrid" 2 "Full_Hybrid" ;
VAL_ 1601 MO_Getriebe_Code 2 "DL501" 4 "VL381" 10 "AL651" 11 "AL551, AL951, AL1000-8A" 12 "PDK_PAG" 13 "AL551_Hybrid" 15 "Handschalter (konventionell)" 16 "AQ250" 17 "AQ450" 18 "DQ200" 19 "DQ250" 20 "DQ500" 21 "SQ100" 22 "SQ200" ;
VAL_ 1601 MO_StartStopp_Codiert 0 "Start_Stopp_nicht_verbaut" 1 "Start_Stopp_verbaut" ;
VAL_ 1601 MO_Kraftstoffart 0 "Diesel" 1 "Benzin" 2 "CNG" 3 "Erdgas" 4 "Wasserstoff" ;
VAL_ 1601 MO_Ansaugsystem 0 "Turbo" 1 "Sauger" ;
VAL_ 1601 MO_Einspritzart 0 "MPI" 1 " FSI / TDI" ;
VAL_ 969 MOS_KD_Fehler 0 "kein_KD_Fehler" 1 "KD_Fehler" ;
VAL_ 1696 NV_aktiv 0 "NV nicht aktiv" 1 "NV aktiv" ;
VAL_ 1696 NV_Texte 0 "kein_Text" 1 "Abblendlicht_einschalten" 2 "Fussgaengermarkierung_nicht_verfuegbar" 3 "zur_Zeit_nicht_verfuegbar" 4 "Systemfehler" ;
VAL_ 1696 NV_Gong 0 "kein_Gong" 1 "Gong_leise" 2 "Gong_mittel" 3 "Gong_laut" ;
VAL_ 1696 NV_Symbol 0 "kein_Symbol_anzeigen" 1 "Symbol_fuer_erkanntes_Objekt_anzeigen" ;
VAL_ 1696 NV_Hinweise 0 "keine_Anzeige" 1 "Disclaimer" 2 "Fussgaenger_Markierung_nicht_verfuegbar" 3 "Nachtsichtsystem_wird_initialisiert" ;
VAL_ 1696 NV_Piktogramm_aktiv 0 "keine_Anzeigenprioritaet" 1 "Anzeigenprioritaet" ;
VAL_ 1696 NV_Akustik_deaktiviert_Icon 0 "aus" 1 "ein" ;
VAL_ 1696 NV_FGM_deaktiviert_Icon 0 "aus" 1 "ein" ;
VAL_ 1696 NV_KD_Fehler 0 "kein_KD_Fehler" 1 "KD_Fehler" ;
VAL_ 1753 NMH_EPB_Start_1 1 "Zustand Start (<--Sleep)" ;
VAL_ 1753 NMH_EPB_Start_2 1 "Zustand Start (<--Prepare to Sleep)" ;
VAL_ 1753 NMH_EPB_Normal_Mode_1 1 "Zustand Normal Mode (<-- Start)" ;
VAL_ 1753 NMH_EPB_Normal_Mode_2 1 "Zustand Normal Mode (<-- Ready to Sleep)" ;
VAL_ 1753 NMH_EPB_Per_WakeUp 0 "Wenn Funktions-Wakeup" 1 "CAN-Wakeup" 2 "Periphrie-Wakeup Ursache nicht bekannt" 3 "Klemme 15 HW (falls vorhanden)" 4 "t.b.d." 5 "Schalter_EPB" ;
VAL_ 1753 NMH_EPB_Fkt_WakeUp 0 "Wenn Peripherie-Wakeup" ;
VAL_ 1753 NMH_EPB_NM_aktiv_Klemme_15 1 "Klemme 15 EIN" ;
VAL_ 1753 NMH_EPB_NM_aktiv_Diagnose 1 "Diagnose bei Kl 15 aus" ;
VAL_ 1753 NMH_EPB_NM_aktiv_Start 1 "Zustand 'START' (NM-high)" ;
VAL_ 1753 NMH_EPB_NM_aktiv_Schalter 1 "Schalter aktiv" ;
VAL_ 1753 NMH_EPB_NM_aktiv_Bedarf_Anzeige 1 "Kombi-Anzeige EPB" ;
VAL_ 1753 NMH_EPB_NM_aktiv_v_groesser_Null 1 "v > 0" ;
VAL_ 1753 NMH_EPB_kein_NL 1 "kein lokaler Nachlauf" ;
VAL_ 1753 NMH_EPB_NL_Temp_Modell 1 "Temperaturmodell aktiv" ;
VAL_ 1753 NMH_EPB_NL_AutoAdjust 0 "AutoAdjust_nicht_aktiv" 1 "AutoAdjust_aktiv" ;
VAL_ 1753 NM_EPB_Signalfehler 1 "Aktiver_Signalfehler_eingetragen" ;
VAL_ 1753 NMH_EPB_TimeOut_Fehler 1 "Aktiver Timeout Fehlerspeichereintrag  " ;
VAL_ 1753 NMH_EPB_CAN_Diag_deaktiv 1 "CAN-Diagnose deaktiv" ;
VAL_ 1753 NMH_EPB_KompSchutz 1 "KS aktiv" ;
VAL_ 1753 NMH_EPB_Mute_Mode 1 "MuteMode aktiv" ;
VAL_ 1753 NMH_EPB_Transport_Mode 1 "Transportmodus aktiv" ;
VAL_ 1753 NMH_EPB_Abschaltstufe_aktiv 1 "Abschaltstufe aktiv" ;
VAL_ 1753 NMH_EPB_Eindraht_Fehler 1 "Eindrahtbetrieb erkannt" ;
VAL_ 1753 NMH_EPB_Lokalaktiv 0 "war nicht Lokalaktiv" 1 "war Lokalaktiv" ;
VAL_ 1753 NMH_EPB_Subsystemaktiv 0 "Subsystem war nicht lokalaktiv" 1 "war Lokalaktiv" ;
VAL_ 1728 NMH_GW_Start_1 1 "Zustand Start (<--Sleep)" ;
VAL_ 1728 NMH_GW_Start_2 1 "Zustand Start (<--Prepare to Sleep)" ;
VAL_ 1728 NMH_GW_Normal_Mode_1 1 "Zustand Normal Mode (<-- Start)" ;
VAL_ 1728 NMH_GW_Normal_Mode_2 1 "Zustand Normal Mode (<-- Ready to Sleep)" ;
VAL_ 1728 NMH_GW_Per_WakeUp 0 "Wenn_FunktionsWakeup" 1 "CAN_Wakeup__Weckendes_CAN_Segment_siehe_NMH_GW_WakeUp_CAN_Bus" 2 "P_WakeUp_Ursache_unbekannt" 3 "Klemme_15HW__falls_vorhanden" 4 "MOST_Wakeup" 5 "LIN_Wakeup" 6 "KL30_Reset" ;
VAL_ 1728 NMH_GW_Fkt_WakeUp 0 "Wenn_Peripherie_Wakeup" 1 "Funktionswakeup_EM" 2 "Car_Wakeup_empfangen" 3 "VNSM_VehicleNetworkStateManager" 4 "Alarm_RTC__Wecken_weil_Weckzeit_abgelaufen" 5 "Wecken_durch_Diagnose" ;
VAL_ 1728 NMH_GW_NM_aktiv_Klemme_15 1 "Klemme 15 EIN" ;
VAL_ 1728 NMH_GW_NM_aktiv_Diagnose 1 "Diagnose bei Kl 15 aus" ;
VAL_ 1728 NMH_GW_NM_aktiv_Start 1 "Zustand 'START' (NM-high)" ;
VAL_ 1728 NMH_GW_NM_aktiv_BDM 1 "BDM-Kommunikation" ;
VAL_ 1728 NMH_GW_NM_aktiv_Warnblinken 1 "Warnblinken aktiv" ;
VAL_ 1728 NMH_GW_NM_aktiv_ESP 1 "ESP aktiv (Wakeup/Sleep-Konzept)" ;
VAL_ 1728 NMH_GW_Abschaltstufe_3 1 "BEM aufgrund Abschaltstufe 3 aktiv" ;
VAL_ 1728 NMH_GW_SG_Fehlerdauer 1 "BEM aufgrund Steuergeraetefehlerdauer aktiv" ;
VAL_ 1728 NMH_GW_STH_Wakeup 1 "BEM aktiv aufgrund Standheizungswakeup" ;
VAL_ 1728 NMH_GW_NL_Diagnose 0 "keine_Diagnose_aktiv" 1 "Diagnose_war_lokal_aktiv" ;
VAL_ 1728 NM_GW_Signalfehler 1 "Aktiver_Signalfehler_eingetragen" ;
VAL_ 1728 NMH_GW_TimeOut_Fehler 1 "Aktiver Timeout Fehlerspeichereintrag  " ;
VAL_ 1728 NMH_GW_CAN_Diag_deaktiv 1 "CAN Bus bezogene Eigendiagnose deaktiv" ;
VAL_ 1728 NMH_GW_KompSchutz 1 "KS aktiv" ;
VAL_ 1728 NMH_GW_Mute_Mode 1 "MuteMode aktiv" ;
VAL_ 1728 NMH_GW_Transport_Mode 1 "Transportmodus aktiv" ;
VAL_ 1728 NMH_GW_Abschaltstufe_aktiv 1 "Abschaltstufe aktiv" ;
VAL_ 1728 NMH_GW_Eindraht_Fehler 1 "Eindrahtbetrieb erkannt" ;
VAL_ 1728 NMH_GW_ACAN 1 "ACAN aktiv (Wakeup/Sleep-Konzept)" ;
VAL_ 1728 NMH_GW_KombiCAN 1 "KombiCAN aktiv (Wakeup/Sleep-Konzept)" ;
VAL_ 1728 NMH_GW_KomfortCAN 1 "KomfortCAN aktiv (Wakeup/Sleep-Konzept)" ;
VAL_ 1728 NMH_GW_Infotainment 1 "Infotainment aktiv (CAN oder MOST), Wakeup/Sleep-Konzept" ;
VAL_ 1728 NMH_GW_Fahrwerk 1 "BUS_Fahrwerk_aktiv (Wakeup/Sleep-Konzept)" ;
VAL_ 1728 NMH_GW_WakeUp_CAN_Bus 0 "Nicht zutreffend (kein CAN-Wakeup bzw. CarWakeup)" 1 "Antriebs-CAN" 2 "Kombi-CAN" 3 "Komfort-CAN" 4 "Infotainment-CAN (wenn verfuegbar)" 5 "Fahrwerks-CAN" 6 "Diagnose-CAN" ;
VAL_ 1730 NMH_GE_Start_1 1 "Zustand Start (<--Sleep)" ;
VAL_ 1730 NMH_GE_Start_2 1 "Zustand Start (<--Prepare to Sleep)" ;
VAL_ 1730 NMH_GE_Normal_Mode_1 1 "Zustand Normal Mode (<-- Start)" ;
VAL_ 1730 NMH_GE_Normal_Mode_2 1 "Zustand Normal Mode (<-- Ready to Sleep)" ;
VAL_ 1730 NMH_GE_Per_WakeUp 0 "wenn Funktionswakeup" 1 "CAN" 2 "P-Wakeup, Ursache nicht bekannt" 3 "KL 15 HW (falls vorhanden)" ;
VAL_ 1730 NMH_GE_Fkt_WakeUp 0 "wenn Peripheriewakeup" 1 "Ende_N_Haltephase" ;
VAL_ 1730 NMH_GE_NM_aktiv_Klemme_15 1 "Klemme 15 ein" ;
VAL_ 1730 NMH_GE_NM_aktiv_Diagnose 1 "Diagnose bei Kl 15 aus" ;
VAL_ 1730 NMH_GE_NM_aktiv_Start 1 "Zustand 'START' (NM-high)" ;
VAL_ 1730 NMH_GE_N_Haltephase 0 "keine_N_Haltephase" 1 "N_Haltephase_aktiv" ;
VAL_ 1730 NMH_GE_kein_NL 1 "kein lokaler Nachlauf" ;
VAL_ 1730 NMH_GE_NL_Daten_EEPROM 1 "EEPROM Datenspeicherung" ;
VAL_ 1730 NM_GE_Signalfehler 1 "Aktiver_Signalfehler_eingetragen" ;
VAL_ 1730 NMH_GE_TimeOut_Fehler 1 "Aktiver Timeout Fehlerspeichereintrag  " ;
VAL_ 1730 NMH_GE_CAN_Diag_deaktiv 1 "CAN-Diagnose deaktiv" ;
VAL_ 1730 NMH_GE_KompSchutz 1 "KS aktiv" ;
VAL_ 1730 NMH_GE_Mute_Mode 1 "MuteMode aktiv" ;
VAL_ 1730 NMH_GE_Transport_Mode 1 "Transportmodus aktiv" ;
VAL_ 1730 NMH_GE_Abschaltstufe_aktiv 1 "Abschaltstufe aktiv" ;
VAL_ 1730 NMH_GE_Eindraht_Fehler 1 "Eindrahtbetrieb erkannt" ;
VAL_ 1730 NMH_GE_Lokalaktiv 0 "war nicht Lokalaktiv" 1 "war Lokalaktiv" ;
VAL_ 1730 NMH_GE_Subsystemaktiv 0 "Subsystem war nicht lokalaktiv" 1 "war Lokalaktiv" ;
VAL_ 1730 NMH_GSG_Subbusaktiv 0 "Subbus inaktiv" 1 "Subbus aktiv" ;
VAL_ 1729 NMH_MO_Start_1 1 "Zustand Start (<--Sleep)" ;
VAL_ 1729 NMH_MO_Start_2 1 "Zustand Start (<--Prepare to Sleep)" ;
VAL_ 1729 NMH_MO_Normal_Mode_1 1 "Zustand Normal Mode (<-- Start)" ;
VAL_ 1729 NMH_MO_Normal_Mode_2 1 "Zustand Normal Mode (<-- Ready to Sleep)" ;
VAL_ 1729 NMH_MO_Per_WakeUp 0 "Wenn Funktions-Wakeup" 1 "CAN-Wakeup" 2 "Peripherie-Wakeup Ursache nicht bekannt" 3 "Klemme 15 HW (falls vorhanden)" 4 "analog (Standheizung/Tuerkontakt)(nur MED9)" ;
VAL_ 1729 NMH_MO_Fkt_WakeUp 0 "Wenn_Peripherie_Wakeup" ;
VAL_ 1729 NMH_MO_NM_aktiv_Klemme_15 1 "Klemme 15 EIN" ;
VAL_ 1729 NMH_MO_NM_aktiv_Diagnose 1 "Diagnose bei Kl 15 aus " ;
VAL_ 1729 NMH_MO_NM_aktiv_Start 1 "Zustand 'START' (NM-high)" ;
VAL_ 1729 NMH_MO_NM_aktiv_EKP_Vorlauf 1 "EKP-Vorlauf" ;
VAL_ 1729 NMH_MO_NM_aktiv_STH_Betrieb 1 "STH-Betrieb" ;
VAL_ 1729 NMH_MO_NM_aktiv_HV_Abschaltung 0 "kein_Nachlauf" 1 "Abschaltung_aktiv" ;
VAL_ 1729 NMH_MO_kein_NL 1 "kein lokaler Nachlauf" ;
VAL_ 1729 NMH_MO_NL_Kuehlerluefter 1 "K�hlerl�fter Steuerung / Zusatzwasserpumpe aktiv" ;
VAL_ 1729 NMH_MO_NL_Diagnose 1 "Diagnosefunktionen aktiv" ;
VAL_ 1729 NMH_MO_NL_WFS 1 "WFS aktiv" ;
VAL_ 1729 NMH_MO_NL_EEPROM 1 "EEPROM Zugriffe RAM/ROM Tests" ;
VAL_ 1729 NMH_MO_NL_Sonstige 1 "Sonstige Nachl�ufe aktiv" ;
VAL_ 1729 NM_MO_Signalfehler 1 "Aktiver_Signalfehler_eingetragen" ;
VAL_ 1729 NMH_MO_TimeOut_Fehler 1 "Aktiver Timeout Fehlerspeichereintrag  " ;
VAL_ 1729 NMH_MO_CAN_Diag_deaktiv 1 "CAN-Diagnose deaktiv" ;
VAL_ 1729 NMH_MO_KompSchutz 1 "KS aktiv" ;
VAL_ 1729 NMH_MO_Mute_Mode 1 "MuteMode aktiv" ;
VAL_ 1729 NMH_MO_Transport_Mode 1 "Transportmodus aktiv" ;
VAL_ 1729 NMH_MO_Abschaltstufe_aktiv 1 "Abschaltstufe aktiv" ;
VAL_ 1729 NMH_MO_Eindraht_Fehler 1 "Eindrahtbetrieb erkannt" ;
VAL_ 1729 NMH_MO_Lokalaktiv 0 "war nicht Lokalaktiv" 1 "war Lokalaktiv" ;
VAL_ 1729 NMH_MO_Subsystemaktiv 0 "Subsystem war nicht lokalaktiv" 1 "war Lokalaktiv" ;
VAL_ 1736 NMH_MO_SL_Start_1 1 "Zustand Start (<--Sleep)" ;
VAL_ 1736 NMH_MO_SL_Start_2 1 "Zustand Start (<--Prepare to Sleep)" ;
VAL_ 1736 NMH_MO_SL_Normal_Mode_1 1 "Zustand Normal Mode (<-- Start)" ;
VAL_ 1736 NMH_MO_SL_Normal_Mode_2 1 "Zustand Normal Mode (<-- Ready to Sleep)" ;
VAL_ 1736 NMH_MO_SL_Per_WakeUp 0 "Wenn Funktions-Wakeup" 1 "CAN-Wakeup" 2 "Peripherie-Wakeup Ursache nicht bekannt" 3 "Klemme 15 HW (falls vorhanden)" 4 "analog (Standheizung/Tuerkontakt)(nur MED9)" ;
VAL_ 1736 NMH_MO_SL_Fkt_WakeUp 0 "Wenn Peripherie-Wakeup" ;
VAL_ 1736 NMH_MO_SL_TimeOut_Fehler 1 "Aktiver Timeout Fehlerspeichereintrag  " ;
VAL_ 1736 NMH_MO_SL_CAN_Diag_deaktiv 1 "CAN-Diagnose deaktiv" ;
VAL_ 1736 NMH_MO_SL_KompSchutz 1 "KS aktiv" ;
VAL_ 1736 NMH_MO_SL_Mute_Mode 1 "MuteMode aktiv" ;
VAL_ 1736 NMH_MO_SL_Transport_Mode 1 "Transportmodus aktiv" ;
VAL_ 1736 NMH_MO_SL_Abschaltstufe_aktiv 1 "Abschaltstufe aktiv" ;
VAL_ 1736 NMH_MO_SL_Busfehler 1 "Busfehler" ;
VAL_ 1736 NMH_MO_Sl_Lokalaktiv 0 "war_nicht_lokal_aktiv" 1 "war_lokal_aktiv" ;
VAL_ 1736 NMH_MO_SL_Subsystemaktiv 0 "Subsystem war nicht lokalaktiv" 1 "war Lokalaktiv" ;
VAL_ 1782 NMH_SCR_Start_1 1 "Zustand Start (<--Sleep)" ;
VAL_ 1782 NMH_SCR_Start_2 1 "Zustand Start (<--Prepare to Sleep)" ;
VAL_ 1782 NMH_SCR_Normal_Mode_1 1 "Zustand Normal Mode (<-- Start)" ;
VAL_ 1782 NMH_SCR_Normal_Mode_2 1 "Zustand Normal Mode (<-- Ready to Sleep)" ;
VAL_ 1782 NMH_SCR_Car_WakeUp 1 "Car Wake Up" ;
VAL_ 1782 NMH_SCR_Per_WakeUp 0 "Funktions-WakeUp" 1 "CAN" 2 "P_WakeUp_Ursache_unbekannt" 3 "KL_15_Hardware_falls_vorhanden" ;
VAL_ 1782 NMH_SCR_Fkt_WakeUp 0 "Peripheriewakeup" ;
VAL_ 1782 NMH_SCR_Klemme_15 1 "Klemme 15 ein" ;
VAL_ 1782 NMH_SCR_Diagnose 1 "Diagnose bei Kl 15 aus" ;
VAL_ 1782 NMH_SCR_MindestAktivZeit 1 "aktiv" ;
VAL_ 1782 NMH_SCR_NL_Datem_EEPROM 0 "kein_Nachlauf" 1 "EEPROM_schreibzugriff" ;
VAL_ 1782 NMH_SCR_Signalfehler 1 "Aktiver_Signalfehler_eingetragen" ;
VAL_ 1782 NMH_SCR_TimeOut_Fehler 1 "Aktiver Timeout Fehlerspeichereintrag" ;
VAL_ 1782 NMH_SCR_CAN_Diag_deaktiv 1 "CAN Bus bezogene Eigendiagnose deaktiviert" ;
VAL_ 1782 NMH_SCR_KompSchutz 1 "KS aktiv" ;
VAL_ 1782 NMH_SCR_Mute_Mode 1 "Mute Mode aktiv" ;
VAL_ 1782 NMH_SCR_Transport_Mode 1 "Transportmodus aktiv" ;
VAL_ 1782 NMH_SCR_Abschaltstufe_aktiv 1 "Funktionsabschaltung wegen Abschaltschaltstufe" ;
VAL_ 1782 NMH_SCR_Busfehler 1 "Busfehler" ;
VAL_ 1782 NMH_SCR_Lokalaktiv 0 "war_nicht_lokal_aktiv" 1 "war_lokal_aktiv" ;
VAL_ 1782 NMH_SCR_Subsystemaktiv 0 "Subsystem war nicht lokalaktiv" 1 "war Lokalaktiv" ;
VAL_ 913 OBD_Kaltstart_Denominator 0 "Denominator_nicht_hochzaehlen" 1 "Bedingungen_zum_Inkr_des_Kaltstart_Denom_erf" ;
VAL_ 913 OBD_Minimum_Trip 0 "kein_Min_Normed_Trip" 1 "Min_Normed_Trip" ;
VAL_ 913 OBD_Driving_Cycle 0 "kein Driving Cycle erkannt" 1 "DC erkannt" ;
VAL_ 913 OBD_Warm_Up_Cycle 0 "kein Warm Up Cycle erkannt" 1 "Warm Up Cycle erkannt" ;
VAL_ 913 OBD_Normed_Trip 0 "kein Normed Trip" 1 "Normed Trip erf�llt" ;
VAL_ 803 PCF_Objektstatus 0 "Kein_relevantes_Objekt_erkannt" 1 "Relevantes_Objekt_vorausfahrend" 2 "Relevantes_Objekt_stehend" 3 "Relevantes_Objekt_angehalten" 4 "Relevantes_Objekt_entgegenkommend" 5 "Ungueltig" 6 "Ungueltig" 7 "Ungueltig" ;
VAL_ 803 PCF_Fahrer_aktiv_erkannt 0 "Fahrer_nicht_aktiv" 1 "Fahrer_aktiv" ;
VAL_ 803 PCF_Time_to_collision 255 "Objektstatus=0x0__oder_berechneter_TTC_Wert_groesser_als_Maximalwert" ;
VAL_ 803 PCF_v_rel 0 " Objektstatus_0x0_oder _berechnete_v_rel_>= 0_(Objekt_entfernt_sich_oder_faehrt_vorraus_mit v_Obj_=_v_ego)" ;
VAL_ 803 PCF_dy_Kollisionsueberdeckung 0 "Keine_Ueberdeckung_oder_bei_Objektstatus_0x0" 30 "Ueberdeckung_groesser_Maximalwert" 31 "Objekueberdeckung_nicht_ermittelbar" ;
VAL_ 802 PCR_Sensorstatus 0 "Sensor_ok" 1 "Sensor_nok" ;
VAL_ 802 PCR_Obj_vx_rel 2047 "Fehler" ;
VAL_ 802 PCR_Obj_vy_rel 2047 "Fehler" ;
VAL_ 802 PCR_Obj_TTC 511 "Fehler" ;
VAL_ 802 PCR_Obj_Guete 127 "Fehler" ;
VAL_ 802 PCR_Crashwahrscheinlichkeit 127 "Fehler" ;
VAL_ 929 PSD_Pos_Segment_ID 0 "keine Position gegeben" 1 "Fehlerwert" ;
VAL_ 929 PSD_Pos_Standort 0 "mehrdeutiger_Standort" 1 "eindeutiger_Standort" ;
VAL_ 929 PSD_Pos_Laengsfehler 0 "keine Pr�diktion (off-road)" 1 "< 2m" 2 "< 5m" 3 "< 10m " 4 "< 20m" 5 "< 50m" 6 "> 50m " 7 "nicht erlaubt" ;
VAL_ 929 PSD_Segment_ID 0 "keine Segmentinformationen vorhanden" 1 "Fehlerwert" ;
VAL_ 929 PSD_Vorgaenger_Segment_ID 0 "keine Segmentinformation vorhanden" 1 "Fehlerwert" ;
VAL_ 929 PSD_Strassenklasse 0 "Rest_Feldweg_Schotterweg_Privatweg" 1 "Ortsstrasse" 2 "Bundes_Landstrasse" 3 "Autobahn" ;
VAL_ 929 PSD_Rampe 0 "Strasse_mit_Gegenverkehr" 1 "Auffahrt_Einbahnstr" 2 "Abfahrt_Einbahnstr" 3 "Einbahnstrasse" ;
VAL_ 929 PSD_Endkruemmung 255 "Gerade" ;
VAL_ 929 PSD_Endkruemmung_Vorz 0 "Kruemmung_positiv" 1 "Kruemmung_negativ" ;
VAL_ 929 PSD_Endsteigung 30 "gleich_oder_mehr_15_Prozent_Steigung" 31 "nicht_definiert" ;
VAL_ 929 PSD_Endsteigung_Vorz 0 "Gefaelle" 1 "Steigung" ;
VAL_ 929 PSD_ADAS_Qualitaet 0 "keine_ADAS_Qualitaet" 1 "ADAS_Qualitaet" ;
VAL_ 929 PSD_Fahrspuren 0 "Einbahnstrasse_in_falscher_Richtung" 1 "eine_Fahrspur" 2 "zwei_Fahrspuren" 3 "drei_Fahrspuren" ;
VAL_ 929 PSD_wahrscheinlichster_Pfad 0 "Pfad_mit_geringer_Wahrscheinlichkeit" 1 "wahrscheinlichster_Pfad" ;
VAL_ 930 PSD_Multiplex 0 "f�r System Informationen, die sich nur langsam �ndern" 1 "Informationen �ber ein Streckensegment" 2 "f�r Informationen �ber Geschwindigkeitsbegrenzungen und m�gliche Einschr�nkungen der Geschwindigkeitsbegrenzungen" 3 "Fahrzeugposition aus der Koppelortung" ;
VAL_ 930 PSD_Sys_Segment_ID 0 "keine Segmentinformationen vorhanden" 1 "nicht zulaessig" ;
VAL_ 930 PSD_Abz_Segment_ID 0 "keine Segmentinformationen vorhanden" 1 "nicht zulaessig" ;
VAL_ 930 PSD_Ges_Segment_ID 0 "keine Segmentinformationen vorhanden" 1 "nicht zulaessig" ;
VAL_ 930 PSD_Ort_Laenge_VZ 0 "Ost" 1 "West" ;
VAL_ 930 PSD_Ort_Laenge 33554431 "Keine GPS Position verfuegbar" ;
VAL_ 930 PSD_Ges_Geschwindigkeit 0 "Kein Geschwindigkeitsgebot" 1 "0 km/h < v_max <  5 km/h" 2 "5 km/h � v_max < 10km/h" 3 "10 km/h � v_max < 15 km/h" 4 "15 km/h � v_max < 20 km/h" 5 "20 km/h � v_max < 25 km/h" 6 "25 km/h � v_max < 30 km/h" 7 "30 km/h � v_max < 35 km/h" 8 "35 km/h � v_max < 40 km/h" 9 "40 km/h � v_max < 45 km/h" 10 "45 km/h � v_max < 50 km/h" 11 "50 km/h � v_max < 60 km/h" 12 "60 km/h � v_max < 70 km/h" 13 "70 km/h � v_max < 80 km/h" 14 "80 km/h � v_max < 90 km/h" 15 "90 km/h � v_max < 100 km/h" 16 "100 km/h � v_max < 110 km/h" 17 "110 km/h � v_max < 120 km/h" 18 " 120 km/h � v_max < 130 km/h" 19 "130 km/h � v_max < 140 km/h" 20 "140 km/h � v_max < 150 km/h" 21 "150 km/h � v_max < 160 km/h" 22 "160 km/h � v_max" 23 "Geschwindigkeitsgebot aufgehoben" 24 "..0x1F ung�ltig" ;
VAL_ 930 PSD_Ges_Geschwindigkeit_Typ 0 "Der Wert im Attribut Geschwindigkeitsbegrenzung entspricht der Geschwindigkeitsklasse von Navteq." 1 "Der Wert im Attribut Geschwindigkeitsbegrenzung entspricht einer explizit angegebenen Begrenzung der Geschwindigkeit." ;
VAL_ 930 PSD_Ges_Geschwindigkeit_Gespann 0 "alle Fahrzeuge" 1 "PKW mit Gespann" 2 "LKW, Busse, etc." ;
VAL_ 930 PSD_Abz_Vorgaenger_Segment_ID 0 "keine Segmentinformationen vorhanden" 1 "nicht zulaessig" ;
VAL_ 930 PSD_Sys_Geschwindigkeit_Einheit 0 "km/h" 1 "mph" ;
VAL_ 930 PSD_Ges_Geschwindigkeit_Witter 0 "Witterungsunabh�ngig" 1 "N�sse, Regen, Niederschlag" 2 "Gl�tte" 3 "Nebel" ;
VAL_ 930 PSD_Sys_Verkehrsrichtung 0 "Rechtsverkehr" 1 "Linksverkehr" ;
VAL_ 930 PSD_Ges_Geschwindigkeit_Tag_Anf 0 "kein Beginn definiert" 1 "Montag" 2 "Dienstag" 3 "Mittwoch" 4 "Donnerstag" 5 "Freitag" 6 "Samstag" 7 "Sonntag" ;
VAL_ 930 PSD_Abz_Geschwindigkeit 0 "kein Geschwindigkeitsgebot" 1 "0 km/h < v_max <  5 km/h" 2 "5 km/h � v_max < 10km/h" 3 "10 km/h � v_max < 15 km/h" 4 "15 km/h � v_max < 20 km/h" 5 "20 km/h � v_max < 25 km/h" 6 "25 km/h � v_max < 30 km/h" 7 "30 km/h � v_max < 35 km/h" 8 "35 km/h � v_max < 40 km/h" 9 "40 km/h � v_max < 45 km/h" 10 "45 km/h � v_max < 50 km/h" 11 "50 km/h � v_max < 60 km/h" 12 "60 km/h � v_max < 70 km/h" 13 "70 km/h � v_max < 80 km/h" 14 "80 km/h � v_max < 90 km/h" 15 "90 km/h � v_max < 100 km/h" 16 "100 km/h � v_max < 110 km/h" 17 "110 km/h � v_max < 120 km/h" 18 "120 km/h � v_max < 130 km/h" 19 "130 km/h � v_max < 140 km/h" 20 "140 km/h � v_max < 150 km/h" 21 "150 km/h � v_max < 160 km/h" 22 "160 km/h � v_max" 23 " Geschwindigkeitsgebot aufgehoben" 24 "..0x1F ung�ltig" ;
VAL_ 930 PSD_Ges_Geschwindigkeit_Tag_Ende 0 "kein Ende definiert" 1 "Montag" 2 "Dienstag" 3 "Mittwoch" 4 "Donnerstag" 5 "Freitag" 6 "Samstag" 7 "Sonntag" ;
VAL_ 930 PSD_Ges_Geschwindigkeit_Std_Anf 25 "kein Beginn f�r stundenweise Einschr�nkungen" ;
VAL_ 930 PSD_Abz_Geschwindigkeit_Typ 0 "Der Wert im Attribut Geschwindigkeitsbegrenzung entspricht der Geschwindigkeitsklasse von Navteq." 1 "Der Wert im Attribut Geschwindigkeitsbegrenzung entspricht einer explizit angegebenen Begrenzung der Geschwindigkeit" ;
VAL_ 930 PSD_Sys_Tunnel 0 "kein Tunnel oder keine Information verfuegbar" 1 "Tunnel" ;
VAL_ 930 PSD_Abz_Strassenklasse 0 " Rest (Feldweg, Schotter, Privatweg)" 1 "Ortsstra�e" 2 "Bundes-,Landstrasse" 3 "Autobahn" ;
VAL_ 930 PSD_Sys_Bruecke 0 "keine Bruecke oder keine Information verfuegbar" 1 "Bruecke" ;
VAL_ 930 PSD_Ort_Breite_VZ 0 "Nord" 1 "Sued" ;
VAL_ 930 PSD_Sys_Fahrsp_Gegenr 0 "keine Fahrspur" 1 "eine Fahrspur" 2 "mehr als eine Fahrspur" 3 "keine Information verfuegbar" ;
VAL_ 930 PSD_Abz_ADAS_Qualitaet 0 "keine ADAS Qualit�t" 1 "ADAS Qualit�t" ;
VAL_ 930 PSD_Ges_Geschwindigkeit_Std_Ende 25 "kein Ende f�r stundenweise Einschr�nkungen" ;
VAL_ 930 PSD_Abz_Abzweigerichtung 0 "rechts abzweigende Stra�e" 1 "links abzweigende Stra�e" ;
VAL_ 930 PSD_Sys_TMC_Baustelle 0 "keine Baustelle oder keine Information verfuegbar" 1 "Baustelle" ;
VAL_ 930 PSD_Abz_Abzweigewinkel 0 "0�: Stra�e verl�uft gerade aus" 1 "0� < Winkel � 12�" 2 "12� < Winkel � 24�" 3 "24� < Winkel � 36�" 4 "36� < Winkel � 48�" 5 "48� < Winkel � 60�" 6 "60� < Winkel � 72�" 7 "72� < Winkel � 84�" 8 "84� < Winkel � 96�" 9 "96� < Winkel � 108�" 10 "108� < Winkel � 120�" 11 "120� < Winkel � 132�" 12 "132� < Winkel � 144�" 13 "144� < Winkel � 156�" 14 "156� < Winkel � 168�" 15 "168� < Winkel � 180�" ;
VAL_ 930 PSD_Sys_TMC_Stau 0 "kein Stau oder keine Information verfuegbar" 1 "Stau" ;
VAL_ 930 PSD_Ges_alter_Geschw 0 "Kein Geschwindigkeitsgebot" 1 "0 km/h < v_max <  5 km/h" 2 "5 km/h � v_max < 10km/h" 3 "10 km/h � v_max < 15 km/h" 4 "15 km/h � v_max < 20 km/h" 5 "20 km/h � v_max < 25 km/h" 6 "25 km/h � v_max < 30 km/h" 7 "30 km/h � v_max < 35 km/h" 8 "35 km/h � v_max < 40 km/h" 9 "40 km/h � v_max < 45 km/h" 10 "45 km/h � v_max < 50 km/h" 11 "50 km/h � v_max < 60 km/h" 12 "60 km/h � v_max < 70 km/h" 13 "70 km/h � v_max < 80 km/h" 14 "80 km/h � v_max < 90 km/h" 15 "90 km/h � v_max < 100 km/h" 16 "100 km/h � v_max < 110 km/h" 17 "110 km/h � v_max < 120 km/h" 18 "120 km/h � v_max < 130 km/h" 19 "130 km/h � v_max < 140 km/h" 20 "140 km/h � v_max < 150 km/h" 21 "150 km/h � v_max < 160 km/h" 22 "160 km/h � v_max" 23 "Geschwindigkeitsgebot aufgehoben" 24 "..0x1F ung�ltig" ;
VAL_ 930 PSD_Abz_Rampe 0 "Stra�e mit Gegenverkehr" 1 "Auffahrt (Einbahnstr.) " 2 "Abfahrt (Einbahnstr.)" 3 "Einbahnstra�e" ;
VAL_ 930 PSD_Abz_Anfangskruemmung 255 "Gerade" ;
VAL_ 930 PSD_Ges_alter_Geschw_Gespann 0 "alle Fahrzeuge" 1 "PKW mit Gespann" 2 "LKW, Busse, etc." ;
VAL_ 930 PSD_Ges_alter_Geschw_Witter 0 "Witterungsunabh�ngig" 1 "N�sse, Regen, Niederschlag" 2 "Gl�tte" 3 "Nebel" ;
VAL_ 930 PSD_Ges_alter_Geschw_Tag_Anf 0 "kein Beginn definiert" 1 "Montag" 2 "Dienstag" 3 "Mittwoch" 4 "Donnerstag" 5 "Freitag" 6 "Samstag" 7 "Sonntag" ;
VAL_ 930 PSD_Abz_Anfangskruemmung_Vorz 0 "Kr�mmung positiv" 1 "Kr�mmung negativ" ;
VAL_ 930 PSD_Sys_Anfangskruemmung 255 "Gerade" ;
VAL_ 930 PSD_Abz_Endkruemmung 255 "Gerade" ;
VAL_ 930 PSD_Ges_alter_Geschw_Tag_Ende 0 "kein Ende definiert" 1 "Montag" 2 "Dienstag" 3 "Mittwoch" 4 "Donnerstag" 5 "Freitag" 6 "Samstag" 7 "Sonntag" ;
VAL_ 930 PSD_Ges_alter_Geschw_Std_Anf 25 "kein Beginn f�r stundenweise Einschr�nkungen" ;
VAL_ 930 PSD_Sys_Anfangskruemmung_Vorz 0 "Kr�mmung positiv" 1 "Kr�mmung negativ" ;
VAL_ 930 PSD_Abz_Endkruemmung_Vorz 0 "Kr�mmung positiv" 1 "Kr�mmung negativ" ;
VAL_ 930 PSD_Ges_alter_Geschw_Std_Ende 25 "kein Ende f�r stundenweise Einschr�nkungen" ;
VAL_ 930 PSD_Sys_Anfangssteigung 30 "gleich oder mehr als 15 % Steigung" 31 "ung�ltig" ;
VAL_ 930 PSD_Abz_Endsteigung 30 "gleich oder mehr als 15 % Steigung" 31 "ung�ltig" ;
VAL_ 930 PSD_Ges_Ueberholverbot 0 "kein �berholverbot" 1 "alle Fahrzeuge" 2 "�berholverbot f�r PKW mit Gespann" 3 "�berholverbot f�r LKW, Busse, etc." ;
VAL_ 930 PSD_Sys_Anfangssteigung_Vorz 0 "Gef�lle " 1 "Steigung" ;
VAL_ 930 PSD_Abz_Endsteigung_Vorz 0 "Gef�lle" 1 "Steigung" ;
VAL_ 930 PSD_Sys_Ortschaft 0 "au�erhalb der Ortschaft" 1 "innerhalb der Ortschaft" ;
VAL_ 930 PSD_Abz_Fahrspuren 0 "Einbahnstra�e in falscher Richtung" 1 "eine Fahrspur" 2 "zwei Fahrspuren" 3 "mehr als 2 Fahrspuren" ;
VAL_ 930 PSD_Ges_Wechselverkehrszeichen 0 "Kein Wechselverkehrszeichen" 1 "Wechselverkehrszeichen links" 2 "Wechselverkehrszeichen rechts" 3 "Wechselverkehrszeichen links und rechts" 4 "Wechselverkerhszeichen �ber der Fahrbahn" ;
VAL_ 930 PSD_Sys_Digitalisierung 0 "teildigitalisiert" 1 "volldigitalisiert" ;
VAL_ 930 PSD_Sys_Zielfuehrung 0 "Zielfuehrung nicht aktiv" 1 "Zielfuehrung aktiv" ;
VAL_ 930 PSD_Abz_wahrscheinlichster_Pfad 0 "Pfad mit geringer Wahrscheinlichkeit" 1 "wahrscheinlichster Pfad" ;
VAL_ 1528 SAK_Charisma_FahrPr 0 "nicht_belegt" 1 "Programm_1" 2 "Programm_2" 3 "Programm_3" 4 "Programm_4" 5 "Programm_5" 6 "Programm_6" 7 "Programm_7" ;
VAL_ 1528 SAK_Charisma_Status 0 "Init" 1 "verfuegbar" 2 "nicht_verfuegbar" 3 "asynchron_durch_Fahrerwunsch" ;
VAL_ 1528 SAK_Charisma_Umschaltung 0 "Idle" 1 "Erkennung_Umschaltaufforderung" 2 "Steuerbotschaft_nicht_definiert" 3 "Umschaltung_verzoegert" ;
VAL_ 1528 SAK_KD_Fehler 0 "kein_KD_Fehler" 1 "KD_Fehler" ;
VAL_ 1011 SCR_Dosierpumpe_Drehzahl 2047 "Fehler" ;
VAL_ 1011 SCR_Druck 1021 "nicht_verbaut" 1023 "Fehler" ;
VAL_ 1011 SCR_Level_Aktivtank 1021 "nicht_verbaut" 1023 "Fehler" ;
VAL_ 1011 SCR_Level_Passivtank 1021 "nicht_verbaut" 1023 "Fehler" ;
VAL_ 1507 SCR_Heizkreis_3_Strom 253 "nicht_verbaut" 255 "Fehler" ;
VAL_ 1507 SCR_KD_Fehler 0 "kein_KD_Fehler" 1 "KD_Fehler" ;
VAL_ 1507 SCR_Guetesensor 1021 "nicht_verbaut" 1023 "Fehler" ;
VAL_ 1507 SCR_Temp_Aktivtank 255 "Fehler" ;
VAL_ 1507 SCR_Temp_Passivtank 253 "nicht_verbaut" 255 "Fehler" ;
VAL_ 1507 SCR_Leitungsheizung_Strom 255 "Fehler" ;
VAL_ 1507 SCR_Transferpumpe_Strom 253 "nicht_verbaut" 255 "Fehler" ;
VAL_ 1507 SCR_Tankheizung_Strom 255 "Fehler" ;
VAL_ 1508 SCR_Spannungsversorgung_Status 0 "kein_Fehler" 1 "KS-" 2 "KS+" 3 "OC" 4 "OOR+(Ueberspannung)" 5 "OOR-(Unterspannung)" 6 "RC+" 7 "RC-" 8 "KS+/OC" 9 "KS-/OC" 10 "KS-/KS+" 11 "KS-/KS+/OC" 12 "OOR+(FktEinschr_Ueberspg)" 13 "OOR-(FktEinschr_Unterspg)" 14 "frei" 15 "Diagnose_noch_nicht_beendet" ;
VAL_ 1508 SCR_VersorgungSensoren_Status 0 "kein_Fehler" 1 "KS-" 2 "KS+" 3 "OC" 4 "OOR+" 5 "OOR-" 6 "RC+" 7 "RC-" 8 "KS+/OC" 9 "KS-/OC" 10 "KS-/KS+" 11 "KS-/KS+/OC" 12 "frei" 13 "frei" 14 "frei" 15 "Diagnose_noch_nicht_beendet" ;
VAL_ 1508 SCR_Heizkreis_3_Status 0 "kein_Fehler" 1 "KS- (Kurzschluss nach minus)" 2 "KS+ (Kurzschluss nach plus)" 3 "OC (Leitungsunterbrechung)" 4 "OOR+ (Signal zu gross)" 5 "OOR- (Signal zu klein)" 6 "RC+ (Signal unplausibel zu gross)" 7 "RC- (Signal unplausibel zu klein)" 8 "KS+/OC (Kurzschluss nach plus/Unterbrechung)" 9 "KS-/OC  (Kurzschluss nach plus/Unterbrechung)" 10 "KS-/KS+  (Kurzschluss nach minus/plus)" 11 "KS-/KS+/OC (Kurzschluss nach minus/plus/Unterbrechung)" 12 "frei" 13 "frei" 14 "frei" 15 "frei" ;
VAL_ 1508 SCR_Guetesensor_Status 0 "kein_Fehler" 1 "KS- (Kurzschluss nach minus)" 2 "KS+ (Kurzschluss nach plus)" 3 "OC (Leitungsunterbrechung)" 4 "OOR+ (Signal zu gross)" 5 "OOR- (Signal zu klein)" 6 "RC+ (Signal unplausibel zu gross)" 7 "RC- (Signal unplausibel zu klein)" 8 "KS+/OC (Kurzschluss nach plus/Unterbrechung)" 9 "KS-/OC  (Kurzschluss nach plus/Unterbrechung)" 10 "KS-/KS+  (Kurzschluss nach minus/plus)" 11 "KS-/KS+/OC (Kurzschluss nach minus/plus/Unterbrechung)" 12 "frei" 13 "frei" 14 "frei" 15 "frei" ;
VAL_ 1508 SCR_Leitungsheizung_Status 0 "kein_Fehler" 1 "KS- (Kurzschluss nach minus)" 2 "KS+ (Kurzschluss nach plus)" 3 "OC (Leitungsunterbrechung)" 4 "OOR+ (Signal zu gross)" 5 "OOR- (Signal zu klein)" 6 "RC+ (Signal unplausibel zu gross)" 7 "RC- (Signal unplausibel zu klein)" 8 "KS+/OC (Kurzschluss nach plus/Unterbrechung)" 9 "KS-/OC  (Kurzschluss nach plus/Unterbrechung)" 10 "KS-/KS+  (Kurzschluss nach minus/plus)" 11 "KS-/KS+/OC (Kurzschluss nach minus/plus/Unterbrechung)" 12 "frei" 13 "frei" 14 "frei" 15 "frei" ;
VAL_ 1508 SCR_Tankheizung_Status 0 "kein_Fehler" 1 "KS- (Kurzschluss nach minus)" 2 "KS+ (Kurzschluss nach plus)" 3 "OC (Leitungsunterbrechung)" 4 "OOR+ (Signal zu gross)" 5 "OOR- (Signal zu klein)" 6 "RC+ (Signal unplausibel zu gross)" 7 "RC- (Signal unplausibel zu klein)" 8 "KS+/OC (Kurzschluss nach plus/Unterbrechung)" 9 "KS-/OC  (Kurzschluss nach plus/Unterbrechung)" 10 "KS-/KS+  (Kurzschluss nach minus/plus)" 11 "KS-/KS+/OC (Kurzschluss nach minus/plus/Unterbrechung)" 12 "frei" 13 "frei" 14 "frei" 15 "frei" ;
VAL_ 1508 SCR_Druck_Status 0 "kein_Fehler" 1 "KS- (Kurzschluss nach minus)" 2 "KS+ (Kurzschluss nach plus)" 3 "OC (Leitungsunterbrechung)" 4 "OOR+ (Signal zu gross)" 5 "OOR- (Signal zu klein)" 6 "RC+ (Signal unplausibel zu gross)" 7 "RC- (Signal unplausibel zu klein)" 8 "KS+/OC (Kurzschluss nach plus/Unterbrechung)" 9 "KS-/OC  (Kurzschluss nach plus/Unterbrechung)" 10 "KS-/KS+  (Kurzschluss nach minus/plus)" 11 "KS-/KS+/OC (Kurzschluss nach minus/plus/Unterbrechung)" 12 "frei" 13 "frei" 14 "frei" 15 "frei" ;
VAL_ 1508 SCR_Dosierpumpe_Status_Spule 0 "kein_Fehler" 1 "KS-" 2 "KS+" 3 "OC" 4 "OOR+" 5 "OOR-" 6 "RC+(Drehzahl_zu_hoch)" 7 "RC-(Drehzahl_zu_niedrig)" 8 "KS+/OC" 9 "KS-/OC" 10 "KS-/KS+" 11 "KS-/KS+/OC" 12 "KS_zwischen_Phasen" 13 "frei" 14 "frei" 15 "frei" ;
VAL_ 1508 SCR_Transferpumpe_Status 0 "kein_Fehler" 1 "KS- (Kurzschluss nach minus)" 2 "KS+ (Kurzschluss nach plus)" 3 "OC (Leitungsunterbrechung)" 4 "OOR+ (Signal zu gross)" 5 "OOR- (Signal zu klein)" 6 "RC+ (Signal unplausibel zu gross)" 7 "RC- (Signal unplausibel zu klein)" 8 "KS+/OC (Kurzschluss nach plus/Unterbrechung)" 9 "KS-/OC  (Kurzschluss nach plus/Unterbrechung)" 10 "KS-/KS+  (Kurzschluss nach minus/plus)" 11 "KS-/KS+/OC (Kurzschluss nach minus/plus/Unterbrechung)" 12 "frei" 13 "frei" 14 "frei" 15 "frei" ;
VAL_ 1508 SCR_Level_Aktivtank_Status 0 "kein_Fehler" 1 "KS- (Kurzschluss nach minus)" 2 "KS+ (Kurzschluss nach plus)" 3 "OC (Leitungsunterbrechung)" 4 "OOR+ (Signal zu gross)" 5 "OOR- (Signal zu klein)" 6 "RC+ (Signal unplausibel zu gross)" 7 "RC- (Signal unplausibel zu klein)" 8 "KS+/OC (Kurzschluss nach plus/Unterbrechung)" 9 "KS-/OC  (Kurzschluss nach plus/Unterbrechung)" 10 "KS-/KS+  (Kurzschluss nach minus/plus)" 11 "KS-/KS+/OC (Kurzschluss nach minus/plus/Unterbrechung)" 12 "frei" 13 "frei" 14 "frei" 15 "frei" ;
VAL_ 1508 SCR_Level_Passivtank_Status 0 "kein_Fehler" 1 "KS- (Kurzschluss nach minus)" 2 "KS+ (Kurzschluss nach plus)" 3 "OC (Leitungsunterbrechung)" 4 "OOR+ (Signal zu gross)" 5 "OOR- (Signal zu klein)" 6 "RC+ (Signal unplausibel zu gross)" 7 "RC- (Signal unplausibel zu klein)" 8 "KS+/OC (Kurzschluss nach plus/Unterbrechung)" 9 "KS-/OC  (Kurzschluss nach plus/Unterbrechung)" 10 "KS-/KS+  (Kurzschluss nach minus/plus)" 11 "KS-/KS+/OC (Kurzschluss nach minus/plus/Unterbrechung)" 12 "frei" 13 "frei" 14 "frei" 15 "frei" ;
VAL_ 1508 SCR_Temp_Aktivtank_Status 0 "kein_Fehler" 1 "KS- (Kurzschluss nach minus)" 2 "KS+ (Kurzschluss nach plus)" 3 "OC (Leitungsunterbrechung)" 4 "OOR+ (Signal zu gross)" 5 "OOR- (Signal zu klein)" 6 "RC+ (Signal unplausibel zu gross)" 7 "RC- (Signal unplausibel zu klein)" 8 "KS+/OC (Kurzschluss nach plus/Unterbrechung)" 9 "KS-/OC  (Kurzschluss nach plus/Unterbrechung)" 10 "KS-/KS+  (Kurzschluss nach minus/plus)" 11 "KS-/KS+/OC (Kurzschluss nach minus/plus/Unterbrechung)" 12 "frei" 13 "frei" 14 "frei" 15 "frei" ;
VAL_ 1508 SCR_Temp_Passivtank_Status 0 "kein_Fehler" 1 "KS- (Kurzschluss nach minus)" 2 "KS+ (Kurzschluss nach plus)" 3 "OC (Leitungsunterbrechung)" 4 "OOR+ (Signal zu gross)" 5 "OOR- (Signal zu klein)" 6 "RC+ (Signal unplausibel zu gross)" 7 "RC- (Signal unplausibel zu klein)" 8 "KS+/OC (Kurzschluss nach plus/Unterbrechung)" 9 "KS-/OC  (Kurzschluss nach plus/Unterbrechung)" 10 "KS-/KS+  (Kurzschluss nach minus/plus)" 11 "KS-/KS+/OC (Kurzschluss nach minus/plus/Unterbrechung)" 12 "frei" 13 "frei" 14 "frei" 15 "frei" ;
VAL_ 1509 SCR_Ansteuerung_Transferpumpe 0 "nicht_aktiv" 1 "aktiv" ;
VAL_ 1509 SCR_Ansteuerung_Dosierpumpe 0 "nicht_aktiv" 1 "aktiv" ;
VAL_ 1509 SCR_Ansteuerung_Heizkreis_3 0 "nicht_aktiv" 1 "aktiv" ;
VAL_ 1509 SCR_Ansteuerung_Leitungsheizung 0 "nicht_aktiv" 1 "aktiv" ;
VAL_ 1509 SCR_Ansteuerung_Tankheizung 0 "nicht_aktiv" 1 "aktiv" ;
VAL_ 1526 SCR_Steuergeraet_Heizung_Status 0 "kein_Fehler" 1 "Endstufe_Tankheizung_ueberhitzt" 2 "Endstufe_Leitungsheizung_ueberhitzt" 3 "Diagnose_noch_nicht_beendet" ;
VAL_ 1526 SCR_Steuergeraet_Pumpe_Status 0 "kein_Fehler" 1 "Endstufe_Pumpe_ueberhitzt" 2 "Pumpe_blockiert" 3 "Diagnose_noch_nicht_beendet" ;
VAL_ 1526 SCR_Steuergeraet_Relais_Status 0 "kein_Fehler" 1 "KS+ (Ausgang Leistungsrelais) " 2 "KS-/OC (Ausgang Leistungsrelais)" 3 "Diagnose_noch_nicht_beendet" ;
VAL_ 1526 SCR_Steuergeraet_Bus_Status 0 "kein_Fehler" 1 "Bus_Kommunikation_Fehler" 2 "Bus_Kommunikation_Stoerung_(temporaer)" 3 "Diagnose_noch_nicht_beendet" ;
VAL_ 1526 SCR_Steuergeraet_Codierung_St000 0 "kein_Fehler" 1 "Steuergeraet_nicht_codiert" 2 "Steuergeraet_falsch_codiert" 3 "Diagnose_noch_nicht_beendet" ;
VAL_ 1526 SCR_Steuergeraet_Datensatz_St001 0 "kein_Fehler" 1 "ungueltiger_Datensatz" 2 "unplausibeler_Datensatz" 3 "Diagnose_noch_nicht_beendet" ;
VAL_ 1526 SCR_Steuergeraet_Defekt_Status 0 "kein_Fehler" 1 "Steuergeraet_defekt" 2 "Steuergeraet_Stoerung_(temporaer)" 3 "Diagnose_noch_nicht_beendet" ;
VAL_ 1510 SCR_CAL_ID_Name_01 48 "Fehler" ;
VAL_ 1510 SCR_CAL_ID_Name_02 48 "Fehler" ;
VAL_ 1510 SCR_CAL_ID_Name_03 48 "Fehler" ;
VAL_ 1512 SCR_CAL_ID_Leer 48 "Fehler" ;
VAL_ 133 SCU_Ue_Winkel_ADS 4094 "Init" 4095 "Fehler" ;
VAL_ 133 SCU_VZ_Ue_Winkel_ADS 0 "positiv" 1 "negativ" ;
VAL_ 133 SCU_Soll_Ue_Winkel 2046 "Init" 2047 "Fehler" ;
VAL_ 133 SCU_max_Gradient 511 "Fehler" ;
VAL_ 133 SCU_VZ_Soll_Ue_Winkel 0 "positiv" 1 "negativ" ;
VAL_ 133 SCU_Status 0 "betriebsbereit" 1 "Init" 2 "sichere �bersetzung" 3 "Motorsperre verriegelt" 4 "Synchronisierung l�uft" ;
VAL_ 133 SCU_KD_Fehler 0 "kein_KD_Fehler" 1 "KD_Fehler" ;
VAL_ 784 SCU_Warnlampe 0 "keine Anzeige (SCU_Status=0x0)" 1 "Warnlampe an (SCU_Status=0x1, 0x2, 0x3)" 2 "reserviert" 3 "Warnlampe Synchronisation (SCU_Status=0x4)" ;
VAL_ 784 SCU_Warnungen 0 "keine Anzeige (SCU_Status=0x0, 0x1)" 1 "ADS Stoerung (SCU_Status=0x2, 0x3)" 2 "ADS Initialisierung (SCU_Status=0x4)" 3 "reserviert" ;
VAL_ 784 SCU_Charisma_FahrPr 0 "nicht_belegt" 1 "Programm_1" 2 "Programm_2" 3 "Programm_3" 4 "Programm_4" 5 "Programm_5" 6 "Programm_6" 7 "Programm_7" ;
VAL_ 784 SCU_Charisma_Status 0 "Init (SCU_Status=0x1)" 1 "idle (SCU_Status=0x0, 0x4)" 2 "nicht verfuegbar (SCU_Status=0x2, 0x3)" 3 "reserviert" ;
VAL_ 784 SCU_Charisma_Umschaltung 0 "Idle" 1 "Erkennung_Umschaltaufforderung" 2 "Steuerbotschaft_nicht_definiert" 3 "Umschaltung_verzoegert" ;
VAL_ 1313 STH_Funk_ein 0 "kein Funkbefehl zum Einschalten" 1 "Funkbefehl zum Einschalten erhalten" ;
VAL_ 1313 STH_Funk_aus 0 "kein Funkbefehl" 1 "Funkbefehl zum Ausschalten erhalten" ;
VAL_ 1313 STH_Zusatzheizung 0 "Zuheizer aus" 1 "Zuheizer ein" ;
VAL_ 1313 STH_LED 0 "keine R�ckmeldung" 1 "Rueckmeldung Standheizung in Betrieb" ;
VAL_ 1313 STH_Geblaese 0 "kein Einschaltbefehl an die Klimaanlage, Gebl�se" 1 "Einschaltbefehl an die Klimaanlage, Gebl�se" ;
VAL_ 1313 STH_EKP_Anst 0 "EKP nicht ansteuern" 1 "EKP ansteuern" ;
VAL_ 1313 STH_Start_folgt 0 "kein_Start_folgt" 1 "Start_folgt" ;
VAL_ 1313 STH_Ventil_Status 0 "Ventil_offen__grosser_Kreislauf" 1 "Ventil_geschlossen__kleiner_Kreislauf" ;
VAL_ 1313 STH_Fehlerstatus 0 "kein Fehler" 1 "Batterie Low" 2 "Fuel Low" 3 "Hardware defekt" 4 "Heizgeraet verriegelt" ;
VAL_ 1313 STH_Wassertemp 254 "Init" 255 "Fehler" ;
VAL_ 1313 STH_Motorvorwaermung 0 "keine Motorvorw�rmung erfolgt" 1 "Aufheizung mit Motorvorw�rmung erfolgt" ;
VAL_ 1313 STH_war_aktiv 0 "war inaktiv" 1 "Standheizung war letzte halbe Stunde aktiv" ;
VAL_ 1313 STH_KVS_Ueberlauf 0 "kein �berlauf" 1 "Kraftstoffverbrauchssignal, mindestens ein �berlauf hat stattgefunden" ;
VAL_ 1313 STH_KD_Fehler 0 "kein_KD_Fehler" 1 "KD_Fehler" ;
VAL_ 1172 STS_Car_not_under_theft 0 "false" 1 "true" ;
VAL_ 1172 STS_Car_under_theft 0 "false" 1 "true" ;
VAL_ 1172 STS_Anlassersperre 0 "inaktiv" 1 "aktiv" ;
VAL_ 1172 STS_Typencodierung 0 "Basis" 1 "E-Gas" 4 "Sonderschutz" ;
VAL_ 1172 STS_KD_Fehler 0 "kein_KD_Fehler" 1 "KD_Fehler" ;
VAL_ 1172 STS_Standlicht 0 "inaktiv" 1 "aktiv" ;
VAL_ 1172 STS_Fahrlicht 0 "inaktiv" 1 "aktiv" ;
VAL_ 1172 STS_Alarm_still 0 "inaktiv" 1 "aktiv" ;
VAL_ 1172 STS_Texte 0 "kein_Text" 1 "Text_01" 2 "Text_02" 3 "Text_03" 4 "Text_04" 5 "Text_05" 6 "Text_06" 7 "Text_07" 8 "Text_08" 9 "Text_09" 10 "Text_10" 11 "Text_11" 12 "Text_12" 13 "Text_13" 14 "Init" 15 "Fehler" ;
VAL_ 1172 STS_Laderelais 0 "Relais_offen" 1 "Relais_geschlossen" ;
VAL_ 1172 STS_Summer 0 "inaktiv" 1 "aktiv" ;
VAL_ 1172 STS_Notstart 0 "kein_Notstart" 1 "Notstart" ;
VAL_ 1172 STS_Signalhorn 0 "inaktiv" 1 "aktiv" ;
VAL_ 1172 STS_Leerlaufschaltung 0 "Leerlaufschaltung_Aus" 1 "Leerlaufschaltung_Ein" ;
VAL_ 1413 SI_Int_CAN_gespiegelt 0 "interner CAN getrennt" 1 "interner CAN gespiegelt" ;
VAL_ 1413 SI_CAN_Komfort_Sleep 0 "keine_Busruhe" 1 "Busruhe" ;
VAL_ 1413 SI_CAN_Dashboard_Sleep 0 "keine_Busruhe" 1 "Busruhe" ;
VAL_ 1413 SI_CAN_Antrieb_Sleep 0 "keine_Busruhe" 1 "Busruhe" ;
VAL_ 1413 SI_Infotainment_Sleep 0 "keine_Busruhe" 1 "Busruhe" ;
VAL_ 1413 SI_CAN_Extended_Sleep 0 "keine_Busruhe" 1 "Busruhe" ;
VAL_ 1413 SI_Fahrwerk_Sleep 0 "keine_Busruhe" 1 "Busruhe" ;
VAL_ 1413 SI_Diagnose_Aktiv 0 "inaktiv" 1 "aktiv" ;
VAL_ 1413 SI_QRS_Mode 0 "QRS_Messmodus_nicht_aktiv" 1 "QRS_Messmodus_aktiv" ;
VAL_ 1413 SI_T_Mode 0 "Transportmodus_nicht_aktiv" 1 "Transportmodus_aktiv" ;
VAL_ 1413 SI_NWDF 0 "Ueberwachung_nicht_freigegeben" 1 "Ueberwachung_freigegeben" ;
VAL_ 1413 SI_NWDF_gueltig 0 "NWDF_wird_nicht_unterstuetzt" 1 "NWDF_wird_unterstuetzt" ;
VAL_ 1413 SI_Sammelfehler 0 "kein_Sammelfehler" 1 "Sammelfehler" ;
VAL_ 1413 GW_KD_Fehler 0 "kein_KD_Fehler" 1 "KD_Fehler" ;
VAL_ 1413 SI_MOST_Status 0 "MOST_sleep_(Licht_AUS)" 1 "MOST_aktiv_(Kommunikation_moeglich)" ;
VAL_ 1413 SI_Sammel_SG_Fehler 61 "Reserviert" 62 "Overflow" ;
VAL_ 1413 SI_MO_WU 0 "kein Wakeup angefordert" 1 "Wakeup MED9 angefordert" ;
VAL_ 786 FAS_Wunschgeschw 1022 "keine Anzeige" 1023 "nicht definiert" ;
VAL_ 786 FAS_Status_Prim_Anz 0 "Symbol nicht beleuchtet" 1 "Farbe 1 (typisch 'gr�n')" 2 "Farbe 2 (typisch 'rot')" 3 "Farbe 3 (typisch 'gelb')" ;
VAL_ 786 FAS_Texte_Primaeranz 0 "keine Anzeige " 1 "ACC nicht verfuegbar !" 2 "Auto_Auto_ _ _" 3 "Auto_ _Auto_ _" 4 "Auto_ _ _Auto_" 5 "Auto_ _ _ _Auto" 6 "Auto_Auto_ _ _ Gong (durchgestrichen)" 7 "Auto_ _Auto_ _ Gong (durchgestrichen)" 8 "Auto_ _ _Auto_ Gong (durchgestrichen)" 9 "Auto_ _ _ _Auto Gong (durchgestrichen)" 10 "ACC bereit" 11 "keine Abstandsregelung" 12 "ACC Sensor Sicht !" 13 "ACC nicht verfuegbar" 14 "o  o  o" 15 "Hochschalten" 16 "ESP Eingriff" 17 "Herunterschalten" 18 "Parkbremse !" 19 "Geschwindigkeitsgrenze" 20 "Waehlhebelposition !" 21 "VDA ACC-Symbol YYY km/h / mph" 22 "Tempolimit XXX km/h / mph" 23 "Kurve XXX km/h / mph" 24 "ACC Abschaltung" 25 "Symbol 'Eieruhr'" 26 "!" 27 "--- km/h / mph" 28 "XXX km/h / mph (Schriftart 2)" 29 "Lenkradwinkel" 30 "Anfahren bestaetigen" 31 "Fahrzeug verloren" 32 "Im Stand nicht moeglich" 33 "Ungueltiger Anfahrbefehl" 34 "Tuer offen !" 35 "Fahrer Gurtschloss offen !" 36 "Schalthebelposition !" 37 "Drehzahl !" 38 "Kurvenassistent aus" 39 "Tempolimit aus" 40 "Abbiegeassistent" 41 "Ortsanfang XXX km/h / mph" 42 "Ortsende XXX km/h / mph" 43 "Tempolimit Ende XXX km/h / mph" 44 "HDC aktiv" 45 "braking guard Bremsruck" 46 "braking guard aus " 47 "braking guard aus" 48 "Uebernehmen !" 49 "Steigung zu gross" 50 "Stehendes Objekt voraus" 51 "SET / 'GRA Symbol'___xxx km/h / mph" 52 "SET / 'GRA Symbol' xxx km/h / mph" 53 "ACC aus" 54 "ACC startet" 55 "ACC reinigen" 56 "ACC Fehler" 57 "ACC haelt an !" 58 "Bremse betaetigen !" 59 "Kupplung betaetigt" 60 "LIM AUS" 61 "LIM AKTIV " 62 "LIM PASSIV" 63 "LIM FEHLER" 64 "Bremse ueberhitzt !" 65 "Bremse haelt !" 66 "ESP PASSIV !" ;
VAL_ 786 FAS_Status_Anzeige 0 "ACC/GRA Hauptschalter aus" 1 "ACC in Init (nicht bei GRA)" 2 "ACC/GRA passiv" 3 "ACCGRA aktiv" 4 "ACC/GRA im Hintergrund (�bertreten)" 5 "frei" 6 "ACC reversibel aus (nicht bei GRA)" 7 "ACC/GRA irreversibel aus" ;
VAL_ 270 TSK_ax_Getriebe 511 "nicht definiert" ;
VAL_ 270 TSK_Freig_WU 0 "TSK_Uebersetzungswunsch nicht freigegeben" 1 "TSK_Uebersetzungswunsch freigegeben" ;
VAL_ 270 TSK_Limiter_aktiv 0 "Speed Limiter ist nicht aktiv" 1 "Speed Limiter aktiv und regelt" ;
VAL_ 270 TSK_Status_GRA_ACC_02 0 "nicht verbaut / kein ACC zul�ssig" 1 "GRA / ACC aktiv " 2 "GRA / ACC vom Fahrer �bersteuert" 3 "Fehler, GRA/ACC nicht m�glich " ;
VAL_ 273 TSK_QBit_Steigung 0 "gueltiger_Wert" 1 "Ersatz_Init_oder_Fehlerwert" ;
VAL_ 273 TSK_Status_GRA_ACC_01 0 "nicht_verbaut_kein_ACC_zulaessig" 1 "GRA_ACC_aktiv" 2 "GRA_ACC_vom_Fahrer_uebersteuert" 3 "Fehler_GRA_ACC_nicht_moeglich" ;
VAL_ 273 TSK_Fahrzeugmasse 31 "Fehler" ;
VAL_ 273 TSK_QBit_Fahrzeugmasse 0 "gueltiger_Wert" 1 "Ersatz_Init_oder_Fehlerwert" ;
VAL_ 273 TSK_Fahrzeugmasse_02 255 "Fehler" ;
VAL_ 273 TSK_Steigung 255 "Fehler" ;
VAL_ 273 TSK_Getriebeinfo 0 "Handschalter" 1 "AL_AQ_Getriebe" 2 "DL_DQ_Getriebe" 3 "CVT_Getriebe" ;
VAL_ 273 TSK_Codierung_ACC 0 "TSK_korrekt_auf_kein_ACC_codiert_oder_TSK_falsch_codiert" 1 "TSK_korrekt_auf_ACC_codiert" ;
VAL_ 273 TSK_Zwangszusch_ESP 0 "keine_ESP_ASR_Beeinflussung" 1 "ESP_ASR_Beeinflussung" ;
VAL_ 273 TSK_Freig_Verzoeg_Anf 0 "Verzoegerungsanforderung_nicht_freigegeben" 1 "Verzoegerungsanforderung_freigegeben" ;
VAL_ 1414 WH_KD_Fehler 0 "kein_KD_Fehler" 1 "KD_Fehler" ;
VAL_ 266 TSK_amax_moeglich 511 "nicht definiert" ;
VAL_ 268 TSK_Anhalten 0 "kein Anhalten gew�nscht" 1 "Anhalten gew�nscht" ;
VAL_ 268 TSK_Standby_Anf_ESP 0 "keine_Standby_Anforderung" 1 "Standby_Anforderung" ;
VAL_ 268 TSK_Verzoeg_Anf 255 "nicht_definiert" ;
